VERSION ""

NS_ :

BS_:

BU_: ARS_FD WPC_FD WPC2_FD SCM_FD SHVU_FRNT_FD GW_SAU_DRV_FD GW_PSU_AST_FD GW_PSU_3RD_FD RCS_FD GW_PSU_RL_FD RCM_FD SHVU_3RD_FD SHVU_RR_FD PSB_FD ATS_FD GW_PSU_RR_FD SHVU_RL_FD RWPC_FD CGW_CCU OHCL_FD SHVU_REAR_FD BLTN_CAM_FD SGU_FD GW_PSU_DRV_FD FCS_FD

BO_ 3221225472 VECTOR__INDEPENDENT_SIG_MSG: 0 Vector__XXX
 SG_ dummy_GST_BLTN_CAM_Byte : 0|64@1+ (1,0) [0|0] "" Vector__XXX

BO_ 1 dummy_795_GST_BLTN_CAM: 8 Vector__XXX

BO_ 1941 dummy_GST_BLTN_CAM: 8 Vector__XXX
 SG_ dummy_GST_BLTN_CAM_Byte : 0|64@1+ (1,0) [0|0] ""  BLTN_CAM_FD

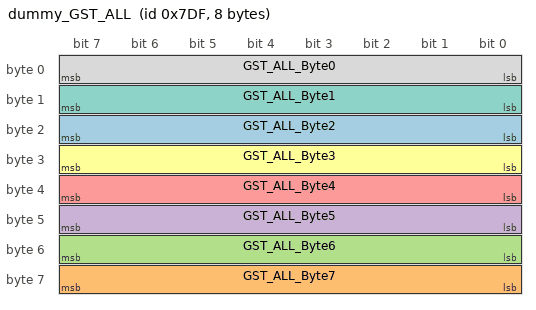
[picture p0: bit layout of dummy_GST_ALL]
BO_ 2015 dummy_GST_ALL: 8 CGW_CCU
 SG_ GST_ALL_Byte2 : 16|8@1+ (1,0) [0|0] "" Vector__XXX
 SG_ GST_ALL_Byte7 : 56|8@1+ (1,0) [0|0] "" Vector__XXX
 SG_ GST_ALL_Byte6 : 48|8@1+ (1,0) [0|0] ""  ARS_FD,ATS_FD,CGW_CCU,FCS_FD,GW_PSU_3RD_FD,GW_PSU_AST_FD,GW_PSU_DRV_FD,GW_PSU_RL_FD,GW_PSU_RR_FD,GW_SAU_DRV_FD,OHCL_FD,PSB_FD,RCM_FD,RCS_FD,RWPC_FD,SCM_FD,SGU_FD,SHVU_3RD_FD,SHVU_FRNT_FD,SHVU_REAR_FD,SHVU_RL_FD,SHVU_RR_FD,WPC2_FD,WPC_FD
 SG_ GST_ALL_Byte5 : 40|8@1+ (1,0) [0|0] ""  ARS_FD,ATS_FD,CGW_CCU,FCS_FD,GW_PSU_3RD_FD,GW_PSU_AST_FD,GW_PSU_DRV_FD,GW_PSU_RL_FD,GW_PSU_RR_FD,GW_SAU_DRV_FD,OHCL_FD,PSB_FD,RCM_FD,RCS_FD,RWPC_FD,SCM_FD,SGU_FD,SHVU_3RD_FD,SHVU_FRNT_FD,SHVU_REAR_FD,SHVU_RL_FD,SHVU_RR_FD,WPC2_FD,WPC_FD
 SG_ GST_ALL_Byte4 : 32|8@1+ (1,0) [0|0] ""  ARS_FD,ATS_FD,CGW_CCU,FCS_FD,GW_PSU_3RD_FD,GW_PSU_AST_FD,GW_PSU_DRV_FD,GW_PSU_RL_FD,GW_PSU_RR_FD,GW_SAU_DRV_FD,OHCL_FD,PSB_FD,RCM_FD,RCS_FD,RWPC_FD,SCM_FD,SGU_FD,SHVU_3RD_FD,SHVU_FRNT_FD,SHVU_REAR_FD,SHVU_RL_FD,SHVU_RR_FD,WPC2_FD,WPC_FD
 SG_ GST_ALL_Byte3 : 24|8@1+ (1,0) [0|0] ""  ARS_FD,ATS_FD,CGW_CCU,FCS_FD,GW_PSU_3RD_FD,GW_PSU_AST_FD,GW_PSU_DRV_FD,GW_PSU_RL_FD,GW_PSU_RR_FD,GW_SAU_DRV_FD,OHCL_FD,PSB_FD,RCM_FD,RCS_FD,RWPC_FD,SCM_FD,SGU_FD,SHVU_3RD_FD,SHVU_FRNT_FD,SHVU_REAR_FD,SHVU_RL_FD,SHVU_RR_FD,WPC2_FD,WPC_FD
 SG_ GST_ALL_Byte1 : 8|8@1+ (1,0) [0|0] ""  ARS_FD,ATS_FD,CGW_CCU,FCS_FD,GW_PSU_3RD_FD,GW_PSU_AST_FD,GW_PSU_DRV_FD,GW_PSU_RL_FD,GW_PSU_RR_FD,GW_SAU_DRV_FD,OHCL_FD,PSB_FD,RCM_FD,RCS_FD,RWPC_FD,SCM_FD,SGU_FD,SHVU_3RD_FD,SHVU_FRNT_FD,SHVU_REAR_FD,SHVU_RL_FD,SHVU_RR_FD,WPC2_FD,WPC_FD
 SG_ GST_ALL_Byte0 : 0|8@1+ (1,0) [0|0] ""  ARS_FD,ATS_FD,BLTN_CAM_FD,CGW_CCU,FCS_FD,GW_PSU_3RD_FD,GW_PSU_AST_FD,GW_PSU_DRV_FD,GW_PSU_RL_FD,GW_PSU_RR_FD,GW_SAU_DRV_FD,OHCL_FD,PSB_FD,RCM_FD,RCS_FD,RWPC_FD,SCM_FD,SGU_FD,SHVU_3RD_FD,SHVU_FRNT_FD,SHVU_REAR_FD,SHVU_RL_FD,SHVU_RR_FD,WPC2_FD,WPC_FD

BO_ 1949 dummy_BLTN_CAM_GST: 8 BLTN_CAM_FD
 SG_ dummy_BLTN_CAM_GST_Byte : 0|64@1- (1,0) [0|0] "" Vector__XXX

BO_ 956 BLTN_CAM_FD_02_200ms: 24 BLTN_CAM_FD
 SG_ BLTN_CAM_FD_Crc2Val : 0|16@1+ (1,0) [0|0] "" Vector__XXX
 SG_ BLTN_CAM_Set_EV_BfrTime : 102|5@1+ (1,0) [0|0] ""  CGW_CCU
 SG_ BLTN_CAM_Set_EV_AftTime : 107|5@1+ (1,0) [0|0] ""  CGW_CCU
 SG_ BLTN_CAM_Set_Drv_TML_Int : 112|4@1+ (1,0) [0|0] ""  CGW_CCU
 SG_ BLTN_CAM_SenSet_DEV : 116|4@1+ (1,0) [0|0] ""  CGW_CCU
 SG_ BLTN_CAM_SenSet_PEV : 120|4@1+ (1,0) [0|0] ""  CGW_CCU
 SG_ BLTN_CAM_Set_FR_Ver_Pos : 128|5@1+ (1,0) [0|0] ""  CGW_CCU
 SG_ BLTN_CAM_Set_RR_Ver_Pos : 133|5@1+ (1,0) [0|0] ""  CGW_CCU
 SG_ BLTN_CAM_Set_PEV_AppNoti : 138|2@1+ (1,0) [0|0] ""  CGW_CCU
 SG_ BLTN_CAM_Set_WiFi_AutoOn : 140|2@1+ (1,0) [0|0] ""  CGW_CCU
 SG_ BLTN_CAM_StrgPropSet : 142|4@1+ (1,0) [0|0] ""  CGW_CCU
 SG_ BLTN_CAM_File_DEL_CPY_Op_State : 146|4@1+ (1,0) [0|0] ""  CGW_CCU
 SG_ BLTN_CAM_File_DEL_CPY_NumTot : 150|16@1+ (1,0) [0|0] ""  CGW_CCU
 SG_ BLTN_CAM_FD_AlvCnt2Val : 16|8@1+ (1,0) [0|0] "" Vector__XXX
 SG_ BLTN_CAM_File_DEL_CPYed_Num : 166|16@1+ (1,0) [0|0] ""  CGW_CCU
 SG_ BLTN_CAM_Set_PMD : 24|2@1+ (1,0) [0|0] ""  CGW_CCU
 SG_ BLTN_CAM_Set_PMDEV : 26|2@1+ (1,0) [0|0] ""  CGW_CCU
 SG_ BLTN_CAM_RanSet_PMDR : 28|4@1+ (1,0) [0|0] ""  CGW_CCU
 SG_ BLTN_CAM_MaxRanSet_PMDR : 32|4@1+ (1,0) [0|0] ""  CGW_CCU
 SG_ BLTN_CAM_Set_PMDTime : 36|8@1+ (1,0) [0|0] ""  CGW_CCU
 SG_ BLTN_CAM_RecSet_OWD : 64|2@1+ (1,0) [0|0] ""  CGW_CCU
 SG_ BLTN_CAM_RecSet_DEV : 66|2@1+ (1,0) [0|0] ""  CGW_CCU
 SG_ BLTN_CAM_RecSet_OWP : 68|2@1+ (1,0) [0|0] ""  CGW_CCU
 SG_ BLTN_CAM_RecSet_PEV : 70|2@1+ (1,0) [0|0] ""  CGW_CCU
 SG_ BLTN_CAM_AudRec_Set : 72|2@1+ (1,0) [0|0] ""  CGW_CCU
 SG_ BLTN_CAM_Set_Tim_Stm : 74|2@1+ (1,0) [0|0] ""  CGW_CCU
 SG_ BLTN_CAM_Set_Spd_Stm : 76|2@1+ (1,0) [0|0] ""  CGW_CCU
 SG_ BLTN_CAM_Set_Locatn_Stm : 78|2@1+ (1,0) [0|0] ""  CGW_CCU
 SG_ BLTN_CAM_Set_TrnSig_Stm : 80|2@1+ (1,0) [0|0] ""  CGW_CCU
 SG_ BLTN_CAM_Set_AclBrk_Stm : 82|2@1+ (1,0) [0|0] ""  CGW_CCU
 SG_ BLTN_CAM_Set_GearPos_Stm : 84|2@1+ (1,0) [0|0] ""  CGW_CCU
 SG_ BLTN_CAM_Set_EVSen_Stm : 86|2@1+ (1,0) [0|0] ""  CGW_CCU
 SG_ BLTN_CAM_Set_StrAngl_Stm : 88|2@1+ (1,0) [0|0] ""  CGW_CCU
 SG_ BLTN_CAM_Set_EV_RecMaxTime : 90|2@1+ (1,0) [0|0] ""  CGW_CCU
 SG_ BLTN_CAM_Set_PrkTime : 94|8@1+ (1,0) [0|0] "Hour"  CGW_CCU

BO_ 274 HU_USM_02_00ms: 32 CGW_CCU
 SG_ HU_USM_Crc2Val : 0|16@1+ (1,0) [0|0] "" Vector__XXX
 SG_ CF_AVN_CluRheostatLvl : 113|5@1+ (1,0) [0|0] "" Vector__XXX
 SG_ CF_AVN_EVReset : 118|2@1+ (1,0) [0|0] "" Vector__XXX
 SG_ CF_AVN_UnitReset : 120|2@1+ (1,0) [0|0] "" Vector__XXX
 SG_ CF_AVN_IcyRoadWarn : 122|2@1+ (1,0) [0|0] "" Vector__XXX
 SG_ CF_AVN_CluServiceReminderReset : 124|2@1+ (1,0) [0|0] "" Vector__XXX
 SG_ CF_AVN_CluUSMReset : 126|2@1+ (1,0) [0|0] ""  ARS_FD,ATS_FD,BLTN_CAM_FD,GW_PSU_3RD_FD,GW_PSU_AST_FD,GW_PSU_DRV_FD,GW_PSU_RL_FD,GW_PSU_RR_FD,GW_SAU_DRV_FD,RCM_FD,RWPC_FD,SGU_FD,SHVU_FRNT_FD,SHVU_REAR_FD,SHVU_RL_FD,SHVU_RR_FD,WPC2_FD,WPC_FD
 SG_ C_HCIMSWeightNValueSet : 128|4@1+ (1,0) [0|0] "" Vector__XXX
 SG_ C_HCIMSHeightNvalueSet : 132|4@1+ (1,0) [0|0] "" Vector__XXX
 SG_ CF_AVN_HCIMSButtonCommand : 136|4@1+ (1,0) [0|0] "" Vector__XXX
 SG_ C_HCIMSSitHeightNValueSet : 140|4@1+ (1,0) [0|0] "" Vector__XXX
 SG_ CF_AVN_BodySpprtSet : 152|2@1+ (1,0) [0|0] ""  GW_PSU_DRV_FD,GW_SAU_DRV_FD
 SG_ HU_USM_AlvCnt2Val : 16|8@1+ (1,0) [0|0] "" Vector__XXX
 SG_ CF_AVN_AirSptTimeNValueSet : 161|3@1+ (1,0) [0|0] ""  GW_SAU_DRV_FD
 SG_ CF_AVN_AirSptStrNValue : 164|2@1+ (1,0) [0|0] ""  GW_SAU_DRV_FD
 SG_ CF_AVN_SeatDrvModNValueSet : 166|2@1+ (1,0) [0|0] ""  GW_PSU_DRV_FD,GW_SAU_DRV_FD
 SG_ C_SmrtSldngDrNValueSet : 176|3@1+ (1,0) [0|0] "" Vector__XXX
 SG_ CF_AVN_TurboPressureUnit : 179|3@1+ (1,0) [0|0] "" Vector__XXX
 SG_ CF_AVN_CluTorqueUnit : 182|2@1+ (1,0) [0|0] "" Vector__XXX
 SG_ CF_AVN_MoodLpRedNValueSet : 192|10@1+ (1,0) [0|0] "" Vector__XXX
 SG_ CF_AVN_MoodLpGreenNValueSet : 202|10@1+ (1,0) [0|0] "" Vector__XXX
 SG_ CF_AVN_MoodLpBlueNValueSet : 212|10@1+ (1,0) [0|0] "" Vector__XXX
 SG_ CF_AVN_MoodLpBrightNValueSet : 223|9@1+ (1,0) [0|0] "" Vector__XXX
 SG_ CF_AVN_HBANValueSet : 232|2@1+ (1,0) [0|0] "" Vector__XXX
 SG_ CF_AVN_IFSActVehSpd_Set : 234|4@1+ (1,0) [0|0] "" Vector__XXX
 SG_ C_MoodLpDrivingNValue : 238|2@1+ (1,0) [0|0] "" Vector__XXX
 SG_ HU_DrivingPostureAssistUSMSet : 24|4@1+ (1,0) [0|0] "" Vector__XXX
 SG_ C_MoodLPDrivemodeNValue : 240|2@1+ (1,0) [0|0] "" Vector__XXX
 SG_ CF_AVN_SVMAutoOnNvalueSet : 242|2@1+ (1,0) [0|0] "" Vector__XXX
 SG_ CF_AVN_DAW_LVDANValueSet : 244|2@1+ (1,0) [0|0] "" Vector__XXX
 SG_ CF_AVN_Clu3dDepthSet : 248|3@1+ (1,0) [0|0] "" Vector__XXX
 SG_ C_MoodLpFadeNValue : 251|2@1+ (1,0) [0|0] ""  ATS_FD
 SG_ HU_DrvCushAirSprtUSMSet : 28|3@1+ (1,0) [0|0] "" Vector__XXX
 SG_ HU_AstCushAirSprtUSMSet : 31|3@1+ (1,0) [0|0] "" Vector__XXX
 SG_ HU_DrvStrchMassageSwSet : 34|2@1+ (1,0) [0|0] "" Vector__XXX
 SG_ HU_DrvStrchMassageModeUSMSet : 36|3@1+ (1,0) [0|0] "" Vector__XXX
 SG_ HU_DrvStrchMassageStrengthUSMSet : 39|3@1+ (1,0) [0|0] "" Vector__XXX
 SG_ HU_DrvStrchMassageTimeUSMSet : 42|3@1+ (1,0) [0|0] "" Vector__XXX
 SG_ HU_AstStrchMassageSwSet : 45|2@1+ (1,0) [0|0] "" Vector__XXX
 SG_ HU_AstStrchMassageModeUSMSet : 47|3@1+ (1,0) [0|0] "" Vector__XXX
 SG_ HU_AstStrchMassageStrengthUSMSet : 50|3@1+ (1,0) [0|0] "" Vector__XXX
 SG_ HU_AstStrchMassageTimeUSMSet : 53|3@1+ (1,0) [0|0] "" Vector__XXX
 SG_ CF_AVN_CluWelcomeSnd : 64|2@1+ (1,0) [0|0] "" Vector__XXX
 SG_ CF_AVN_CluServiceReminderSet : 72|2@1+ (1,0) [0|0] "" Vector__XXX
 SG_ CF_AVN_CluTransmissionDisp : 74|2@1+ (1,0) [0|0] "" Vector__XXX
 SG_ CF_AVN_CluWiperLight : 76|2@1+ (1,0) [0|0] "" Vector__XXX
 SG_ CF_AVN_CluRoadInfoGuide : 78|2@1+ (1,0) [0|0] "" Vector__XXX
 SG_ CF_AVN_CluUserSettingPeriod : 81|7@1+ (1,0) [0|0] "" Vector__XXX
 SG_ CF_AVN_CluFuelEconUnit_mi : 91|2@1+ (1,0) [0|0] "" Vector__XXX
 SG_ CF_AVN_CluFuelEconUnit_km : 93|2@1+ (1,0) [0|0] "" Vector__XXX
 SG_ CF_AVN_CluUserSettingDistance : 95|17@1+ (1,0) [0|0] "" Vector__XXX

BO_ 686 HU_Car_01_200ms: 16 CGW_CCU
 SG_ HU_Car_Crc1Val : 0|16@1+ (1,0) [0|0] "" Vector__XXX
 SG_ HU_Car_AlvCnt1Val : 16|8@1+ (1,0) [0|0] "" Vector__XXX
 SG_ HU_MKBD_ModeSwitch : 66|2@1+ (1,0) [0|0] "" Vector__XXX
 SG_ HU_VehiclePwr : 68|4@1+ (1,0) [0|0] ""  BLTN_CAM_FD,SGU_FD
 SG_ HU_BtnShowReq : 72|3@1+ (1,0) [0|0] "" Vector__XXX
 SG_ HU_ADMSettingState : 75|3@1+ (1,0) [0|0] "" Vector__XXX
 SG_ HU_PwrState : 80|4@1+ (1,0) [0|0] ""  BLTN_CAM_FD
 SG_ HU_LCDState : 84|3@1+ (1,0) [0|0] "" Vector__XXX

BO_ 957 BLTN_CAM_FD_STAT_01_200ms: 24 BLTN_CAM_FD
 SG_ BLTN_CAM_FD_STAT_Crc1Val : 0|16@1+ (1,0) [0|0] "" Vector__XXX
 SG_ BLTN_CAM_Prk_Oprable_Time : 100|8@1+ (1,0) [0|0] "Hour"  CGW_CCU
 SG_ BLTN_CAM_Prk_Oprable_Time_Max : 108|8@1+ (1,0) [0|0] "Hour"  CGW_CCU
 SG_ BLTN_CAM_AuxBat_Conn_State : 116|2@1+ (1,0) [0|0] ""  CGW_CCU
 SG_ BLTN_CAM_AuxBat_CapPer : 118|7@1+ (1,0) [0|0] "%"  CGW_CCU
 SG_ BLTN_CAM_SWVerMajor : 128|7@1+ (1,0) [0|0] ""  CGW_CCU
 SG_ BLTN_CAM_SWVerMinor1 : 136|7@1+ (1,0) [0|0] ""  CGW_CCU
 SG_ BLTN_CAM_SWVerMinor2 : 144|7@1+ (1,0) [0|0] ""  CGW_CCU
 SG_ BLTN_CAM_SWVerMinor3 : 152|7@1+ (1,0) [0|0] ""  CGW_CCU
 SG_ BLTN_CAM_FD_STAT_AlvCnt1Val : 16|8@1+ (1,0) [0|0] "" Vector__XXX
 SG_ BLTN_CAM_SD_Card_Manufacturer : 160|3@1+ (1,0) [0|0] ""  CGW_CCU
 SG_ BLTN_CAM_SD_Card_Cap_Class : 163|3@1+ (1,1) [0|0] ""  CGW_CCU
 SG_ BLTN_CAM_PMD_Oprable_Time : 24|8@1+ (1,0) [0|0] ""  CGW_CCU
 SG_ BLTN_CAM_PMD_Oprable_Time_Max : 32|8@1+ (1,0) [0|0] ""  CGW_CCU
 SG_ BLTN_CAM_RecSta_PMD : 40|2@1+ (1,0) [0|0] ""  CGW_CCU
 SG_ BLTN_CAM_State : 64|4@1+ (1,0) [0|0] ""  CGW_CCU
 SG_ BLTN_CAM_SD_Card_State : 68|4@1+ (1,0) [0|0] ""  CGW_CCU
 SG_ BLTN_CAM_RecSta_OWD : 72|2@1+ (1,0) [0|0] ""  CGW_CCU
 SG_ BLTN_CAM_RecSta_DEV : 74|2@1+ (1,0) [0|0] ""  CGW_CCU
 SG_ BLTN_CAM_RecSta_MAR : 76|2@1+ (1,0) [0|0] ""  CGW_CCU
 SG_ BLTN_CAM_RecSta_TML : 78|2@1+ (1,0) [0|0] ""  CGW_CCU
 SG_ BLTN_CAM_RecSta_OWP : 80|2@1+ (1,0) [0|0] ""  CGW_CCU
 SG_ BLTN_CAM_RecSta_PEV : 82|2@1+ (1,0) [0|0] ""  CGW_CCU
 SG_ BLTN_CAM_Prk_EV_Cnt : 84|8@1+ (1,0) [0|0] ""  CGW_CCU
 SG_ BLTN_CAM_Prk_Oped_Time : 92|8@1+ (1,0) [0|0] "Hour"  CGW_CCU

BO_ 69 HTCU_04_10ms: 24 CGW_CCU
 SG_ HTCU_Crc4Val : 0|16@1+ (1,0) [0|0] "" Vector__XXX
 SG_ HTCU_CtrlablSta : 101|2@1+ (1,0) [0|0] "" Vector__XXX
 SG_ HTCU_PrgrmSta : 104|6@1+ (1,0) [0|0] "" Vector__XXX
 SG_ HTCU_FsCltchLmphmActvSta : 110|2@1+ (1,0) [0|0] "" Vector__XXX
 SG_ HTCU_FsIdleTrgtRpmVal : 112|8@1+ (10,0) [0|0] "rpm" Vector__XXX
 SG_ HTCU_FsAddtnlTqLssPcVal : 120|8@1+ (0.390625,0) [0|0] "%" Vector__XXX
 SG_ HTCU_FsEngTqRdctnPcVal : 128|8@1+ (0.390625,0) [0|0] "%" Vector__XXX
 SG_ HTCU_LnPrsBarVal : 136|8@1+ (0.1,0) [0|0] "Bar" Vector__XXX
 SG_ HTCU_RapidKDReq : 144|2@1+ (1,0) [0|0] "" Vector__XXX
 SG_ HTCU_CurrGearSta : 146|4@1+ (1,0) [0|0] "" Vector__XXX
 SG_ HTCU_GearShftUpDisGSI : 150|2@1+ (1,0) [0|0] "" Vector__XXX
 SG_ HTCU_GearShftDnDisGSI : 152|2@1+ (1,0) [0|0] "" Vector__XXX
 SG_ HTCU_TrgtGearStaGSI : 154|4@1+ (1,0) [0|0] "" Vector__XXX
 SG_ HTCU_SolBSta : 158|2@1+ (1,0) [0|0] "" Vector__XXX
 SG_ HTCU_AlvCnt4Val : 16|8@1+ (1,0) [0|0] "" Vector__XXX
 SG_ HTCU_TqRdctnNegativePcVal : 160|10@1- (0.390625,0) [0|0] "rpm" Vector__XXX
 SG_ HTCU_TrgtGearSta : 24|4@1+ (1,0) [0|0] "" Vector__XXX
 SG_ HTCU_RdySta : 28|2@1+ (1,0) [0|0] "" Vector__XXX
 SG_ HTCU_GearChgSta : 30|2@1+ (1,0) [0|0] "" Vector__XXX
 SG_ HTCU_TqRdctnPcVal : 32|9@1+ (0.390625,0) [0|0] "%" Vector__XXX
 SG_ HTCU_FltSta : 41|3@1+ (1,0) [0|0] "" Vector__XXX
 SG_ HTCU_GearSlctrDis : 44|4@1+ (1,0) [0|0] ""  BLTN_CAM_FD
 SG_ HTCU_SlwTqRdctnPcVal : 48|9@1+ (0.390625,0) [0|0] "%" Vector__XXX
 SG_ HTCU_PddlShftUpDn : 57|2@1+ (1,0) [0|0] "" Vector__XXX
 SG_ HTCU_FanCtrlReq : 62|2@1+ (1,0) [0|0] "" Vector__XXX
 SG_ HTCU_VehSpdKphVal : 64|8@1+ (1,0) [0|0] "kph" Vector__XXX
 SG_ HTCU_VehSpdDcmlKphVal : 72|8@1+ (0.0078125,0) [0|0] "kph" Vector__XXX
 SG_ HTCU_HvOpuSpdCmdRpmVal : 80|8@1+ (20,0) [0|0] "rpm" Vector__XXX
 SG_ HTCU_TrgtShftClsCCanSta : 96|5@1+ (1,0) [0|0] "" Vector__XXX

BO_ 685 HU_BLTN_CAM_02_200ms: 16 CGW_CCU
 SG_ HU_BLTN_CAM_Crc2Val : 0|16@1+ (1,0) [0|0] "" Vector__XXX
 SG_ HU_BLTN_CAM_AlvCnt2Val : 16|8@1+ (1,0) [0|0] "" Vector__XXX
 SG_ HU_BLTN_CAM_UI_Mode : 64|4@1+ (1,0) [0|0] ""  BLTN_CAM_FD
 SG_ HU_BLTN_CAM_Display : 68|3@1+ (1,0) [0|0] ""  BLTN_CAM_FD

BO_ 138 HU_GW_01_00ms: 32 CGW_CCU
 SG_ HU_GW_Crc1Val : 0|16@1+ (1,0) [0|0] "" Vector__XXX
 SG_ HU_TgSoc_QcChg_Set : 104|8@1+ (0.5,0) [0|100] "%" Vector__XXX
 SG_ HU_UserApproval : 120|4@1+ (1,0) [0|0] "" Vector__XXX
 SG_ HU_OtaInfomationReq : 124|4@1+ (1,0) [0|0] "" Vector__XXX
 SG_ HU_ICU_RearDefSet : 152|2@1+ (1,0) [0|0] "" Vector__XXX
 SG_ HU_CDMOpenCmd : 156|2@1+ (1,0) [0|0] "" Vector__XXX
 SG_ C_PreCrankReq : 158|2@1+ (1,0) [0|0] ""  BLTN_CAM_FD
 SG_ HU_GW_AlvCnt1Val : 16|8@1+ (1,0) [0|0] "" Vector__XXX
 SG_ C_TeleAstSeatOpCmdIBOX : 160|4@1+ (1,0) [0|0] ""  GW_PSU_AST_FD,SHVU_FRNT_FD
 SG_ C_TeleDrvSeatOpCmdIBOX : 164|4@1+ (1,0) [0|0] ""  GW_PSU_AST_FD,GW_PSU_DRV_FD,SHVU_FRNT_FD
 SG_ C_TeleRRSeatOpCmdIBOX : 168|4@1+ (1,0) [0|0] ""  ATS_FD,GW_PSU_RL_FD,GW_PSU_RR_FD,SHVU_FRNT_FD,SHVU_REAR_FD,SHVU_RR_FD
 SG_ C_TeleRLSeatOpCmdIBOX : 172|4@1+ (1,0) [0|0] ""  ATS_FD,GW_PSU_RL_FD,GW_PSU_RR_FD,SHVU_FRNT_FD,SHVU_REAR_FD,SHVU_RL_FD
 SG_ HU_StrgWhlHeatingSet_VR : 195|3@1+ (1,0) [0|0] "" Vector__XXX
 SG_ AVN_VGS_SET : 200|2@1+ (1,0) [0|0] "" Vector__XXX
 SG_ MODE_VCU_SET2 : 202|3@1+ (1,0) [0|0] "" Vector__XXX
 SG_ AVN_DriftMode_SET : 205|3@1+ (1,0) [0|0] "" Vector__XXX
 SG_ AVN_NduranceRace_SET : 208|3@1+ (1,0) [0|0] "" Vector__XXX
 SG_ AVN_MaxRange_SET : 211|3@1+ (1,0) [0|0] "" Vector__XXX
 SG_ HU_MKBD_TouchSensSet : 217|3@1+ (1,0) [0|0] "" Vector__XXX
 SG_ AVN_NTDBalance_SET : 220|4@1+ (1,0) [0|0] "" Vector__XXX
 SG_ LaunchControl_Activate_EV : 224|2@1+ (1,0) [0|0] "" Vector__XXX
 SG_ LaunchControl_GripLevel_Reset : 226|2@1+ (1,0) [0|0] "" Vector__XXX
 SG_ LaunchControl_GripLevel_Set : 228|3@1+ (1,0) [0|0] "" Vector__XXX
 SG_ MODE_Drift_TCS_SET : 232|4@1+ (1,0) [0|0] "" Vector__XXX
 SG_ MODE_Drift_VDC_SET : 236|3@1+ (1,0) [0|0] "" Vector__XXX
 SG_ HU_Popupdown_Req : 24|2@1+ (1,0) [0|0] "" Vector__XXX
 SG_ MODE_Drift_MDPS_SET : 240|2@1+ (1,0) [0|0] "" Vector__XXX
 SG_ MODE_Drift_ECS_SET : 242|2@1+ (1,0) [0|0] "" Vector__XXX
 SG_ MODE_Drift_ELSD_SET : 244|2@1+ (1,0) [0|0] "" Vector__XXX
 SG_ HU_NCond_DragSet : 246|2@1+ (1,0) [0|0] "" Vector__XXX
 SG_ HU_NCond_TrackSet : 248|2@1+ (1,0) [0|0] "" Vector__XXX
 SG_ AVN_Npedal_SET : 250|3@1+ (1,0) [0|0] "" Vector__XXX
 SG_ AVN_NTD_SET : 253|3@1+ (1,0) [0|0] "" Vector__XXX
 SG_ HU_PopupAgreement_Push : 26|2@1+ (1,0) [0|0] "" Vector__XXX
 SG_ SWRC_Sensitivity_SET : 66|2@1+ (1,0) [0|0] "" Vector__XXX
 SG_ HU_ChgInCurrModSet : 75|3@1+ (1,0) [0|0] "" Vector__XXX
 SG_ HU_EV_WinterMode : 86|2@1+ (1,0) [0|0] "" Vector__XXX
 SG_ HU_TgSoc_ScChg_Set : 96|8@1+ (0.5,0) [0|100] "%" Vector__XXX

BO_ 64 TCU_01_10ms: 32 CGW_CCU
 SG_ TCU_Crc1Val : 0|16@1+ (1,0) [0|0] "" Vector__XXX
 SG_ TCU_DcmlVehSpdKphVal : 104|8@1+ (0.0078125,0) [0|0] "km/h" Vector__XXX
 SG_ TCU_SprkRtrdReq : 112|8@1+ (0.375,-23.625) [0|0] "˚" Vector__XXX
 SG_ TCU_EngRpmDisSta : 120|2@1+ (1,0) [0|0] "" Vector__XXX
 SG_ TCU_GearLmpBlnkngReq : 122|2@1+ (1,0) [0|0] "" Vector__XXX
 SG_ TCU_FuelCutInhbtReq : 124|2@1+ (1,0) [0|0] "" Vector__XXX
 SG_ TCU_IdleUpReq : 126|2@1+ (1,0) [0|0] "" Vector__XXX
 SG_ TCU_EngRpmDis : 128|16@1+ (0.25,0) [0|0] "rpm" Vector__XXX
 SG_ TCU_SlpVal : 144|6@1+ (0.5,-16) [0|0] "%" Vector__XXX
 SG_ TCU_EngSpdIncReq : 150|2@1+ (1,0) [0|0] "" Vector__XXX
 SG_ TCU_ObdSta : 152|3@1+ (1,0) [0|0] "" Vector__XXX
 SG_ TCU_SprtyIndxSta : 155|5@1+ (1,0) [0|0] "" Vector__XXX
 SG_ TCU_AlvCnt1Val : 16|8@1+ (1,0) [0|0] "" Vector__XXX
 SG_ TCU_DrvngModDis : 160|3@1+ (1,0) [0|0] "" Vector__XXX
 SG_ TCU_DrvngModReq : 163|3@1+ (1,0) [0|0] "" Vector__XXX
 SG_ TCU_SmrtShftSta : 166|2@1+ (1,0) [0|0] "" Vector__XXX
 SG_ TCU_LupTrgtEngSpdVal : 168|8@1+ (10,500) [0|0] "rpm" Vector__XXX
 SG_ TCU_FrtStcShftSta : 176|2@1+ (1,0) [0|0] "" Vector__XXX
 SG_ TCU_IsgInhbtReq : 178|2@1+ (1,0) [0|0] "" Vector__XXX
 SG_ TCU_CdaInhbtReq : 180|2@1+ (1,0) [0|0] "" Vector__XXX
 SG_ TCU_BrkOnReq : 182|2@1+ (1,0) [0|0] "" Vector__XXX
 SG_ TCU_TqGrdntLimVal : 184|8@1+ (10,0) [0|0] "Nm/s" Vector__XXX
 SG_ TCU_NetrlCtrlSta : 192|2@1+ (1,0) [0|0] "" Vector__XXX
 SG_ TCU_ShftPtrnSta : 194|4@1+ (1,0) [0|0] "" Vector__XXX
 SG_ TCU_VgisInhbtReq : 198|2@1+ (1,0) [0|0] "" Vector__XXX
 SG_ TCU_EngTqIncReqVal : 200|12@1- (1,0) [0|0] "Nm" Vector__XXX
 SG_ TCU_EPBReq : 212|1@1+ (1,0) [0|0] "" Vector__XXX
 SG_ IMT_EOLstate : 213|1@1+ (1,0) [0|0] "" Vector__XXX
 SG_ IMT_DisCmd : 214|2@1+ (1,0) [0|0] "" Vector__XXX
 SG_ IMT_CltchPdlPos : 216|8@1+ (0.390625,0) [0|0] "%" Vector__XXX
 SG_ DCT_RegenInhbt : 224|2@1+ (1,0) [0|0] "" Vector__XXX
 SG_ DCT_EngIdleReq : 226|2@1+ (1,0) [0|0] "" Vector__XXX
 SG_ DCT_CltchState : 228|2@1+ (1,0) [0|0] "" Vector__XXX
 SG_ DCT_FuelCutReq : 230|2@1+ (1,0) [0|0] "" Vector__XXX
 SG_ DCT_TqIncReq : 232|2@1+ (1,0) [0|0] "" Vector__XXX
 SG_ DCT_CrpTqReq : 234|10@1+ (1,-512) [0|0] "Nm" Vector__XXX
 SG_ DCT_ShftTqReq : 244|12@1- (1,0) [0|0] "Nm" Vector__XXX
 SG_ TCU_GearSlctDis : 32|4@1+ (1,0) [0|0] ""  BLTN_CAM_FD,GW_PSU_3RD_FD,GW_PSU_AST_FD,GW_PSU_RL_FD,GW_PSU_RR_FD,SHVU_RL_FD,SHVU_RR_FD
 SG_ TCU_Typ : 36|4@1+ (1,0) [0|0] ""  GW_PSU_3RD_FD,GW_PSU_AST_FD
 SG_ TCU_TqRdctnVal : 40|12@1- (1,0) [0|0] "Nm" Vector__XXX
 SG_ TCU_GearStepTyp : 56|4@1+ (1,0) [0|0] "" Vector__XXX
 SG_ TCU_GearShftSta : 60|2@1+ (1,0) [0|0] "" Vector__XXX
 SG_ TCU_TqCnvrtrSta : 62|2@1+ (1,0) [0|0] "" Vector__XXX
 SG_ TCU_CurrGearSta : 64|4@1+ (1,0) [0|0] "" Vector__XXX
 SG_ TCU_TrgtGearSta : 68|4@1+ (1,0) [0|0] "" Vector__XXX
 SG_ TCU_CluTrgtGearSta : 72|4@1+ (1,0) [0|0] "" Vector__XXX
 SG_ TCH_EngTrgtGearSta : 76|4@1+ (1,0) [0|0] "" Vector__XXX
 SG_ TCU_EngTqLimVal : 80|12@1- (1,0) [0|0] "Nm" Vector__XXX
 SG_ TCU_CluTrgtGearConfg : 92|2@1+ (1,0) [0|0] "" Vector__XXX
 SG_ TCU_VehSpdKphVal : 96|8@1+ (1,0) [0|0] "km/h" Vector__XXX

CM_ BO_ 3221225472 "This is a message for not used signals, created by Vector CANdb++ DBC OLE DB Provider.";
CM_ BO_ 956 "[PE] Periodic and On Event";
CM_ SG_ 956 BLTN_CAM_FD_Crc2Val "BLTN_CAM_FD_CyclicRedundancyCheck2Value";
CM_ SG_ 956 BLTN_CAM_Set_EV_BfrTime "Driving Event Time Setting - Before, Resolution : sec";
CM_ SG_ 956 BLTN_CAM_Set_EV_AftTime "Driving Event Time Setting - After, Resolution : sec";
CM_ SG_ 956 BLTN_CAM_Set_Drv_TML_Int "Record Set of Time-lapse Interval, Resolution : sec";
CM_ SG_ 956 BLTN_CAM_SenSet_DEV "Set of Event  Detection Sensitivity of Driving Mode";
CM_ SG_ 956 BLTN_CAM_SenSet_PEV "Set of Event  Detection Sensitivity of Parking Mode";
CM_ SG_ 956 BLTN_CAM_Set_FR_Ver_Pos "Front Camera Vertical position setting value.";
CM_ SG_ 956 BLTN_CAM_Set_RR_Ver_Pos "Rear Camera Vertical position setting value.";
CM_ SG_ 956 BLTN_CAM_Set_PEV_AppNoti "Parked Event notification to Connectivity Phone App. On/Off";
CM_ SG_ 956 BLTN_CAM_Set_WiFi_AutoOn "Wifi On/Off User setting";
CM_ SG_ 956 BLTN_CAM_StrgPropSet "Propotion of built-in Cam SD card Propotion set of the Recording Categories";
CM_ SG_ 956 BLTN_CAM_File_DEL_CPY_Op_State "Bulil in Cam Fily copy and delete operating state.";
CM_ SG_ 956 BLTN_CAM_File_DEL_CPY_NumTot "Number of Copied or Deleted files.";
CM_ SG_ 956 BLTN_CAM_FD_AlvCnt2Val "BLTN_CAM_FD_AliveCounter2Value";
CM_ SG_ 956 BLTN_CAM_File_DEL_CPYed_Num "Total number of the copy or delete file.";
CM_ SG_ 956 BLTN_CAM_Set_PMD "Parked Motion Detection Record Mode On/Off Set";
CM_ SG_ 956 BLTN_CAM_Set_PMDEV "Parked Motion Detection Event Record On/Off Set";
CM_ SG_ 956 BLTN_CAM_RanSet_PMDR "Set of Range level of Parked Motion Detection Record Mode";
CM_ SG_ 956 BLTN_CAM_MaxRanSet_PMDR "Set Level Range of Parked Motion Detection Record Mode";
CM_ SG_ 956 BLTN_CAM_Set_PMDTime "Set the hours of Parked Motion Detection Mode";
CM_ SG_ 956 BLTN_CAM_RecSet_OWD "Record On/Off Set of On While Driving";
CM_ SG_ 956 BLTN_CAM_RecSet_DEV "Record On/Off Set of Driving Event";
CM_ SG_ 956 BLTN_CAM_RecSet_OWP "Record On/Off Set of On While Parked, 0x0(Default) : Parking recording function not supported";
CM_ SG_ 956 BLTN_CAM_RecSet_PEV "Record Set of Parked Event, 0x0(Default) : Parking recording function not supported";
CM_ SG_ 956 BLTN_CAM_AudRec_Set "Audio Record On/Off Set";
CM_ SG_ 956 BLTN_CAM_Set_Tim_Stm "Record Set of Date and Time Stamp";
CM_ SG_ 956 BLTN_CAM_Set_Spd_Stm "Record Set of Speed Stamp";
CM_ SG_ 956 BLTN_CAM_Set_Locatn_Stm "Record Set of Location Stamp";
CM_ SG_ 956 BLTN_CAM_Set_TrnSig_Stm "Record Set of Turn Signal Stamp";
CM_ SG_ 956 BLTN_CAM_Set_AclBrk_Stm "Record Set of Accelerator Brake Stamp";
CM_ SG_ 956 BLTN_CAM_Set_GearPos_Stm "Record Set of Gear Position Stamp";
CM_ SG_ 956 BLTN_CAM_Set_EVSen_Stm "Record Set of Event Sensitivity Stamp";
CM_ SG_ 956 BLTN_CAM_Set_StrAngl_Stm "Record Set of Steering Angle Stamp";
CM_ SG_ 956 BLTN_CAM_Set_EV_RecMaxTime "Record Set of  EV Parking Rec Max Time On/Off";
CM_ SG_ 956 BLTN_CAM_Set_PrkTime "Parking Operation Setting Time, Resolution : hr";
CM_ BO_ 274 "[EC] On Event and On Change";
CM_ SG_ 274 HU_USM_Crc2Val "HU_USM_CyclicRedundancyCheck2Value";
CM_ SG_ 274 CF_AVN_CluRheostatLvl "Request to set CLU rheostat level";
CM_ SG_ 274 CF_AVN_EVReset "Request to reset EV Service (0x1 : EV USM Reset)";
CM_ SG_ 274 CF_AVN_UnitReset "Request to reset Unit setting";
CM_ SG_ 274 CF_AVN_IcyRoadWarn "Request to set CLU icy road warning";
CM_ SG_ 274 CF_AVN_CluServiceReminderReset "Request to reset CLU service reminder";
CM_ SG_ 274 CF_AVN_CluUSMReset "Request to reset all USM service";
CM_ SG_ 274 C_HCIMSWeightNValueSet "This signal is used for Healthcare IMS to input user's weight";
CM_ SG_ 274 C_HCIMSHeightNvalueSet "This signal is used for Healthcare IMS to input user's height";
CM_ SG_ 274 CF_AVN_HCIMSButtonCommand "User's input value in healthcare IMS mode";
CM_ SG_ 274 C_HCIMSSitHeightNValueSet "This signal is used for Healthcare IMS to input user's sitting height";
CM_ SG_ 274 CF_AVN_BodySpprtSet "This signal is for the seat body support USM";
CM_ SG_ 274 HU_USM_AlvCnt2Val "HU_USM_AliveCounter2Value";
CM_ SG_ 274 CF_AVN_AirSptTimeNValueSet "This signal is for the seat massage function time setting";
CM_ SG_ 274 CF_AVN_AirSptStrNValue "This signal is for the seat massage intensity USM";
CM_ SG_ 274 CF_AVN_SeatDrvModNValueSet "This signal is for the auto seat-drivemode user setting menu";
CM_ SG_ 274 CF_AVN_MoodLpRedNValueSet "Request for mood lamp color(Red)";
CM_ SG_ 274 CF_AVN_MoodLpGreenNValueSet "Request for mood lamp color(Green)";
CM_ SG_ 274 CF_AVN_MoodLpBlueNValueSet "Request for mood lamp color(Blue)";
CM_ SG_ 274 CF_AVN_MoodLpBrightNValueSet "Request for mood lamp bright";
CM_ SG_ 274 CF_AVN_HBANValueSet "USM Request for High Beam Assist";
CM_ SG_ 274 CF_AVN_IFSActVehSpd_Set "USM Request for Intelligent Front Lighting System";
CM_ SG_ 274 C_MoodLpDrivingNValue "USM Request value for mood lamp drivng interlock";
CM_ SG_ 274 C_MoodLPDrivemodeNValue "USM request for Mood Lamp color with Drive Mode";
CM_ SG_ 274 CF_AVN_SVMAutoOnNvalueSet "Request for SVM Auto On";
CM_ SG_ 274 CF_AVN_DAW_LVDANValueSet "Request for Front Vehicle Departure Alert";
CM_ SG_ 274 CF_AVN_Clu3dDepthSet "This signal is used for request to set the depth of 3D";
CM_ SG_ 274 C_MoodLpFadeNValue "This signal indicates MLM Fade in/out control.";
CM_ SG_ 274 CF_AVN_CluWelcomeSnd "Request to set CLU welcome soun";
CM_ SG_ 274 CF_AVN_CluServiceReminderSet "Request to set CLU service notification";
CM_ SG_ 274 CF_AVN_CluTransmissionDisp "Request to set CLU transmission display";
CM_ SG_ 274 CF_AVN_CluWiperLight "Request to set CLU wiper & light mode";
CM_ SG_ 274 CF_AVN_CluRoadInfoGuide "Request to set CLU road info guidance";
CM_ SG_ 274 CF_AVN_CluUserSettingPeriod "Request to set CLU sservice period set by user";
CM_ SG_ 274 CF_AVN_CluFuelEconUnit_mi "Cluster setting status for cluster Fuel Economy Unit (mile)";
CM_ SG_ 274 CF_AVN_CluFuelEconUnit_km "Cluster setting status for cluster Fuel Economy unit (km)";
CM_ SG_ 274 CF_AVN_CluUserSettingDistance "Request to set CLU service distance set by user";
CM_ BO_ 686 "[PE] Periodic and On Event";
CM_ SG_ 686 HU_Car_Crc1Val "HU_Car_CyclicRedundancyCheck1Value";
CM_ SG_ 686 HU_Car_AlvCnt1Val "HU_Car_AliveCounter1Value";
CM_ SG_ 686 HU_MKBD_ModeSwitch "This signal is used for the 'AVNT/Climate Switching Keyboard' to switch the display of buttons.";
CM_ SG_ 686 HU_VehiclePwr "Information for the H/U power status for ADM(Accessary Delay Mode)";
CM_ SG_ 686 HU_ADMSettingState "Information for ADM(Accessry Delay Mode) Setting Vaule in HU / Made at 2021.1.25";
CM_ BO_ 957 "[PE] Periodic and On Event";
CM_ SG_ 957 BLTN_CAM_FD_STAT_Crc1Val "BLTN_CAM_FD_STAT_CyclicRedundancyCheck1Value";
CM_ SG_ 957 BLTN_CAM_Prk_Oprable_Time "The hours of Park Mode Operatable, the time is limited by user max oper. Set.";
CM_ SG_ 957 BLTN_CAM_Prk_Oprable_Time_Max "The hours of Park Mode Operatable, the time has no limit.";
CM_ SG_ 957 BLTN_CAM_AuxBat_Conn_State "0x0 : Default / 0x1 : Auxiliary Battery is connected.(P-LBM or B-LBM) / 0x2 : Auxiliary Battery Is not connected. - Auxiliary Battery applicable on this vehicle model / 0x3:  Auxiliary Battery is not connected. ? Auxiliary Battery not applicable on this vehicle model";
CM_ SG_ 957 BLTN_CAM_AuxBat_CapPer "The percentage of Aux. Bat.";
CM_ SG_ 957 BLTN_CAM_SWVerMajor "First Word(ASCII) in Built-in Cam S/W Ver";
CM_ SG_ 957 BLTN_CAM_SWVerMinor1 "Minor1 in Built-in Cam S/W Ver";
CM_ SG_ 957 BLTN_CAM_SWVerMinor2 "Minor2 in Built-in Cam S/W Ver";
CM_ SG_ 957 BLTN_CAM_SWVerMinor3 "Minor3 in Built-in Cam S/W Ver";
CM_ SG_ 957 BLTN_CAM_FD_STAT_AlvCnt1Val "BLTN_CAM_FD_STAT_AliveCounter1Value";
CM_ SG_ 957 BLTN_CAM_SD_Card_Manufacturer "0x0(SD Card not found), 0x1(Micron-Genuine part), 0x2~0x5(Reserved), 0x6(Unknown), 0x7(Invalid)";
CM_ SG_ 957 BLTN_CAM_SD_Card_Cap_Class "0x0(SD Card not found), 0x1(64Gbyte Class), 0x2(128Gbyte Class), 0x3(256Gbyte Class), 0x4(512Gbyte Class), 0x5(1Tbyte Class), 0x6(2Tbyte Class), 0x7(Invalid)";
CM_ SG_ 957 BLTN_CAM_PMD_Oprable_Time "the hours of Parked Motion Detection Mode Operatable";
CM_ SG_ 957 BLTN_CAM_PMD_Oprable_Time_Max "the hours of Parked Motion Detection Mode Operatable Max";
CM_ SG_ 957 BLTN_CAM_RecSta_PMD "This Signal inform recording status of Parked Motion Detection.";
CM_ SG_ 957 BLTN_CAM_State "This Signal is for cluster warning popup.";
CM_ SG_ 957 BLTN_CAM_SD_Card_State "This Signal is for SD card Status in Built-in App menu and CCS Phone App.";
CM_ SG_ 957 BLTN_CAM_RecSta_OWD "This Signal inform recording status of On While Driving.";
CM_ SG_ 957 BLTN_CAM_RecSta_DEV "This Signal inform recording status of Driving Event.";
CM_ SG_ 957 BLTN_CAM_RecSta_MAR "This Signal inform recording status of Manual Recording.";
CM_ SG_ 957 BLTN_CAM_RecSta_TML "This Signal inform recording status of Time-lapse.";
CM_ SG_ 957 BLTN_CAM_RecSta_OWP "This Signal inform recording status of On While Parked.";
CM_ SG_ 957 BLTN_CAM_RecSta_PEV "This Signal inform recording status of Parked Event.";
CM_ SG_ 957 BLTN_CAM_Prk_EV_Cnt "The count number of a parked Event.";
CM_ SG_ 957 BLTN_CAM_Prk_Oped_Time "The Parked Opreated time ingormation";
CM_ BO_ 69 "[P] Periodic";
CM_ SG_ 69 HTCU_Crc4Val "HTCU_CyclicRedundancyCheck4Value";
CM_ SG_ 69 HTCU_PrgrmSta "HTCU_ProgramStatus";
CM_ SG_ 69 HTCU_FsCltchLmphmActvSta "HTCU_FsClutchLimphomeActivationStatus";
CM_ SG_ 69 HTCU_FsIdleTrgtRpmVal "HTCU_FsIdleTargetRpmValue";
CM_ SG_ 69 HTCU_FsAddtnlTqLssPcVal "HTCU_FsAdditionalTorqueLossPcValue";
CM_ SG_ 69 HTCU_FsEngTqRdctnPcVal "HTCU_FsEngineTorqueReductionPcValue";
CM_ SG_ 69 HTCU_LnPrsBarVal "HTCU_LinePressureBarValue";
CM_ SG_ 69 HTCU_RapidKDReq "HTCU_RapidKDRequest";
CM_ SG_ 69 HTCU_CurrGearSta "HTCU_CurrentGearStatus";
CM_ SG_ 69 HTCU_GearShftUpDisGSI "HTCU_GearShiftUpDisplayGSI";
CM_ SG_ 69 HTCU_GearShftDnDisGSI "HTCU_GearShiftDownDisplayGSI";
CM_ SG_ 69 HTCU_TrgtGearStaGSI "HTCU_TargetGearStatusGSI";
CM_ SG_ 69 HTCU_SolBSta "HTCU_SolenoidBStatus";
CM_ SG_ 69 HTCU_AlvCnt4Val "HTCU_AliveCounter4Value";
CM_ SG_ 69 HTCU_TqRdctnNegativePcVal "HTCU_TorqueReductionNegativePcValue";
CM_ SG_ 69 HTCU_TrgtGearSta "HTCU_TargetGearStatus";
CM_ SG_ 69 HTCU_RdySta "HTCU_ReadyStatus";
CM_ SG_ 69 HTCU_GearChgSta "HTCU_GearChangeStatus";
CM_ SG_ 69 HTCU_TqRdctnPcVal "HTCU_TorqueReductionPcValue";
CM_ SG_ 69 HTCU_FltSta "HTCU_FaultStatus";
CM_ SG_ 69 HTCU_GearSlctrDis "HTCU_GearSelectDisplay";
CM_ SG_ 69 HTCU_SlwTqRdctnPcVal "HTCU_SlowTorqueReductionPcValue";
CM_ SG_ 69 HTCU_PddlShftUpDn "Paddle Shift Up(Plus)/Dn(Minus)";
CM_ SG_ 69 HTCU_FanCtrlReq "Fan control request by OPU";
CM_ SG_ 69 HTCU_VehSpdKphVal "HTCU_VehicleSpeedKphValue";
CM_ SG_ 69 HTCU_VehSpdDcmlKphVal "HTCU_VehicleSpeedDecimalKphValue";
CM_ SG_ 69 HTCU_HvOpuSpdCmdRpmVal "HTCU_HvOpuSpeedCommandRpmValue";
CM_ SG_ 69 HTCU_TrgtShftClsCCanSta "HTCU_TargetShiftClassCCanStatus";
CM_ BO_ 685 "[PE] Periodic and On Event";
CM_ SG_ 685 HU_BLTN_CAM_Crc2Val "HU_BLTN_CAM_CyclicRedundancyCheck2Value";
CM_ SG_ 685 HU_BLTN_CAM_AlvCnt2Val "HU_BLTN_CAM_AliveCounter2Value";
CM_ SG_ 685 HU_BLTN_CAM_UI_Mode "Display control of Built-in Cam UI mode. This Signal for Ethernet Type Built-in Cam.";
CM_ SG_ 685 HU_BLTN_CAM_Display "Display control of Built-in Cam UI mode. This Signal for CAN Type Built-in Cam.(with Standard 5th Wide AVNT)";
CM_ BO_ 138 "[EC] On Event and On Change";
CM_ SG_ 138 HU_GW_Crc1Val "HU_GW_CyclicRedundancyCheck1Value";
CM_ SG_ 138 HU_TgSoc_QcChg_Set "<For after OS/DE/SK3 EV>
Target SOC user setting value for fast charger(QC/DC).
- For EV only";
CM_ SG_ 138 HU_ICU_RearDefSet "Rear window defog control";
CM_ SG_ 138 HU_CDMOpenCmd "Command for CDM open/close";
CM_ SG_ 138 C_PreCrankReq "Command for B-CAN wake up signal
(Need to send this signal before other remote commands)";
CM_ SG_ 138 HU_GW_AlvCnt1Val "HU_GW_AliveCounter1Value";
CM_ SG_ 138 C_TeleAstSeatOpCmdIBOX "Command for Remote Seat Heat/Vent control (Passenger)";
CM_ SG_ 138 C_TeleDrvSeatOpCmdIBOX "Command for Remote Seat Heat/Vent control (Driver)";
CM_ SG_ 138 C_TeleRRSeatOpCmdIBOX "Command for Remote Seat Heat/Vent control (Rear Right)";
CM_ SG_ 138 C_TeleRLSeatOpCmdIBOX "Command for Remote Seat Heat/Vent control (Rear Left)";
CM_ SG_ 138 HU_StrgWhlHeatingSet_VR "Command for VR Heating Control (Steering Wheel 1/2step)";
CM_ SG_ 138 MODE_VCU_SET2 "Set the VCU setting in custom mode 2";
CM_ SG_ 138 SWRC_Sensitivity_SET "SWRC_OpticalSwtich_Sensitivity_Setting";
CM_ SG_ 138 HU_ChgInCurrModSet "Charge current set signal";
CM_ SG_ 138 HU_EV_WinterMode "<For after OS/DE/SK3 EV/AE PE EV>

EV Battery temp. up setting on/off 
- setting signal : CR_Bms_WinterMode";
CM_ SG_ 138 HU_TgSoc_ScChg_Set "<For after OS/DE/SK3 EV>
Target SOC user setting value for slow charger(SC/AC).
- For EV only";
CM_ BO_ 64 "[P] Periodic";
CM_ SG_ 64 TCU_Crc1Val "TCU_CyclicRedundancyCheck1Value";
CM_ SG_ 64 TCU_DcmlVehSpdKphVal "TCU_VehicleSpeedDecimalKphValue";
CM_ SG_ 64 TCU_SprkRtrdReq "TCU_SparkRetardAngleValue";
CM_ SG_ 64 TCU_EngRpmDisSta "TCU_EngineRpmDisplayStatus";
CM_ SG_ 64 TCU_GearLmpBlnkngReq "TCU_GearLampBlinkingRequest";
CM_ SG_ 64 TCU_FuelCutInhbtReq "TCU_FuelCutInhibitionRequest";
CM_ SG_ 64 TCU_IdleUpReq "TCU_IdleUpRequest";
CM_ SG_ 64 TCU_EngRpmDis "TCU_EngineRpmDisplay";
CM_ SG_ 64 TCU_SlpVal "TCU_SlopeValue";
CM_ SG_ 64 TCU_EngSpdIncReq "TCU_EngineSpeedIncreaseRequest";
CM_ SG_ 64 TCU_ObdSta "TCU_ObdStatus";
CM_ SG_ 64 TCU_SprtyIndxSta "TCU_SportyIndexStatus";
CM_ SG_ 64 TCU_AlvCnt1Val "TCU_AliveCounter1Value";
CM_ SG_ 64 TCU_DrvngModDis "TCU_DrivingModeDisplay";
CM_ SG_ 64 TCU_DrvngModReq "TCU_DrivingModeRequest";
CM_ SG_ 64 TCU_SmrtShftSta "TCU_SmartShiftStatus";
CM_ SG_ 64 TCU_LupTrgtEngSpdVal "TCU_LupTargetEngineSpeedValue";
CM_ SG_ 64 TCU_FrtStcShftSta "TCU_FirstStaticShiftStatus";
CM_ SG_ 64 TCU_IsgInhbtReq "TCU_IsgInhibitRequest";
CM_ SG_ 64 TCU_CdaInhbtReq "TCU_CdaInhibitRequest";
CM_ SG_ 64 TCU_BrkOnReq "TCU_BrakeOnRequest";
CM_ SG_ 64 TCU_TqGrdntLimVal "TCU_TorqueGradientLimitationValue";
CM_ SG_ 64 TCU_NetrlCtrlSta "TCU_NeutralControlStatus";
CM_ SG_ 64 TCU_ShftPtrnSta "TCU_ShiftPatternStatus";
CM_ SG_ 64 TCU_VgisInhbtReq "TCU_VgisInhibitionRequest";
CM_ SG_ 64 TCU_EngTqIncReqVal "TCU_EngineTorqueIncreaseReqValue";
CM_ SG_ 64 TCU_EPBReq "EPB Request signal for prevent P-D Shock on hill";
CM_ SG_ 64 IMT_EOLstate "Gear Display for EOL mode to cluster. This signal is for IMT system only.";
CM_ SG_ 64 IMT_DisCmd "Gear Display type command to cluster . this signal is for IMT system only.";
CM_ SG_ 64 IMT_CltchPdlPos "Clutch Pedal Position. This signal is for IMT system only.";
CM_ SG_ 64 DCT_RegenInhbt "The regen inhibit request from TCU";
CM_ SG_ 64 DCT_EngIdleReq "Engine Idle Request";
CM_ SG_ 64 DCT_CltchState "DCT clutch status";
CM_ SG_ 64 DCT_FuelCutReq "TCU require ECU to perform ‘Fuel Cut’";
CM_ SG_ 64 DCT_TqIncReq "Request for Torque Increase";
CM_ SG_ 64 DCT_CrpTqReq "Pre-control torque for creeping";
CM_ SG_ 64 DCT_ShftTqReq "Pre-control torque for shifting";
CM_ SG_ 64 TCU_GearSlctDis "TCU_GearSelectDisplay";
CM_ SG_ 64 TCU_Typ "TCU_Type";
CM_ SG_ 64 TCU_TqRdctnVal "TCU_TorqueReductionValue";
CM_ SG_ 64 TCU_GearStepTyp "TCU_GearStepType";
CM_ SG_ 64 TCU_GearShftSta "TCU_GearShiftStatus";
CM_ SG_ 64 TCU_TqCnvrtrSta "TCU_TorqueConverterStatus";
CM_ SG_ 64 TCU_CurrGearSta "TCU_CurrentGearStatus";
CM_ SG_ 64 TCU_TrgtGearSta "TCU_TargetGearStatus";
CM_ SG_ 64 TCU_CluTrgtGearSta "TCU_ClusterTargetGear";
CM_ SG_ 64 TCH_EngTrgtGearSta "TCU_EngineTargetGear";
CM_ SG_ 64 TCU_EngTqLimVal "TCU_EngineTorqueLimitValue";
CM_ SG_ 64 TCU_CluTrgtGearConfg "Signal source Configuration of  Target gear for CLU";
CM_ SG_ 64 TCU_VehSpdKphVal "TCU_VehicleSpeedKphValue";
BA_DEF_ BO_  "CANFD_BRS" ENUM  "0","1";
BA_DEF_ BO_  "GenMsgEVName" STRING ;
BA_DEF_ BU_  "NmAsrNodeIdentifier" HEX 0 255;
BA_DEF_ BU_  "NmAsrCanMsgReducedTime" INT 0 1000;
BA_DEF_  "NmAsrWaitBusSleepTime" INT 0 100000;
BA_DEF_  "NmAsrTimeoutTime" INT 0 100000;
BA_DEF_  "NmAsrRepeatMessageTime" INT 0 100000;
BA_DEF_  "NmAsrMessageCount" INT 0 255;
BA_DEF_  "NmAsrCanMsgCycleTime" INT 0 100;
BA_DEF_  "NmAsrBaseAddress" HEX 0 536870911;
BA_DEF_ BO_  "NmAsrMessage" ENUM  "No","Yes";
BA_DEF_ BO_  "DiagState" ENUM  "No","Yes";
BA_DEF_ BO_  "DiagResponse" ENUM  "No","Yes";
BA_DEF_ BO_  "DiagRequest" ENUM  "No","Yes";
BA_DEF_ BO_  "TpMessage" ENUM  "No","Yes";
BA_DEF_ BO_  "UsrMsgIDSforwardDeviation" INT 0 100;
BA_DEF_ BO_  "UsrMsgIDSbackwardDeviation" INT 50 1000;
BA_DEF_  "BusType" STRING ;
BA_DEF_  "DBName" STRING ;
BA_DEF_  "Baudrate" INT 50000 1000000;
BA_DEF_  "BRS" INT 0 1;
BA_DEF_  "GenEnvVarEndingDsp" STRING ;
BA_DEF_  "GenEnvVarEndingSnd" STRING ;
BA_DEF_  "GenEnvVarPrefix" STRING ;
BA_DEF_  "GenNWMApBusSleep" STRING ;
BA_DEF_  "GenNWMApCanNormal" STRING ;
BA_DEF_  "GenNWMApCanOff" STRING ;
BA_DEF_  "GenNWMApCanOn" STRING ;
BA_DEF_  "GenNWMApCanSleep" STRING ;
BA_DEF_  "GenNWMApCanWakeUp" STRING ;
BA_DEF_  "GenNWMGotoMode_Awake" STRING ;
BA_DEF_  "GenNWMGotoMode_BusSleep" STRING ;
BA_DEF_  "GenNWMSleepTime" INT 1375 1650;
BA_DEF_  "GenNWMTalkNM" STRING ;
BA_DEF_  "Manufacturer" STRING ;
BA_DEF_  "NmBaseAddress" HEX 0 2047;
BA_DEF_  "NmMessageCount" INT 0 128;
BA_DEF_  "NmType" STRING ;
BA_DEF_  "SamplePointMax" INT 50 85;
BA_DEF_  "SamplePointMin" INT 55 85;
BA_DEF_  "SyncJumpWidthMax" INT 1 8;
BA_DEF_  "SyncJumpWidthMin" INT 1 4;
BA_DEF_  "VersionDay" INT 1 31;
BA_DEF_  "VersionMonth" INT 1 12;
BA_DEF_  "VersionNumber" INT 0 999999;
BA_DEF_  "VersionNumberInternal" INT 0 9999;
BA_DEF_  "VersionWeek" INT 1 53;
BA_DEF_  "VersionYear" INT 0 9999;
BA_DEF_ BU_  "NmStationAddress" HEX 0 127;
BA_DEF_ BU_  "NmNode" ENUM  "No","Yes";
BA_DEF_ BU_  "GenNodSleepTime" INT 1375 1650;
BA_DEF_ BU_  "ILUsed" ENUM  "No","Yes";
BA_DEF_ BU_  "NmCAN" INT 1 2;
BA_DEF_ BU_  "NodeLayerModules" STRING ;
BA_DEF_ BU_  "NWM_Knoten" ENUM  "No","Yes";
BA_DEF_ BO_  "GenMsgCycleTime" INT 0 2000;
BA_DEF_ BO_  "GenMsgStartDelayTime" INT 0 2000;
BA_DEF_ BO_  "GenMsgSendType" ENUM  "Cyclic","NoMsgSendType";
BA_DEF_ BO_  "GenMsgCycleTimeFast" INT 0 500;
BA_DEF_ BO_  "GenMsgDelayTime" INT 0 20;
BA_DEF_ BO_  "GenMsgILSupport" ENUM  "No","Yes";
BA_DEF_ BO_  "GenMsgNrOfRepetition" INT 0 3;
BA_DEF_ BO_  "VFrameFormat" ENUM  "StandardCAN","ExtendedCAN","reserved","reserved","reserved","reserved","reserved","reserved","reserved","reserved","reserved","reserved","reserved","reserved","StandardCAN_FD","ExtendedCAN_FD";
BA_DEF_ SG_  "UserSigValidity" ENUM  "B+","ACC","IG","IG1","IG2","IG3","IG1 or IG2","IG1 or IG3","Undef";
BA_DEF_ SG_  "TimeoutValue" STRING ;
BA_DEF_ SG_  "UsrSigPurpose" ENUM  "Undef","FN","DIAG","DIAG(Req)","DIAG(Res)","DIAG(Func)","DEV","CCP","NM","TP";
BA_DEF_ SG_  "GenSigStartValue" INT 0 1215752192;
BA_DEF_ SG_  "NetworkRequest" ENUM  "Yes","No";
BA_DEF_ SG_  "NetworkRequestHoldingTime" INT 0 65535;
BA_DEF_ SG_  "Description" STRING ;
BA_DEF_ SG_  "Version" STRING ;
BA_DEF_ SG_  "GenSigEnvVarType" ENUM  "Int","Float","Undef";
BA_DEF_ SG_  "GenSigSendType" ENUM  "Cyclic","OnWrite","OnWriteWithRepetition","OnChange","OnChangeWithRepetition","IfActive","IfActiveWithRepetition","NoSigSendType","OnChangeAndIfActive","OnChangeAndIfActiveWithRepetition";
BA_DEF_ SG_  "GwSigLatencyTime" INT 0 65536;
BA_DEF_ SG_  "GwSigMissingSourceType" ENUM  "Undef","OldValue","DefaultValue","InitialValue";
BA_DEF_ SG_  "NWM-WakeupAllowed" ENUM  "<n.a.>";
BA_DEF_ SG_  "RoutingFactor" INT 1 1215752192;
BA_DEF_  "Datarate" INT 1000000 8000000;
BA_DEF_ SG_  "SystemSignalLongSymbol" STRING ;
BA_DEF_REL_ BU_SG_REL_  "GenSigTimeoutTime" INT 0 7000;
BA_DEF_DEF_  "CANFD_BRS" "1";
BA_DEF_DEF_  "GenMsgEVName" "@Signame";
BA_DEF_DEF_  "NmAsrNodeIdentifier" 0;
BA_DEF_DEF_  "NmAsrCanMsgReducedTime" 1000;
BA_DEF_DEF_  "NmAsrWaitBusSleepTime" 1500;
BA_DEF_DEF_  "NmAsrTimeoutTime" 1000;
BA_DEF_DEF_  "NmAsrRepeatMessageTime" 1200;
BA_DEF_DEF_  "NmAsrMessageCount" 255;
BA_DEF_DEF_  "NmAsrCanMsgCycleTime" 100;
BA_DEF_DEF_  "NmAsrBaseAddress" 402391040;
BA_DEF_DEF_  "NmAsrMessage" "No";
BA_DEF_DEF_  "DiagState" "No";
BA_DEF_DEF_  "DiagResponse" "No";
BA_DEF_DEF_  "DiagRequest" "No";
BA_DEF_DEF_  "TpMessage" "No";
BA_DEF_DEF_  "UsrMsgIDSforwardDeviation" 10;
BA_DEF_DEF_  "UsrMsgIDSbackwardDeviation" 100;
BA_DEF_DEF_  "BusType" "CAN FD";
BA_DEF_DEF_  "DBName" "";
BA_DEF_DEF_  "Baudrate" 500000;
BA_DEF_DEF_  "BRS" 1;
BA_DEF_DEF_  "GenEnvVarEndingDsp" "Dsp_";
BA_DEF_DEF_  "GenEnvVarEndingSnd" "_";
BA_DEF_DEF_  "GenEnvVarPrefix" "Env";
BA_DEF_DEF_  "GenNWMApBusSleep" "AppNmCanBusSleep()";
BA_DEF_DEF_  "GenNWMApCanNormal" "AppNmCanNormal()";
BA_DEF_DEF_  "GenNWMApCanOff" "ApplCanOffline()";
BA_DEF_DEF_  "GenNWMApCanOn" "ApplCanOnline()";
BA_DEF_DEF_  "GenNWMApCanSleep" "ApplNmCanSleep()";
BA_DEF_DEF_  "GenNWMApCanWakeUp" "ApplCanWakeUp()";
BA_DEF_DEF_  "GenNWMGotoMode_Awake" "GotoMode_Awake()";
BA_DEF_DEF_  "GenNWMGotoMode_BusSleep" "GotoMode_BusSleep()";
BA_DEF_DEF_  "GenNWMSleepTime" 1500;
BA_DEF_DEF_  "GenNWMTalkNM" "TalkNM()";
BA_DEF_DEF_  "Manufacturer" "HMC";
BA_DEF_DEF_  "NmBaseAddress" 1280;
BA_DEF_DEF_  "NmMessageCount" 128;
BA_DEF_DEF_  "NmType" "AsrNm";
BA_DEF_DEF_  "SamplePointMax" 80;
BA_DEF_DEF_  "SamplePointMin" 80;
BA_DEF_DEF_  "SyncJumpWidthMax" 3;
BA_DEF_DEF_  "SyncJumpWidthMin" 2;
BA_DEF_DEF_  "VersionDay" 1;
BA_DEF_DEF_  "VersionMonth" 1;
BA_DEF_DEF_  "VersionNumber" 0;
BA_DEF_DEF_  "VersionNumberInternal" 0;
BA_DEF_DEF_  "VersionWeek" 1;
BA_DEF_DEF_  "VersionYear" 0;
BA_DEF_DEF_  "NmStationAddress" 0;
BA_DEF_DEF_  "NmNode" "No";
BA_DEF_DEF_  "GenNodSleepTime" 1500;
BA_DEF_DEF_  "ILUsed" "Yes";
BA_DEF_DEF_  "NmCAN" 1;
BA_DEF_DEF_  "NodeLayerModules" "AsrNM33.DLL,CANoeILNLVector.DLL";
BA_DEF_DEF_  "NWM_Knoten" "Yes";
BA_DEF_DEF_  "GenMsgCycleTime" 200;
BA_DEF_DEF_  "GenMsgStartDelayTime" 0;
BA_DEF_DEF_  "GenMsgSendType" "NoMsgSendType";
BA_DEF_DEF_  "GenMsgCycleTimeFast" 40;
BA_DEF_DEF_  "GenMsgDelayTime" 20;
BA_DEF_DEF_  "GenMsgILSupport" "Yes";
BA_DEF_DEF_  "GenMsgNrOfRepetition" 3;
BA_DEF_DEF_  "VFrameFormat" "StandardCAN";
BA_DEF_DEF_  "UserSigValidity" "IG";
BA_DEF_DEF_  "TimeoutValue" "";
BA_DEF_DEF_  "UsrSigPurpose" "FN";
BA_DEF_DEF_  "GenSigStartValue" 0;
BA_DEF_DEF_  "NetworkRequest" "No";
BA_DEF_DEF_  "NetworkRequestHoldingTime" 0;
BA_DEF_DEF_  "Description" "";
BA_DEF_DEF_  "Version" "";
BA_DEF_DEF_  "GenSigEnvVarType" "Undef";
BA_DEF_DEF_  "GenSigSendType" "NoSigSendType";
BA_DEF_DEF_  "GwSigLatencyTime" 40;
BA_DEF_DEF_  "GwSigMissingSourceType" "Undef";
BA_DEF_DEF_  "NWM-WakeupAllowed" "<n.a.>";
BA_DEF_DEF_  "RoutingFactor" 1;
BA_DEF_DEF_  "Datarate" 1000000;
BA_DEF_DEF_REL_ "GenSigTimeoutTime" 500;
BA_DEF_DEF_  "SystemSignalLongSymbol" "";
BA_ "VersionYear" 1;
BA_ "VersionNumber" 240201;
BA_ "DBName" "FD_B2";
BA_ "NmStationAddress" BU_ ARS_FD 138;
BA_ "NmNode" BU_ ARS_FD 1;
BA_ "NmAsrNodeIdentifier" BU_ ARS_FD 138;
BA_ "NmStationAddress" BU_ WPC_FD 158;
BA_ "NmNode" BU_ WPC_FD 1;
BA_ "NmAsrNodeIdentifier" BU_ WPC_FD 158;
BA_ "NmStationAddress" BU_ WPC2_FD 149;
BA_ "NmNode" BU_ WPC2_FD 1;
BA_ "NmAsrNodeIdentifier" BU_ WPC2_FD 149;
BA_ "NmStationAddress" BU_ SCM_FD 135;
BA_ "NmNode" BU_ SCM_FD 1;
BA_ "NmAsrNodeIdentifier" BU_ SCM_FD 135;
BA_ "NmStationAddress" BU_ SHVU_FRNT_FD 170;
BA_ "NmNode" BU_ SHVU_FRNT_FD 1;
BA_ "NmAsrNodeIdentifier" BU_ SHVU_FRNT_FD 170;
BA_ "NmStationAddress" BU_ GW_SAU_DRV_FD 217;
BA_ "NmNode" BU_ GW_SAU_DRV_FD 1;
BA_ "NmAsrNodeIdentifier" BU_ GW_SAU_DRV_FD 217;
BA_ "NmStationAddress" BU_ GW_PSU_AST_FD 177;
BA_ "NmNode" BU_ GW_PSU_AST_FD 1;
BA_ "NmAsrNodeIdentifier" BU_ GW_PSU_AST_FD 177;
BA_ "NmStationAddress" BU_ GW_PSU_3RD_FD 173;
BA_ "NmNode" BU_ GW_PSU_3RD_FD 1;
BA_ "NmAsrNodeIdentifier" BU_ GW_PSU_3RD_FD 173;
BA_ "NmStationAddress" BU_ RCS_FD 198;
BA_ "NmNode" BU_ RCS_FD 1;
BA_ "NmAsrNodeIdentifier" BU_ RCS_FD 198;
BA_ "NmStationAddress" BU_ GW_PSU_RL_FD 156;
BA_ "NmNode" BU_ GW_PSU_RL_FD 1;
BA_ "NmAsrNodeIdentifier" BU_ GW_PSU_RL_FD 156;
BA_ "NmStationAddress" BU_ RCM_FD 189;
BA_ "NmNode" BU_ RCM_FD 1;
BA_ "NmAsrNodeIdentifier" BU_ RCM_FD 189;
BA_ "NmStationAddress" BU_ SHVU_3RD_FD 82;
BA_ "NmNode" BU_ SHVU_3RD_FD 1;
BA_ "NmAsrNodeIdentifier" BU_ SHVU_3RD_FD 82;
BA_ "NmStationAddress" BU_ SHVU_RR_FD 181;
BA_ "NmNode" BU_ SHVU_RR_FD 1;
BA_ "NmAsrNodeIdentifier" BU_ SHVU_RR_FD 181;
BA_ "NmStationAddress" BU_ PSB_FD 193;
BA_ "NmNode" BU_ PSB_FD 1;
BA_ "NmAsrNodeIdentifier" BU_ PSB_FD 193;
BA_ "NmStationAddress" BU_ ATS_FD 208;
BA_ "NmNode" BU_ ATS_FD 1;
BA_ "NmAsrNodeIdentifier" BU_ ATS_FD 208;
BA_ "NmStationAddress" BU_ GW_PSU_RR_FD 157;
BA_ "NmNode" BU_ GW_PSU_RR_FD 1;
BA_ "NmAsrNodeIdentifier" BU_ GW_PSU_RR_FD 157;
BA_ "NmStationAddress" BU_ SHVU_RL_FD 180;
BA_ "NmNode" BU_ SHVU_RL_FD 1;
BA_ "NmAsrNodeIdentifier" BU_ SHVU_RL_FD 180;
BA_ "NmStationAddress" BU_ RWPC_FD 159;
BA_ "NmNode" BU_ RWPC_FD 1;
BA_ "NmAsrNodeIdentifier" BU_ RWPC_FD 159;
BA_ "NmStationAddress" BU_ CGW_CCU 112;
BA_ "NmNode" BU_ CGW_CCU 1;
BA_ "NmAsrNodeIdentifier" BU_ CGW_CCU 112;
BA_ "NmStationAddress" BU_ OHCL_FD 212;
BA_ "NmNode" BU_ OHCL_FD 1;
BA_ "NmAsrNodeIdentifier" BU_ OHCL_FD 212;
BA_ "NmStationAddress" BU_ SHVU_REAR_FD 171;
BA_ "NmNode" BU_ SHVU_REAR_FD 1;
BA_ "NmAsrNodeIdentifier" BU_ SHVU_REAR_FD 171;
BA_ "NmStationAddress" BU_ BLTN_CAM_FD 200;
BA_ "NmNode" BU_ BLTN_CAM_FD 1;
BA_ "NmAsrNodeIdentifier" BU_ BLTN_CAM_FD 200;
BA_ "NmStationAddress" BU_ SGU_FD 190;
BA_ "NmNode" BU_ SGU_FD 1;
BA_ "NmAsrNodeIdentifier" BU_ SGU_FD 190;
BA_ "NmStationAddress" BU_ GW_PSU_DRV_FD 184;
BA_ "NmNode" BU_ GW_PSU_DRV_FD 1;
BA_ "NmAsrNodeIdentifier" BU_ GW_PSU_DRV_FD 184;
BA_ "NmStationAddress" BU_ FCS_FD 161;
BA_ "NmNode" BU_ FCS_FD 1;
BA_ "NmAsrNodeIdentifier" BU_ FCS_FD 161;
BA_ "DiagRequest" BO_ 1 1;
BA_ "TpMessage" BO_ 1 1;
BA_ "GenMsgCycleTime" BO_ 1 0;
BA_ "GenMsgCycleTimeFast" BO_ 1 0;
BA_ "GenMsgILSupport" BO_ 1 0;
BA_ "VFrameFormat" BO_ 1 14;
BA_ "DiagRequest" BO_ 1941 1;
BA_ "TpMessage" BO_ 1941 1;
BA_ "GenMsgCycleTime" BO_ 1941 0;
BA_ "GenMsgCycleTimeFast" BO_ 1941 0;
BA_ "GenMsgILSupport" BO_ 1941 0;
BA_ "GenMsgNrOfRepetition" BO_ 1941 0;
BA_ "VFrameFormat" BO_ 1941 14;
BA_ "DiagState" BO_ 2015 1;
BA_ "TpMessage" BO_ 2015 1;
BA_ "GenMsgCycleTime" BO_ 2015 0;
BA_ "GenMsgCycleTimeFast" BO_ 2015 0;
BA_ "GenMsgILSupport" BO_ 2015 0;
BA_ "GenMsgNrOfRepetition" BO_ 2015 0;
BA_ "VFrameFormat" BO_ 2015 14;
BA_ "DiagResponse" BO_ 1949 1;
BA_ "TpMessage" BO_ 1949 1;
BA_ "GenMsgCycleTime" BO_ 1949 0;
BA_ "GenMsgCycleTimeFast" BO_ 1949 0;
BA_ "GenMsgILSupport" BO_ 1949 0;
BA_ "GenMsgNrOfRepetition" BO_ 1949 0;
BA_ "VFrameFormat" BO_ 1949 14;
BA_ "GenMsgSendType" BO_ 956 0;
BA_ "VFrameFormat" BO_ 956 14;
BA_ "GenMsgCycleTime" BO_ 274 0;
BA_ "VFrameFormat" BO_ 274 14;
BA_ "GenMsgSendType" BO_ 686 0;
BA_ "GenMsgStartDelayTime" BO_ 686 30;
BA_ "VFrameFormat" BO_ 686 14;
BA_ "GenMsgSendType" BO_ 957 0;
BA_ "GenMsgStartDelayTime" BO_ 957 10;
BA_ "VFrameFormat" BO_ 957 14;
BA_ "GenMsgSendType" BO_ 69 0;
BA_ "GenMsgCycleTime" BO_ 69 50;
BA_ "GenMsgCycleTimeFast" BO_ 69 0;
BA_ "GenMsgNrOfRepetition" BO_ 69 0;
BA_ "VFrameFormat" BO_ 69 14;
BA_ "GenMsgSendType" BO_ 685 0;
BA_ "GenMsgStartDelayTime" BO_ 685 30;
BA_ "VFrameFormat" BO_ 685 14;
BA_ "GenMsgCycleTime" BO_ 138 0;
BA_ "VFrameFormat" BO_ 138 14;
BA_ "GenMsgSendType" BO_ 64 0;
BA_ "GenMsgCycleTime" BO_ 64 50;
BA_ "GenMsgCycleTimeFast" BO_ 64 0;
BA_ "GenMsgNrOfRepetition" BO_ 64 0;
BA_ "VFrameFormat" BO_ 64 14;
BA_ "UserSigValidity" SG_ 3221225472 dummy_GST_BLTN_CAM_Byte 0;
BA_ "UsrSigPurpose" SG_ 3221225472 dummy_GST_BLTN_CAM_Byte 3;
BA_ "UserSigValidity" SG_ 2015 GST_ALL_Byte2 0;
BA_ "UsrSigPurpose" SG_ 2015 GST_ALL_Byte2 5;
BA_ "NetworkRequest" SG_ 2015 GST_ALL_Byte2 0;
BA_ "NetworkRequestHoldingTime" SG_ 2015 GST_ALL_Byte2 5000;
BA_ "Description" SG_ 2015 GST_ALL_Byte2 "TP Index : 0";
BA_ "Version" SG_ 2015 GST_ALL_Byte2 "22.06.01";
BA_ "UserSigValidity" SG_ 2015 GST_ALL_Byte7 0;
BA_ "UsrSigPurpose" SG_ 2015 GST_ALL_Byte7 5;
BA_ "NetworkRequest" SG_ 2015 GST_ALL_Byte7 0;
BA_ "NetworkRequestHoldingTime" SG_ 2015 GST_ALL_Byte7 5000;
BA_ "Description" SG_ 2015 GST_ALL_Byte7 "TP Index : 0";
BA_ "Version" SG_ 2015 GST_ALL_Byte7 "22.06.01";
BA_ "UserSigValidity" SG_ 2015 GST_ALL_Byte6 0;
BA_ "UsrSigPurpose" SG_ 2015 GST_ALL_Byte6 5;
BA_ "NetworkRequest" SG_ 2015 GST_ALL_Byte6 0;
BA_ "NetworkRequestHoldingTime" SG_ 2015 GST_ALL_Byte6 5000;
BA_ "Description" SG_ 2015 GST_ALL_Byte6 "TP Index : 0";
BA_ "Version" SG_ 2015 GST_ALL_Byte6 "22.06.01";
BA_ "UserSigValidity" SG_ 2015 GST_ALL_Byte5 0;
BA_ "UsrSigPurpose" SG_ 2015 GST_ALL_Byte5 5;
BA_ "NetworkRequest" SG_ 2015 GST_ALL_Byte5 0;
BA_ "NetworkRequestHoldingTime" SG_ 2015 GST_ALL_Byte5 5000;
BA_ "Description" SG_ 2015 GST_ALL_Byte5 "TP Index : 0";
BA_ "Version" SG_ 2015 GST_ALL_Byte5 "22.06.01";
BA_ "UserSigValidity" SG_ 2015 GST_ALL_Byte4 0;
BA_ "UsrSigPurpose" SG_ 2015 GST_ALL_Byte4 5;
BA_ "NetworkRequest" SG_ 2015 GST_ALL_Byte4 0;
BA_ "NetworkRequestHoldingTime" SG_ 2015 GST_ALL_Byte4 5000;
BA_ "Description" SG_ 2015 GST_ALL_Byte4 "TP Index : 0";
BA_ "Version" SG_ 2015 GST_ALL_Byte4 "22.06.01";
BA_ "UserSigValidity" SG_ 2015 GST_ALL_Byte3 0;
BA_ "UsrSigPurpose" SG_ 2015 GST_ALL_Byte3 5;
BA_ "NetworkRequest" SG_ 2015 GST_ALL_Byte3 0;
BA_ "NetworkRequestHoldingTime" SG_ 2015 GST_ALL_Byte3 5000;
BA_ "Description" SG_ 2015 GST_ALL_Byte3 "TP Index : 0";
BA_ "Version" SG_ 2015 GST_ALL_Byte3 "22.06.01";
BA_ "UserSigValidity" SG_ 2015 GST_ALL_Byte1 0;
BA_ "UsrSigPurpose" SG_ 2015 GST_ALL_Byte1 5;
BA_ "NetworkRequest" SG_ 2015 GST_ALL_Byte1 0;
BA_ "NetworkRequestHoldingTime" SG_ 2015 GST_ALL_Byte1 5000;
BA_ "Description" SG_ 2015 GST_ALL_Byte1 "TP Index : 0";
BA_ "Version" SG_ 2015 GST_ALL_Byte1 "22.06.01";
BA_ "UserSigValidity" SG_ 2015 GST_ALL_Byte0 0;
BA_ "UsrSigPurpose" SG_ 2015 GST_ALL_Byte0 5;
BA_ "NetworkRequest" SG_ 2015 GST_ALL_Byte0 0;
BA_ "NetworkRequestHoldingTime" SG_ 2015 GST_ALL_Byte0 5000;
BA_ "Description" SG_ 2015 GST_ALL_Byte0 "TP Index : 0";
BA_ "Version" SG_ 2015 GST_ALL_Byte0 "22.06.01";
BA_ "UserSigValidity" SG_ 1949 dummy_BLTN_CAM_GST_Byte 0;
BA_ "UsrSigPurpose" SG_ 1949 dummy_BLTN_CAM_GST_Byte 4;
BA_ "Description" SG_ 956 BLTN_CAM_FD_Crc2Val "The data area for CRC calculation is based on the data length (DLC) of the message DB.

The CRC shall be calculated over the entire data block (excluding the CRC bytes) including the user data, alive counter and Data ID



- CRC Polynomial (0x1021) , Ini";
BA_ "GenSigSendType" SG_ 956 BLTN_CAM_FD_Crc2Val 4;
BA_ "GenSigStartValue" SG_ 956 BLTN_CAM_FD_Crc2Val 65535;
BA_ "UserSigValidity" SG_ 956 BLTN_CAM_FD_Crc2Val 3;
BA_ "Version" SG_ 956 BLTN_CAM_FD_Crc2Val "22.11.04";
BA_ "Description" SG_ 956 BLTN_CAM_Set_EV_BfrTime "Driving Event Time Setting - Before, Resolution : sec";
BA_ "GenSigSendType" SG_ 956 BLTN_CAM_Set_EV_BfrTime 4;
BA_ "UserSigValidity" SG_ 956 BLTN_CAM_Set_EV_BfrTime 0;
BA_ "Version" SG_ 956 BLTN_CAM_Set_EV_BfrTime "21.05.02";
BA_ "Description" SG_ 956 BLTN_CAM_Set_EV_AftTime "Driving Event Time Setting - After, Resolution : sec";
BA_ "GenSigSendType" SG_ 956 BLTN_CAM_Set_EV_AftTime 4;
BA_ "UserSigValidity" SG_ 956 BLTN_CAM_Set_EV_AftTime 0;
BA_ "Version" SG_ 956 BLTN_CAM_Set_EV_AftTime "21.05.02";
BA_ "Description" SG_ 956 BLTN_CAM_Set_Drv_TML_Int "Record Set of Time-lapse Interval, Resolution : sec";
BA_ "GenSigSendType" SG_ 956 BLTN_CAM_Set_Drv_TML_Int 4;
BA_ "UserSigValidity" SG_ 956 BLTN_CAM_Set_Drv_TML_Int 0;
BA_ "Version" SG_ 956 BLTN_CAM_Set_Drv_TML_Int "21.05.02";
BA_ "Description" SG_ 956 BLTN_CAM_SenSet_DEV "Set of Event  Detection Sensitivity of Driving Mode";
BA_ "GenSigSendType" SG_ 956 BLTN_CAM_SenSet_DEV 4;
BA_ "UserSigValidity" SG_ 956 BLTN_CAM_SenSet_DEV 0;
BA_ "Version" SG_ 956 BLTN_CAM_SenSet_DEV "21.05.02";
BA_ "Description" SG_ 956 BLTN_CAM_SenSet_PEV "Set of Event  Detection Sensitivity of Parking Mode";
BA_ "GenSigSendType" SG_ 956 BLTN_CAM_SenSet_PEV 4;
BA_ "UserSigValidity" SG_ 956 BLTN_CAM_SenSet_PEV 0;
BA_ "Version" SG_ 956 BLTN_CAM_SenSet_PEV "21.05.02";
BA_ "Description" SG_ 956 BLTN_CAM_Set_FR_Ver_Pos "Front Camera Vertical position setting value.";
BA_ "GenSigSendType" SG_ 956 BLTN_CAM_Set_FR_Ver_Pos 4;
BA_ "UserSigValidity" SG_ 956 BLTN_CAM_Set_FR_Ver_Pos 0;
BA_ "Version" SG_ 956 BLTN_CAM_Set_FR_Ver_Pos "22.07.06";
BA_ "Description" SG_ 956 BLTN_CAM_Set_RR_Ver_Pos "Rear Camera Vertical position setting value.";
BA_ "GenSigSendType" SG_ 956 BLTN_CAM_Set_RR_Ver_Pos 4;
BA_ "UserSigValidity" SG_ 956 BLTN_CAM_Set_RR_Ver_Pos 0;
BA_ "Version" SG_ 956 BLTN_CAM_Set_RR_Ver_Pos "22.07.06";
BA_ "Description" SG_ 956 BLTN_CAM_Set_PEV_AppNoti "Parked Event notification to Connectivity Phone App. On/Off";
BA_ "GenSigSendType" SG_ 956 BLTN_CAM_Set_PEV_AppNoti 4;
BA_ "UserSigValidity" SG_ 956 BLTN_CAM_Set_PEV_AppNoti 0;
BA_ "Version" SG_ 956 BLTN_CAM_Set_PEV_AppNoti "21.05.02";
BA_ "Description" SG_ 956 BLTN_CAM_Set_WiFi_AutoOn "Wifi On/Off User setting";
BA_ "GenSigSendType" SG_ 956 BLTN_CAM_Set_WiFi_AutoOn 4;
BA_ "UserSigValidity" SG_ 956 BLTN_CAM_Set_WiFi_AutoOn 0;
BA_ "Version" SG_ 956 BLTN_CAM_Set_WiFi_AutoOn "21.05.02";
BA_ "Description" SG_ 956 BLTN_CAM_StrgPropSet "Propotion of built-in Cam SD card Propotion set of the Recording Categories";
BA_ "GenSigSendType" SG_ 956 BLTN_CAM_StrgPropSet 4;
BA_ "UserSigValidity" SG_ 956 BLTN_CAM_StrgPropSet 0;
BA_ "Version" SG_ 956 BLTN_CAM_StrgPropSet "21.05.02";
BA_ "Description" SG_ 956 BLTN_CAM_File_DEL_CPY_Op_State "Bulil in Cam Fily copy and delete operating state.";
BA_ "GenSigSendType" SG_ 956 BLTN_CAM_File_DEL_CPY_Op_State 4;
BA_ "UserSigValidity" SG_ 956 BLTN_CAM_File_DEL_CPY_Op_State 0;
BA_ "Version" SG_ 956 BLTN_CAM_File_DEL_CPY_Op_State "21.05.02";
BA_ "Description" SG_ 956 BLTN_CAM_File_DEL_CPY_NumTot "Number of Copied or Deleted files.";
BA_ "GenSigSendType" SG_ 956 BLTN_CAM_File_DEL_CPY_NumTot 4;
BA_ "UserSigValidity" SG_ 956 BLTN_CAM_File_DEL_CPY_NumTot 0;
BA_ "Version" SG_ 956 BLTN_CAM_File_DEL_CPY_NumTot "21.05.02";
BA_ "Description" SG_ 956 BLTN_CAM_FD_AlvCnt2Val "For the first transmission request for a data element the counter shall be initialized with 0 and shall be incremented by 1 for every subsequent send request. 

When the counter reaches the maximum value(0xFF), then it shall restart with 0 for the next s";
BA_ "GenSigSendType" SG_ 956 BLTN_CAM_FD_AlvCnt2Val 4;
BA_ "UserSigValidity" SG_ 956 BLTN_CAM_FD_AlvCnt2Val 3;
BA_ "Version" SG_ 956 BLTN_CAM_FD_AlvCnt2Val "22.11.04";
BA_ "Description" SG_ 956 BLTN_CAM_File_DEL_CPYed_Num "Total number of the copy or delete file.";
BA_ "GenSigSendType" SG_ 956 BLTN_CAM_File_DEL_CPYed_Num 4;
BA_ "UserSigValidity" SG_ 956 BLTN_CAM_File_DEL_CPYed_Num 0;
BA_ "Version" SG_ 956 BLTN_CAM_File_DEL_CPYed_Num "21.05.02";
BA_ "Description" SG_ 956 BLTN_CAM_Set_PMD "Parked Motion Detection Record Mode On/Off Set";
BA_ "GenSigSendType" SG_ 956 BLTN_CAM_Set_PMD 4;
BA_ "UserSigValidity" SG_ 956 BLTN_CAM_Set_PMD 0;
BA_ "Version" SG_ 956 BLTN_CAM_Set_PMD "24.01.05";
BA_ "Description" SG_ 956 BLTN_CAM_Set_PMDEV "Parked Motion Detection Event Record On/Off Set";
BA_ "GenSigSendType" SG_ 956 BLTN_CAM_Set_PMDEV 4;
BA_ "UserSigValidity" SG_ 956 BLTN_CAM_Set_PMDEV 0;
BA_ "Version" SG_ 956 BLTN_CAM_Set_PMDEV "24.01.05";
BA_ "Description" SG_ 956 BLTN_CAM_RanSet_PMDR "Set of Range level of Parked Motion Detection Record Mode";
BA_ "GenSigSendType" SG_ 956 BLTN_CAM_RanSet_PMDR 4;
BA_ "UserSigValidity" SG_ 956 BLTN_CAM_RanSet_PMDR 0;
BA_ "Version" SG_ 956 BLTN_CAM_RanSet_PMDR "24.01.05";
BA_ "Description" SG_ 956 BLTN_CAM_MaxRanSet_PMDR "Set Level Range of Parked Motion Detection Record Mode";
BA_ "GenSigSendType" SG_ 956 BLTN_CAM_MaxRanSet_PMDR 4;
BA_ "UserSigValidity" SG_ 956 BLTN_CAM_MaxRanSet_PMDR 0;
BA_ "Version" SG_ 956 BLTN_CAM_MaxRanSet_PMDR "24.01.05";
BA_ "Description" SG_ 956 BLTN_CAM_Set_PMDTime "Set the hours of Parked Motion Detection Mode";
BA_ "GenSigSendType" SG_ 956 BLTN_CAM_Set_PMDTime 4;
BA_ "GenSigStartValue" SG_ 956 BLTN_CAM_Set_PMDTime 1;
BA_ "UserSigValidity" SG_ 956 BLTN_CAM_Set_PMDTime 0;
BA_ "Version" SG_ 956 BLTN_CAM_Set_PMDTime "24.01.05";
BA_ "Description" SG_ 956 BLTN_CAM_RecSet_OWD "Record On/Off Set of On While Driving";
BA_ "GenSigSendType" SG_ 956 BLTN_CAM_RecSet_OWD 4;
BA_ "UserSigValidity" SG_ 956 BLTN_CAM_RecSet_OWD 0;
BA_ "Version" SG_ 956 BLTN_CAM_RecSet_OWD "21.05.02";
BA_ "Description" SG_ 956 BLTN_CAM_RecSet_DEV "Record On/Off Set of Driving Event";
BA_ "GenSigSendType" SG_ 956 BLTN_CAM_RecSet_DEV 4;
BA_ "UserSigValidity" SG_ 956 BLTN_CAM_RecSet_DEV 0;
BA_ "Version" SG_ 956 BLTN_CAM_RecSet_DEV "21.05.02";
BA_ "Description" SG_ 956 BLTN_CAM_RecSet_OWP "Record On/Off Set of On While Parked, 0x0(Default) : Parking recording function not supported";
BA_ "GenSigSendType" SG_ 956 BLTN_CAM_RecSet_OWP 4;
BA_ "UserSigValidity" SG_ 956 BLTN_CAM_RecSet_OWP 0;
BA_ "Version" SG_ 956 BLTN_CAM_RecSet_OWP "21.05.02";
BA_ "Description" SG_ 956 BLTN_CAM_RecSet_PEV "Record Set of Parked Event, 0x0(Default) : Parking recording function not supported";
BA_ "GenSigSendType" SG_ 956 BLTN_CAM_RecSet_PEV 4;
BA_ "UserSigValidity" SG_ 956 BLTN_CAM_RecSet_PEV 0;
BA_ "Version" SG_ 956 BLTN_CAM_RecSet_PEV "21.05.02";
BA_ "Description" SG_ 956 BLTN_CAM_AudRec_Set "Audio Record On/Off Set";
BA_ "GenSigSendType" SG_ 956 BLTN_CAM_AudRec_Set 4;
BA_ "UserSigValidity" SG_ 956 BLTN_CAM_AudRec_Set 0;
BA_ "Version" SG_ 956 BLTN_CAM_AudRec_Set "21.05.02";
BA_ "Description" SG_ 956 BLTN_CAM_Set_Tim_Stm "Record Set of Date and Time Stamp";
BA_ "GenSigSendType" SG_ 956 BLTN_CAM_Set_Tim_Stm 4;
BA_ "UserSigValidity" SG_ 956 BLTN_CAM_Set_Tim_Stm 0;
BA_ "Version" SG_ 956 BLTN_CAM_Set_Tim_Stm "21.05.02";
BA_ "Description" SG_ 956 BLTN_CAM_Set_Spd_Stm "Record Set of Speed Stamp";
BA_ "GenSigSendType" SG_ 956 BLTN_CAM_Set_Spd_Stm 4;
BA_ "UserSigValidity" SG_ 956 BLTN_CAM_Set_Spd_Stm 0;
BA_ "Version" SG_ 956 BLTN_CAM_Set_Spd_Stm "21.11.07";
BA_ "Description" SG_ 956 BLTN_CAM_Set_Locatn_Stm "Record Set of Location Stamp";
BA_ "GenSigSendType" SG_ 956 BLTN_CAM_Set_Locatn_Stm 4;
BA_ "UserSigValidity" SG_ 956 BLTN_CAM_Set_Locatn_Stm 0;
BA_ "Version" SG_ 956 BLTN_CAM_Set_Locatn_Stm "21.05.02";
BA_ "Description" SG_ 956 BLTN_CAM_Set_TrnSig_Stm "Record Set of Turn Signal Stamp";
BA_ "GenSigSendType" SG_ 956 BLTN_CAM_Set_TrnSig_Stm 4;
BA_ "UserSigValidity" SG_ 956 BLTN_CAM_Set_TrnSig_Stm 0;
BA_ "Version" SG_ 956 BLTN_CAM_Set_TrnSig_Stm "21.05.02";
BA_ "Description" SG_ 956 BLTN_CAM_Set_AclBrk_Stm "Record Set of Accelerator Brake Stamp";
BA_ "GenSigSendType" SG_ 956 BLTN_CAM_Set_AclBrk_Stm 4;
BA_ "UserSigValidity" SG_ 956 BLTN_CAM_Set_AclBrk_Stm 0;
BA_ "Version" SG_ 956 BLTN_CAM_Set_AclBrk_Stm "21.11.07";
BA_ "Description" SG_ 956 BLTN_CAM_Set_GearPos_Stm "Record Set of Gear Position Stamp";
BA_ "GenSigSendType" SG_ 956 BLTN_CAM_Set_GearPos_Stm 4;
BA_ "UserSigValidity" SG_ 956 BLTN_CAM_Set_GearPos_Stm 0;
BA_ "Version" SG_ 956 BLTN_CAM_Set_GearPos_Stm "21.05.02";
BA_ "Description" SG_ 956 BLTN_CAM_Set_EVSen_Stm "Record Set of Event Sensitivity Stamp";
BA_ "GenSigSendType" SG_ 956 BLTN_CAM_Set_EVSen_Stm 4;
BA_ "UserSigValidity" SG_ 956 BLTN_CAM_Set_EVSen_Stm 0;
BA_ "Version" SG_ 956 BLTN_CAM_Set_EVSen_Stm "21.05.02";
BA_ "Description" SG_ 956 BLTN_CAM_Set_StrAngl_Stm "Record Set of Steering Angle Stamp";
BA_ "GenSigSendType" SG_ 956 BLTN_CAM_Set_StrAngl_Stm 4;
BA_ "UserSigValidity" SG_ 956 BLTN_CAM_Set_StrAngl_Stm 0;
BA_ "Version" SG_ 956 BLTN_CAM_Set_StrAngl_Stm "21.07.05";
BA_ "Description" SG_ 956 BLTN_CAM_Set_EV_RecMaxTime "BLTN_CAM Set EV Parking Rec Max Time";
BA_ "GenSigSendType" SG_ 956 BLTN_CAM_Set_EV_RecMaxTime 4;
BA_ "UserSigValidity" SG_ 956 BLTN_CAM_Set_EV_RecMaxTime 0;
BA_ "Version" SG_ 956 BLTN_CAM_Set_EV_RecMaxTime "23.02.02";
BA_ "Description" SG_ 956 BLTN_CAM_Set_PrkTime "Parking Operation Setting Time, Resolution : hr";
BA_ "GenSigSendType" SG_ 956 BLTN_CAM_Set_PrkTime 4;
BA_ "UserSigValidity" SG_ 956 BLTN_CAM_Set_PrkTime 0;
BA_ "Version" SG_ 956 BLTN_CAM_Set_PrkTime "21.11.07";
BA_ "Description" SG_ 274 HU_USM_Crc2Val "The data area for CRC calculation is based on the data length (DLC) of the message DB.

The CRC shall be calculated over the entire data block (excluding the CRC bytes) including the user data, alive counter and Data ID



- CRC Polynomial (0x1021) , Ini";
BA_ "GenSigSendType" SG_ 274 HU_USM_Crc2Val 4;
BA_ "GenSigStartValue" SG_ 274 HU_USM_Crc2Val 65535;
BA_ "UserSigValidity" SG_ 274 HU_USM_Crc2Val 3;
BA_ "Version" SG_ 274 HU_USM_Crc2Val "22.10.20";
BA_ "GenSigSendType" SG_ 274 CF_AVN_CluRheostatLvl 4;
BA_ "GenSigStartValue" SG_ 274 CF_AVN_CluRheostatLvl 31;
BA_ "UserSigValidity" SG_ 274 CF_AVN_CluRheostatLvl 3;
BA_ "Version" SG_ 274 CF_AVN_CluRheostatLvl "18.06.04";
BA_ "GenSigSendType" SG_ 274 CF_AVN_EVReset 4;
BA_ "UserSigValidity" SG_ 274 CF_AVN_EVReset 7;
BA_ "Version" SG_ 274 CF_AVN_EVReset "18.09.04";
BA_ "GenSigSendType" SG_ 274 CF_AVN_UnitReset 4;
BA_ "UserSigValidity" SG_ 274 CF_AVN_UnitReset 3;
BA_ "Version" SG_ 274 CF_AVN_UnitReset "18.09.04";
BA_ "GenSigSendType" SG_ 274 CF_AVN_IcyRoadWarn 4;
BA_ "UserSigValidity" SG_ 274 CF_AVN_IcyRoadWarn 3;
BA_ "Version" SG_ 274 CF_AVN_IcyRoadWarn "18.04.02";
BA_ "GenSigSendType" SG_ 274 CF_AVN_CluServiceReminderReset 4;
BA_ "UserSigValidity" SG_ 274 CF_AVN_CluServiceReminderReset 3;
BA_ "Version" SG_ 274 CF_AVN_CluServiceReminderReset "18.04.02";
BA_ "GenSigSendType" SG_ 274 CF_AVN_CluUSMReset 4;
BA_ "UserSigValidity" SG_ 274 CF_AVN_CluUSMReset 3;
BA_ "Version" SG_ 274 CF_AVN_CluUSMReset "21.01.08";
BA_ "GenSigSendType" SG_ 274 C_HCIMSWeightNValueSet 4;
BA_ "UserSigValidity" SG_ 274 C_HCIMSWeightNValueSet 3;
BA_ "Version" SG_ 274 C_HCIMSWeightNValueSet "18.09.04";
BA_ "GenSigSendType" SG_ 274 C_HCIMSHeightNvalueSet 4;
BA_ "UserSigValidity" SG_ 274 C_HCIMSHeightNvalueSet 3;
BA_ "Version" SG_ 274 C_HCIMSHeightNvalueSet "18.09.04";
BA_ "GenSigSendType" SG_ 274 CF_AVN_HCIMSButtonCommand 4;
BA_ "UserSigValidity" SG_ 274 CF_AVN_HCIMSButtonCommand 3;
BA_ "Version" SG_ 274 CF_AVN_HCIMSButtonCommand "18.09.04";
BA_ "GenSigSendType" SG_ 274 C_HCIMSSitHeightNValueSet 4;
BA_ "UserSigValidity" SG_ 274 C_HCIMSSitHeightNValueSet 3;
BA_ "Version" SG_ 274 C_HCIMSSitHeightNValueSet "18.09.04";
BA_ "GenSigSendType" SG_ 274 CF_AVN_BodySpprtSet 4;
BA_ "GenSigStartValue" SG_ 274 CF_AVN_BodySpprtSet 3;
BA_ "UserSigValidity" SG_ 274 CF_AVN_BodySpprtSet 3;
BA_ "Version" SG_ 274 CF_AVN_BodySpprtSet "18.11.01";
BA_ "Description" SG_ 274 HU_USM_AlvCnt2Val "For the first transmission request for a data element the counter shall be initialized with 0 and shall be incremented by 1 for every subsequent send request. 

When the counter reaches the maximum value(0xFF), then it shall restart with 0 for the next s";
BA_ "GenSigSendType" SG_ 274 HU_USM_AlvCnt2Val 4;
BA_ "UserSigValidity" SG_ 274 HU_USM_AlvCnt2Val 3;
BA_ "Version" SG_ 274 HU_USM_AlvCnt2Val "22.10.20";
BA_ "GenSigSendType" SG_ 274 CF_AVN_AirSptTimeNValueSet 4;
BA_ "GenSigStartValue" SG_ 274 CF_AVN_AirSptTimeNValueSet 7;
BA_ "UserSigValidity" SG_ 274 CF_AVN_AirSptTimeNValueSet 3;
BA_ "Version" SG_ 274 CF_AVN_AirSptTimeNValueSet "18.09.04";
BA_ "GenSigSendType" SG_ 274 CF_AVN_AirSptStrNValue 4;
BA_ "GenSigStartValue" SG_ 274 CF_AVN_AirSptStrNValue 3;
BA_ "UserSigValidity" SG_ 274 CF_AVN_AirSptStrNValue 3;
BA_ "Version" SG_ 274 CF_AVN_AirSptStrNValue "18.09.04";
BA_ "GenSigSendType" SG_ 274 CF_AVN_SeatDrvModNValueSet 4;
BA_ "GenSigStartValue" SG_ 274 CF_AVN_SeatDrvModNValueSet 3;
BA_ "UserSigValidity" SG_ 274 CF_AVN_SeatDrvModNValueSet 3;
BA_ "Version" SG_ 274 CF_AVN_SeatDrvModNValueSet "18.09.04";
BA_ "Description" SG_ 274 C_SmrtSldngDrNValueSet "USM request for Smart Sliding Door";
BA_ "GenSigSendType" SG_ 274 C_SmrtSldngDrNValueSet 4;
BA_ "UserSigValidity" SG_ 274 C_SmrtSldngDrNValueSet 3;
BA_ "Version" SG_ 274 C_SmrtSldngDrNValueSet "19.01.10";
BA_ "Description" SG_ 274 CF_AVN_TurboPressureUnit "USM Request for Turbo Boost Pressure Unit";
BA_ "GenSigSendType" SG_ 274 CF_AVN_TurboPressureUnit 4;
BA_ "UserSigValidity" SG_ 274 CF_AVN_TurboPressureUnit 3;
BA_ "Version" SG_ 274 CF_AVN_TurboPressureUnit "19.06.02";
BA_ "Description" SG_ 274 CF_AVN_CluTorqueUnit "USM Request for Torque Unit Setting";
BA_ "GenSigSendType" SG_ 274 CF_AVN_CluTorqueUnit 4;
BA_ "UserSigValidity" SG_ 274 CF_AVN_CluTorqueUnit 3;
BA_ "Version" SG_ 274 CF_AVN_CluTorqueUnit "19.06.02";
BA_ "GenSigSendType" SG_ 274 CF_AVN_MoodLpRedNValueSet 4;
BA_ "GenSigStartValue" SG_ 274 CF_AVN_MoodLpRedNValueSet 512;
BA_ "UserSigValidity" SG_ 274 CF_AVN_MoodLpRedNValueSet 3;
BA_ "NetworkRequest" SG_ 274 CF_AVN_MoodLpRedNValueSet 0;
BA_ "NetworkRequestHoldingTime" SG_ 274 CF_AVN_MoodLpRedNValueSet 200;
BA_ "Version" SG_ 274 CF_AVN_MoodLpRedNValueSet "20.08.06";
BA_ "GenSigSendType" SG_ 274 CF_AVN_MoodLpGreenNValueSet 4;
BA_ "GenSigStartValue" SG_ 274 CF_AVN_MoodLpGreenNValueSet 512;
BA_ "UserSigValidity" SG_ 274 CF_AVN_MoodLpGreenNValueSet 3;
BA_ "NetworkRequest" SG_ 274 CF_AVN_MoodLpGreenNValueSet 0;
BA_ "NetworkRequestHoldingTime" SG_ 274 CF_AVN_MoodLpGreenNValueSet 200;
BA_ "Version" SG_ 274 CF_AVN_MoodLpGreenNValueSet "20.08.06";
BA_ "GenSigSendType" SG_ 274 CF_AVN_MoodLpBlueNValueSet 4;
BA_ "GenSigStartValue" SG_ 274 CF_AVN_MoodLpBlueNValueSet 512;
BA_ "UserSigValidity" SG_ 274 CF_AVN_MoodLpBlueNValueSet 3;
BA_ "NetworkRequest" SG_ 274 CF_AVN_MoodLpBlueNValueSet 0;
BA_ "NetworkRequestHoldingTime" SG_ 274 CF_AVN_MoodLpBlueNValueSet 200;
BA_ "Version" SG_ 274 CF_AVN_MoodLpBlueNValueSet "20.08.06";
BA_ "GenSigSendType" SG_ 274 CF_AVN_MoodLpBrightNValueSet 4;
BA_ "UserSigValidity" SG_ 274 CF_AVN_MoodLpBrightNValueSet 3;
BA_ "NetworkRequest" SG_ 274 CF_AVN_MoodLpBrightNValueSet 0;
BA_ "NetworkRequestHoldingTime" SG_ 274 CF_AVN_MoodLpBrightNValueSet 200;
BA_ "Version" SG_ 274 CF_AVN_MoodLpBrightNValueSet "20.08.06";
BA_ "GenSigSendType" SG_ 274 CF_AVN_HBANValueSet 4;
BA_ "UserSigValidity" SG_ 274 CF_AVN_HBANValueSet 3;
BA_ "Version" SG_ 274 CF_AVN_HBANValueSet "18.09.04";
BA_ "GenSigSendType" SG_ 274 CF_AVN_IFSActVehSpd_Set 4;
BA_ "UserSigValidity" SG_ 274 CF_AVN_IFSActVehSpd_Set 3;
BA_ "Version" SG_ 274 CF_AVN_IFSActVehSpd_Set "18.09.04";
BA_ "GenSigSendType" SG_ 274 C_MoodLpDrivingNValue 4;
BA_ "UserSigValidity" SG_ 274 C_MoodLpDrivingNValue 3;
BA_ "Version" SG_ 274 C_MoodLpDrivingNValue "18.09.04";
BA_ "Description" SG_ 274 HU_DrivingPostureAssistUSMSet "Driving Posture Assist - USM set on/off Request (R2.0)";
BA_ "GenSigSendType" SG_ 274 HU_DrivingPostureAssistUSMSet 4;
BA_ "GenSigStartValue" SG_ 274 HU_DrivingPostureAssistUSMSet 15;
BA_ "UserSigValidity" SG_ 274 HU_DrivingPostureAssistUSMSet 1;
BA_ "Version" SG_ 274 HU_DrivingPostureAssistUSMSet "23.07.03";
BA_ "GenSigSendType" SG_ 274 C_MoodLPDrivemodeNValue 4;
BA_ "UserSigValidity" SG_ 274 C_MoodLPDrivemodeNValue 3;
BA_ "Version" SG_ 274 C_MoodLPDrivemodeNValue "18.12.03";
BA_ "GenSigSendType" SG_ 274 CF_AVN_SVMAutoOnNvalueSet 4;
BA_ "UserSigValidity" SG_ 274 CF_AVN_SVMAutoOnNvalueSet 3;
BA_ "Version" SG_ 274 CF_AVN_SVMAutoOnNvalueSet "18.09.04";
BA_ "GenSigSendType" SG_ 274 CF_AVN_DAW_LVDANValueSet 4;
BA_ "UserSigValidity" SG_ 274 CF_AVN_DAW_LVDANValueSet 3;
BA_ "Version" SG_ 274 CF_AVN_DAW_LVDANValueSet "18.09.04";
BA_ "Description" SG_ 274 CF_AVN_Clu3dDepthSet "This signal is used for request to set the depth of 3D";
BA_ "GenSigSendType" SG_ 274 CF_AVN_Clu3dDepthSet 4;
BA_ "UserSigValidity" SG_ 274 CF_AVN_Clu3dDepthSet 3;
BA_ "Version" SG_ 274 CF_AVN_Clu3dDepthSet "19.03.08";
BA_ "Description" SG_ 274 C_MoodLpFadeNValue "This signal is for Navigation speed warning related ambient light(MLM) control fucntion.

This signal indicates MLM Fade in/out control.";
BA_ "GenSigSendType" SG_ 274 C_MoodLpFadeNValue 4;
BA_ "UserSigValidity" SG_ 274 C_MoodLpFadeNValue 3;
BA_ "Version" SG_ 274 C_MoodLpFadeNValue "20.01.01";
BA_ "Description" SG_ 274 HU_DrvCushAirSprtUSMSet "Driver seat Cushion air support set On/Off request (R2.0)";
BA_ "GenSigSendType" SG_ 274 HU_DrvCushAirSprtUSMSet 4;
BA_ "GenSigStartValue" SG_ 274 HU_DrvCushAirSprtUSMSet 7;
BA_ "UserSigValidity" SG_ 274 HU_DrvCushAirSprtUSMSet 1;
BA_ "Version" SG_ 274 HU_DrvCushAirSprtUSMSet "23.07.03";
BA_ "Description" SG_ 274 HU_AstCushAirSprtUSMSet "Assist seat Cushion air support set On/Off request (R2.0)";
BA_ "GenSigSendType" SG_ 274 HU_AstCushAirSprtUSMSet 4;
BA_ "GenSigStartValue" SG_ 274 HU_AstCushAirSprtUSMSet 7;
BA_ "UserSigValidity" SG_ 274 HU_AstCushAirSprtUSMSet 1;
BA_ "Version" SG_ 274 HU_AstCushAirSprtUSMSet "23.07.03";
BA_ "Description" SG_ 274 HU_DrvStrchMassageSwSet "Driver Seat massage operation set on/off request (R2.0)";
BA_ "GenSigSendType" SG_ 274 HU_DrvStrchMassageSwSet 4;
BA_ "GenSigStartValue" SG_ 274 HU_DrvStrchMassageSwSet 3;
BA_ "UserSigValidity" SG_ 274 HU_DrvStrchMassageSwSet 1;
BA_ "Version" SG_ 274 HU_DrvStrchMassageSwSet "23.07.03";
BA_ "Description" SG_ 274 HU_DrvStrchMassageModeUSMSet "Driver Seat massage Mode set request (R2.0)";
BA_ "GenSigSendType" SG_ 274 HU_DrvStrchMassageModeUSMSet 4;
BA_ "GenSigStartValue" SG_ 274 HU_DrvStrchMassageModeUSMSet 7;
BA_ "UserSigValidity" SG_ 274 HU_DrvStrchMassageModeUSMSet 1;
BA_ "Version" SG_ 274 HU_DrvStrchMassageModeUSMSet "23.07.03";
BA_ "Description" SG_ 274 HU_DrvStrchMassageStrengthUSMSet "Driver Seat massage Strength set request (R2.0)";
BA_ "GenSigSendType" SG_ 274 HU_DrvStrchMassageStrengthUSMSet 4;
BA_ "GenSigStartValue" SG_ 274 HU_DrvStrchMassageStrengthUSMSet 7;
BA_ "UserSigValidity" SG_ 274 HU_DrvStrchMassageStrengthUSMSet 1;
BA_ "Version" SG_ 274 HU_DrvStrchMassageStrengthUSMSet "23.07.03";
BA_ "Description" SG_ 274 HU_DrvStrchMassageTimeUSMSet "Driver Seat massage Time set request (R2.0)";
BA_ "GenSigSendType" SG_ 274 HU_DrvStrchMassageTimeUSMSet 4;
BA_ "GenSigStartValue" SG_ 274 HU_DrvStrchMassageTimeUSMSet 7;
BA_ "UserSigValidity" SG_ 274 HU_DrvStrchMassageTimeUSMSet 1;
BA_ "Version" SG_ 274 HU_DrvStrchMassageTimeUSMSet "23.07.03";
BA_ "Description" SG_ 274 HU_AstStrchMassageSwSet "Assist Seat massage operation set on/off request (R2.0)";
BA_ "GenSigSendType" SG_ 274 HU_AstStrchMassageSwSet 4;
BA_ "GenSigStartValue" SG_ 274 HU_AstStrchMassageSwSet 3;
BA_ "UserSigValidity" SG_ 274 HU_AstStrchMassageSwSet 1;
BA_ "Version" SG_ 274 HU_AstStrchMassageSwSet "23.07.03";
BA_ "Description" SG_ 274 HU_AstStrchMassageModeUSMSet "Assit Seat massage Mode set request (R2.0)";
BA_ "GenSigSendType" SG_ 274 HU_AstStrchMassageModeUSMSet 4;
BA_ "GenSigStartValue" SG_ 274 HU_AstStrchMassageModeUSMSet 7;
BA_ "UserSigValidity" SG_ 274 HU_AstStrchMassageModeUSMSet 1;
BA_ "Version" SG_ 274 HU_AstStrchMassageModeUSMSet "23.07.03";
BA_ "Description" SG_ 274 HU_AstStrchMassageStrengthUSMSet "Assist Seat massage Strength set request (R2.0)";
BA_ "GenSigSendType" SG_ 274 HU_AstStrchMassageStrengthUSMSet 4;
BA_ "GenSigStartValue" SG_ 274 HU_AstStrchMassageStrengthUSMSet 7;
BA_ "UserSigValidity" SG_ 274 HU_AstStrchMassageStrengthUSMSet 1;
BA_ "Version" SG_ 274 HU_AstStrchMassageStrengthUSMSet "23.07.03";
BA_ "Description" SG_ 274 HU_AstStrchMassageTimeUSMSet "Assist Seat massage Time set request (R2.0)";
BA_ "GenSigSendType" SG_ 274 HU_AstStrchMassageTimeUSMSet 4;
BA_ "GenSigStartValue" SG_ 274 HU_AstStrchMassageTimeUSMSet 7;
BA_ "UserSigValidity" SG_ 274 HU_AstStrchMassageTimeUSMSet 1;
BA_ "Version" SG_ 274 HU_AstStrchMassageTimeUSMSet "23.07.03";
BA_ "GenSigSendType" SG_ 274 CF_AVN_CluWelcomeSnd 4;
BA_ "UserSigValidity" SG_ 274 CF_AVN_CluWelcomeSnd 3;
BA_ "Version" SG_ 274 CF_AVN_CluWelcomeSnd "18.04.02";
BA_ "GenSigSendType" SG_ 274 CF_AVN_CluServiceReminderSet 4;
BA_ "UserSigValidity" SG_ 274 CF_AVN_CluServiceReminderSet 3;
BA_ "Version" SG_ 274 CF_AVN_CluServiceReminderSet "18.04.02";
BA_ "GenSigSendType" SG_ 274 CF_AVN_CluTransmissionDisp 4;
BA_ "UserSigValidity" SG_ 274 CF_AVN_CluTransmissionDisp 3;
BA_ "Version" SG_ 274 CF_AVN_CluTransmissionDisp "18.04.02";
BA_ "GenSigSendType" SG_ 274 CF_AVN_CluWiperLight 4;
BA_ "UserSigValidity" SG_ 274 CF_AVN_CluWiperLight 3;
BA_ "Version" SG_ 274 CF_AVN_CluWiperLight "18.04.02";
BA_ "GenSigSendType" SG_ 274 CF_AVN_CluRoadInfoGuide 4;
BA_ "UserSigValidity" SG_ 274 CF_AVN_CluRoadInfoGuide 3;
BA_ "Version" SG_ 274 CF_AVN_CluRoadInfoGuide "18.04.02";
BA_ "GenSigSendType" SG_ 274 CF_AVN_CluUserSettingPeriod 4;
BA_ "GenSigStartValue" SG_ 274 CF_AVN_CluUserSettingPeriod 127;
BA_ "UserSigValidity" SG_ 274 CF_AVN_CluUserSettingPeriod 3;
BA_ "Version" SG_ 274 CF_AVN_CluUserSettingPeriod "19.01.10";
BA_ "GenSigSendType" SG_ 274 CF_AVN_CluFuelEconUnit_mi 4;
BA_ "UserSigValidity" SG_ 274 CF_AVN_CluFuelEconUnit_mi 3;
BA_ "Version" SG_ 274 CF_AVN_CluFuelEconUnit_mi "18.09.04";
BA_ "GenSigSendType" SG_ 274 CF_AVN_CluFuelEconUnit_km 4;
BA_ "UserSigValidity" SG_ 274 CF_AVN_CluFuelEconUnit_km 3;
BA_ "Version" SG_ 274 CF_AVN_CluFuelEconUnit_km "20.08.02";
BA_ "GenSigSendType" SG_ 274 CF_AVN_CluUserSettingDistance 4;
BA_ "GenSigStartValue" SG_ 274 CF_AVN_CluUserSettingDistance 131071;
BA_ "UserSigValidity" SG_ 274 CF_AVN_CluUserSettingDistance 3;
BA_ "Version" SG_ 274 CF_AVN_CluUserSettingDistance "19.01.10";
BA_ "Description" SG_ 686 HU_Car_Crc1Val "The data area for CRC calculation is based on the data length (DLC) of the message DB.

The CRC shall be calculated over the entire data block (excluding the CRC bytes) including the user data, alive counter and Data ID



- CRC Polynomial (0x1021) , Ini";
BA_ "GenSigSendType" SG_ 686 HU_Car_Crc1Val 4;
BA_ "GenSigStartValue" SG_ 686 HU_Car_Crc1Val 65535;
BA_ "UserSigValidity" SG_ 686 HU_Car_Crc1Val 3;
BA_ "Version" SG_ 686 HU_Car_Crc1Val "22.10.20";
BA_ "Description" SG_ 686 HU_Car_AlvCnt1Val "For the first transmission request for a data element the counter shall be initialized with 0 and shall be incremented by 1 for every subsequent send request. 

When the counter reaches the maximum value(0xFF), then it shall restart with 0 for the next s";
BA_ "GenSigSendType" SG_ 686 HU_Car_AlvCnt1Val 4;
BA_ "UserSigValidity" SG_ 686 HU_Car_AlvCnt1Val 3;
BA_ "Version" SG_ 686 HU_Car_AlvCnt1Val "22.10.20";
BA_ "Description" SG_ 686 HU_MKBD_ModeSwitch "This signal is used for the 'AVNT/Climate Switching Keyboard' to switch the display of buttons.";
BA_ "GenSigSendType" SG_ 686 HU_MKBD_ModeSwitch 4;
BA_ "GenSigStartValue" SG_ 686 HU_MKBD_ModeSwitch 3;
BA_ "UserSigValidity" SG_ 686 HU_MKBD_ModeSwitch 1;
BA_ "Version" SG_ 686 HU_MKBD_ModeSwitch "20.12.04";
BA_ "Description" SG_ 686 HU_VehiclePwr "* Use HU_PwrState (@HU_Car_PE_01) in new ECU or Logic related with HU power state";
BA_ "GenSigSendType" SG_ 686 HU_VehiclePwr 4;
BA_ "UserSigValidity" SG_ 686 HU_VehiclePwr 0;
BA_ "NetworkRequest" SG_ 686 HU_VehiclePwr 0;
BA_ "NetworkRequestHoldingTime" SG_ 686 HU_VehiclePwr 5000;
BA_ "Version" SG_ 686 HU_VehiclePwr "22.05.02";
BA_ "Description" SG_ 686 HU_BtnShowReq "This signal indicates requesting turn on/off button light for H/Unit related buttons.";
BA_ "GenSigSendType" SG_ 686 HU_BtnShowReq 4;
BA_ "GenSigStartValue" SG_ 686 HU_BtnShowReq 7;
BA_ "UserSigValidity" SG_ 686 HU_BtnShowReq 0;
BA_ "NetworkRequest" SG_ 686 HU_BtnShowReq 0;
BA_ "NetworkRequestHoldingTime" SG_ 686 HU_BtnShowReq 5000;
BA_ "Version" SG_ 686 HU_BtnShowReq "19.11.01";
BA_ "Description" SG_ 686 HU_ADMSettingState "The signal transfers ADM Setting Value(On/Off) from HU to other module.";
BA_ "GenSigSendType" SG_ 686 HU_ADMSettingState 4;
BA_ "UserSigValidity" SG_ 686 HU_ADMSettingState 0;
BA_ "NetworkRequest" SG_ 686 HU_ADMSettingState 0;
BA_ "NetworkRequestHoldingTime" SG_ 686 HU_ADMSettingState 5000;
BA_ "Version" SG_ 686 HU_ADMSettingState "21.01.07";
BA_ "Description" SG_ 686 HU_PwrState "Information for the H/U power status



* Do not use HU_VehiclePwr (@HU_Car_PE_01) in new ECU or Logic related with HU power state";
BA_ "GenSigSendType" SG_ 686 HU_PwrState 4;
BA_ "UserSigValidity" SG_ 686 HU_PwrState 0;
BA_ "Version" SG_ 686 HU_PwrState "22.05.02";
BA_ "Description" SG_ 686 HU_LCDState "Information for H/U LCD (Monitor) On/Off Status";
BA_ "GenSigSendType" SG_ 686 HU_LCDState 4;
BA_ "UserSigValidity" SG_ 686 HU_LCDState 0;
BA_ "Version" SG_ 686 HU_LCDState "22.05.02";
BA_ "Description" SG_ 957 BLTN_CAM_FD_STAT_Crc1Val "The data area for CRC calculation is based on the data length (DLC) of the message DB.

The CRC shall be calculated over the entire data block (excluding the CRC bytes) including the user data, alive counter and Data ID



- CRC Polynomial (0x1021) , Ini";
BA_ "GenSigSendType" SG_ 957 BLTN_CAM_FD_STAT_Crc1Val 4;
BA_ "GenSigStartValue" SG_ 957 BLTN_CAM_FD_STAT_Crc1Val 65535;
BA_ "UserSigValidity" SG_ 957 BLTN_CAM_FD_STAT_Crc1Val 3;
BA_ "Version" SG_ 957 BLTN_CAM_FD_STAT_Crc1Val "22.11.04";
BA_ "Description" SG_ 957 BLTN_CAM_Prk_Oprable_Time "The hours of Park Mode Operatable, the time is limited by user max oper. Set.";
BA_ "GenSigSendType" SG_ 957 BLTN_CAM_Prk_Oprable_Time 4;
BA_ "UserSigValidity" SG_ 957 BLTN_CAM_Prk_Oprable_Time 1;
BA_ "Version" SG_ 957 BLTN_CAM_Prk_Oprable_Time "22.07.05";
BA_ "Description" SG_ 957 BLTN_CAM_Prk_Oprable_Time_Max "The hours of Park Mode Operatable, the time has no limit.";
BA_ "GenSigSendType" SG_ 957 BLTN_CAM_Prk_Oprable_Time_Max 4;
BA_ "UserSigValidity" SG_ 957 BLTN_CAM_Prk_Oprable_Time_Max 1;
BA_ "Version" SG_ 957 BLTN_CAM_Prk_Oprable_Time_Max "22.07.05";
BA_ "Description" SG_ 957 BLTN_CAM_AuxBat_Conn_State "The auxiliary Battery conntction information.";
BA_ "GenSigSendType" SG_ 957 BLTN_CAM_AuxBat_Conn_State 4;
BA_ "UserSigValidity" SG_ 957 BLTN_CAM_AuxBat_Conn_State 0;
BA_ "Version" SG_ 957 BLTN_CAM_AuxBat_Conn_State "23.07.05";
BA_ "Description" SG_ 957 BLTN_CAM_AuxBat_CapPer "The percentage of Aux. Bat.";
BA_ "GenSigSendType" SG_ 957 BLTN_CAM_AuxBat_CapPer 4;
BA_ "UserSigValidity" SG_ 957 BLTN_CAM_AuxBat_CapPer 1;
BA_ "Version" SG_ 957 BLTN_CAM_AuxBat_CapPer "21.05.02";
BA_ "Description" SG_ 957 BLTN_CAM_SWVerMajor "Indicate the Built-in Cam software version as follows:

- The software version is displayed in seven digits.

- The Major, Minor1, Minor2, Minor3 digits are separated by '.'

- Major Signal value is transmitted to ASCII codes.

- Minor1/Minor2/Minor2 Sig";
BA_ "GenSigSendType" SG_ 957 BLTN_CAM_SWVerMajor 4;
BA_ "UserSigValidity" SG_ 957 BLTN_CAM_SWVerMajor 0;
BA_ "Version" SG_ 957 BLTN_CAM_SWVerMajor "21.07.05";
BA_ "Description" SG_ 957 BLTN_CAM_SWVerMinor1 "Indicate the Built-in Cam software version as follows:

- The software version is displayed in seven digits.

- The Major, Minor1, Minor2, Minor3 digits are separated by '.'

- Major Signal value is transmitted to ASCII codes.

- Minor1/Minor2/Minor2 Sig";
BA_ "GenSigSendType" SG_ 957 BLTN_CAM_SWVerMinor1 4;
BA_ "UserSigValidity" SG_ 957 BLTN_CAM_SWVerMinor1 0;
BA_ "Version" SG_ 957 BLTN_CAM_SWVerMinor1 "21.07.05";
BA_ "Description" SG_ 957 BLTN_CAM_SWVerMinor2 "Indicate the Built-in Cam software version as follows:

- The software version is displayed in seven digits.

- The Major, Minor1, Minor2, Minor3 digits are separated by '.'

- Major Signal value is transmitted to ASCII codes.

- Minor1/Minor2/Minor2 Sig";
BA_ "GenSigSendType" SG_ 957 BLTN_CAM_SWVerMinor2 4;
BA_ "UserSigValidity" SG_ 957 BLTN_CAM_SWVerMinor2 0;
BA_ "Version" SG_ 957 BLTN_CAM_SWVerMinor2 "21.07.05";
BA_ "Description" SG_ 957 BLTN_CAM_SWVerMinor3 "Indicate the Built-in Cam software version as follows:

- The software version is displayed in seven digits.

- The Major, Minor1, Minor2, Minor3 digits are separated by '.'

- Major Signal value is transmitted to ASCII codes.

- Minor1/Minor2/Minor2 Sig";
BA_ "GenSigSendType" SG_ 957 BLTN_CAM_SWVerMinor3 4;
BA_ "UserSigValidity" SG_ 957 BLTN_CAM_SWVerMinor3 0;
BA_ "Version" SG_ 957 BLTN_CAM_SWVerMinor3 "21.07.05";
BA_ "Description" SG_ 957 BLTN_CAM_FD_STAT_AlvCnt1Val "For the first transmission request for a data element the counter shall be initialized with 0 and shall be incremented by 1 for every subsequent send request. 

When the counter reaches the maximum value(0xFF), then it shall restart with 0 for the next s";
BA_ "GenSigSendType" SG_ 957 BLTN_CAM_FD_STAT_AlvCnt1Val 4;
BA_ "UserSigValidity" SG_ 957 BLTN_CAM_FD_STAT_AlvCnt1Val 3;
BA_ "Version" SG_ 957 BLTN_CAM_FD_STAT_AlvCnt1Val "22.11.04";
BA_ "Description" SG_ 957 BLTN_CAM_SD_Card_Manufacturer "Built-in Cam SD Card Manufacturer Information";
BA_ "GenSigSendType" SG_ 957 BLTN_CAM_SD_Card_Manufacturer 4;
BA_ "UserSigValidity" SG_ 957 BLTN_CAM_SD_Card_Manufacturer 0;
BA_ "Version" SG_ 957 BLTN_CAM_SD_Card_Manufacturer "22.07.05";
BA_ "Description" SG_ 957 BLTN_CAM_SD_Card_Cap_Class "SD Card Storage Capacity Class";
BA_ "GenSigSendType" SG_ 957 BLTN_CAM_SD_Card_Cap_Class 4;
BA_ "UserSigValidity" SG_ 957 BLTN_CAM_SD_Card_Cap_Class 0;
BA_ "Version" SG_ 957 BLTN_CAM_SD_Card_Cap_Class "22.07.05";
BA_ "Description" SG_ 957 BLTN_CAM_PMD_Oprable_Time "the hours of Parked Motion Detection Mode Operatable";
BA_ "GenSigSendType" SG_ 957 BLTN_CAM_PMD_Oprable_Time 4;
BA_ "UserSigValidity" SG_ 957 BLTN_CAM_PMD_Oprable_Time 0;
BA_ "Version" SG_ 957 BLTN_CAM_PMD_Oprable_Time "24.01.05";
BA_ "Description" SG_ 957 BLTN_CAM_PMD_Oprable_Time_Max "the hours of Parked Motion Detection Mode Operatable Max";
BA_ "GenSigSendType" SG_ 957 BLTN_CAM_PMD_Oprable_Time_Max 4;
BA_ "UserSigValidity" SG_ 957 BLTN_CAM_PMD_Oprable_Time_Max 0;
BA_ "Version" SG_ 957 BLTN_CAM_PMD_Oprable_Time_Max "24.01.05";
BA_ "Description" SG_ 957 BLTN_CAM_RecSta_PMD "This Signal inform recording status of Parked Motion Detection.";
BA_ "GenSigSendType" SG_ 957 BLTN_CAM_RecSta_PMD 4;
BA_ "UserSigValidity" SG_ 957 BLTN_CAM_RecSta_PMD 0;
BA_ "Version" SG_ 957 BLTN_CAM_RecSta_PMD "24.01.09";
BA_ "Description" SG_ 957 BLTN_CAM_State "This Signal is for cluster warning popup.";
BA_ "GenSigSendType" SG_ 957 BLTN_CAM_State 4;
BA_ "UserSigValidity" SG_ 957 BLTN_CAM_State 1;
BA_ "Version" SG_ 957 BLTN_CAM_State "21.05.02";
BA_ "Description" SG_ 957 BLTN_CAM_SD_Card_State "This Signal is for SD card Status in Built-in App menu and CCS Phone App.";
BA_ "GenSigSendType" SG_ 957 BLTN_CAM_SD_Card_State 4;
BA_ "UserSigValidity" SG_ 957 BLTN_CAM_SD_Card_State 0;
BA_ "NetworkRequest" SG_ 957 BLTN_CAM_SD_Card_State 0;
BA_ "NetworkRequestHoldingTime" SG_ 957 BLTN_CAM_SD_Card_State 1000;
BA_ "Version" SG_ 957 BLTN_CAM_SD_Card_State "22.05.02";
BA_ "Description" SG_ 957 BLTN_CAM_RecSta_OWD "This Signal inform recording status of On While Driving.";
BA_ "GenSigSendType" SG_ 957 BLTN_CAM_RecSta_OWD 4;
BA_ "UserSigValidity" SG_ 957 BLTN_CAM_RecSta_OWD 1;
BA_ "Version" SG_ 957 BLTN_CAM_RecSta_OWD "21.05.02";
BA_ "Description" SG_ 957 BLTN_CAM_RecSta_DEV "This Signal inform recording status of Driving Event.";
BA_ "GenSigSendType" SG_ 957 BLTN_CAM_RecSta_DEV 4;
BA_ "UserSigValidity" SG_ 957 BLTN_CAM_RecSta_DEV 1;
BA_ "Version" SG_ 957 BLTN_CAM_RecSta_DEV "21.05.02";
BA_ "Description" SG_ 957 BLTN_CAM_RecSta_MAR "This Signal inform recording status of Manual Recording.";
BA_ "GenSigSendType" SG_ 957 BLTN_CAM_RecSta_MAR 4;
BA_ "UserSigValidity" SG_ 957 BLTN_CAM_RecSta_MAR 1;
BA_ "Version" SG_ 957 BLTN_CAM_RecSta_MAR "21.05.02";
BA_ "Description" SG_ 957 BLTN_CAM_RecSta_TML "This Signal inform recording status of Time-lapse.";
BA_ "GenSigSendType" SG_ 957 BLTN_CAM_RecSta_TML 4;
BA_ "UserSigValidity" SG_ 957 BLTN_CAM_RecSta_TML 1;
BA_ "Version" SG_ 957 BLTN_CAM_RecSta_TML "21.05.02";
BA_ "Description" SG_ 957 BLTN_CAM_RecSta_OWP "This Signal inform recording status of On While Parked.";
BA_ "GenSigSendType" SG_ 957 BLTN_CAM_RecSta_OWP 4;
BA_ "UserSigValidity" SG_ 957 BLTN_CAM_RecSta_OWP 1;
BA_ "Version" SG_ 957 BLTN_CAM_RecSta_OWP "21.05.02";
BA_ "Description" SG_ 957 BLTN_CAM_RecSta_PEV "This Signal inform recording status of Parked Event.";
BA_ "GenSigSendType" SG_ 957 BLTN_CAM_RecSta_PEV 4;
BA_ "UserSigValidity" SG_ 957 BLTN_CAM_RecSta_PEV 1;
BA_ "Version" SG_ 957 BLTN_CAM_RecSta_PEV "21.05.02";
BA_ "Description" SG_ 957 BLTN_CAM_Prk_EV_Cnt "The count number of a parked Event.";
BA_ "GenSigSendType" SG_ 957 BLTN_CAM_Prk_EV_Cnt 4;
BA_ "UserSigValidity" SG_ 957 BLTN_CAM_Prk_EV_Cnt 1;
BA_ "Version" SG_ 957 BLTN_CAM_Prk_EV_Cnt "21.05.02";
BA_ "Description" SG_ 957 BLTN_CAM_Prk_Oped_Time "The Parked Opreated time ingormation";
BA_ "GenSigSendType" SG_ 957 BLTN_CAM_Prk_Oped_Time 4;
BA_ "UserSigValidity" SG_ 957 BLTN_CAM_Prk_Oped_Time 1;
BA_ "Version" SG_ 957 BLTN_CAM_Prk_Oped_Time "22.07.05";
BA_ "Description" SG_ 69 HTCU_Crc4Val "The data area for CRC calculation is based on the data length (DLC) of the message DB.

The CRC shall be calculated over the entire data block (excluding the CRC bytes) including the user data, alive counter and Data ID

 

- CRC Polynomial (0x1021) , In";
BA_ "GenSigStartValue" SG_ 69 HTCU_Crc4Val 65535;
BA_ "UserSigValidity" SG_ 69 HTCU_Crc4Val 3;
BA_ "RoutingFactor" SG_ 69 HTCU_Crc4Val 5;
BA_ "Version" SG_ 69 HTCU_Crc4Val "18.11.08";
BA_ "Description" SG_ 69 HTCU_CtrlablSta "This signal indicates the status of the TCU control which normally works by hydraulic pressure in the T/M";
BA_ "UserSigValidity" SG_ 69 HTCU_CtrlablSta 3;
BA_ "RoutingFactor" SG_ 69 HTCU_CtrlablSta 5;
BA_ "Version" SG_ 69 HTCU_CtrlablSta "20.10.02";
BA_ "Description" SG_ 69 HTCU_PrgrmSta "This signal informs about current program status in HTCU";
BA_ "UserSigValidity" SG_ 69 HTCU_PrgrmSta 3;
BA_ "RoutingFactor" SG_ 69 HTCU_PrgrmSta 5;
BA_ "Version" SG_ 69 HTCU_PrgrmSta "17.11.00";
BA_ "Description" SG_ 69 HTCU_FsCltchLmphmActvSta "This signal informs about engine clutch limp-home control activation";
BA_ "UserSigValidity" SG_ 69 HTCU_FsCltchLmphmActvSta 3;
BA_ "RoutingFactor" SG_ 69 HTCU_FsCltchLmphmActvSta 5;
BA_ "Version" SG_ 69 HTCU_FsCltchLmphmActvSta "17.11.00";
BA_ "Description" SG_ 69 HTCU_FsIdleTrgtRpmVal "Request idle target rpm for engine clutch limp-home control";
BA_ "UserSigValidity" SG_ 69 HTCU_FsIdleTrgtRpmVal 3;
BA_ "RoutingFactor" SG_ 69 HTCU_FsIdleTrgtRpmVal 5;
BA_ "Version" SG_ 69 HTCU_FsIdleTrgtRpmVal "17.11.00";
BA_ "Description" SG_ 69 HTCU_FsAddtnlTqLssPcVal "Additional torque loss for engine clutch limp-home control";
BA_ "UserSigValidity" SG_ 69 HTCU_FsAddtnlTqLssPcVal 3;
BA_ "RoutingFactor" SG_ 69 HTCU_FsAddtnlTqLssPcVal 5;
BA_ "Version" SG_ 69 HTCU_FsAddtnlTqLssPcVal "17.11.00";
BA_ "Description" SG_ 69 HTCU_FsEngTqRdctnPcVal "This signal informs about engine torque reduction request for engine clutch limp-home control";
BA_ "GenSigStartValue" SG_ 69 HTCU_FsEngTqRdctnPcVal 255;
BA_ "UserSigValidity" SG_ 69 HTCU_FsEngTqRdctnPcVal 3;
BA_ "RoutingFactor" SG_ 69 HTCU_FsEngTqRdctnPcVal 5;
BA_ "Version" SG_ 69 HTCU_FsEngTqRdctnPcVal "19.02.06";
BA_ "Description" SG_ 69 HTCU_LnPrsBarVal "This signal informs about the Transmission valve body line pressure command from HTCU";
BA_ "UserSigValidity" SG_ 69 HTCU_LnPrsBarVal 3;
BA_ "RoutingFactor" SG_ 69 HTCU_LnPrsBarVal 5;
BA_ "Version" SG_ 69 HTCU_LnPrsBarVal "17.11.00";
BA_ "Description" SG_ 69 HTCU_RapidKDReq "Rapid K/D Shift Request";
BA_ "UserSigValidity" SG_ 69 HTCU_RapidKDReq 3;
BA_ "RoutingFactor" SG_ 69 HTCU_RapidKDReq 5;
BA_ "Version" SG_ 69 HTCU_RapidKDReq "17.11.00";
BA_ "UserSigValidity" SG_ 69 HTCU_CurrGearSta 3;
BA_ "RoutingFactor" SG_ 69 HTCU_CurrGearSta 5;
BA_ "Version" SG_ 69 HTCU_CurrGearSta "18.12.07";
BA_ "Description" SG_ 69 HTCU_GearShftUpDisGSI "Gear Shift-up display status for Gear shift indicator (EU Regulations)";
BA_ "UserSigValidity" SG_ 69 HTCU_GearShftUpDisGSI 3;
BA_ "RoutingFactor" SG_ 69 HTCU_GearShftUpDisGSI 5;
BA_ "Version" SG_ 69 HTCU_GearShftUpDisGSI "18.08.01";
BA_ "Description" SG_ 69 HTCU_GearShftDnDisGSI "Gear Shift-down display status for Gear shift indicator (EU Regulations)";
BA_ "UserSigValidity" SG_ 69 HTCU_GearShftDnDisGSI 3;
BA_ "RoutingFactor" SG_ 69 HTCU_GearShftDnDisGSI 5;
BA_ "Version" SG_ 69 HTCU_GearShftDnDisGSI "18.08.01";
BA_ "Description" SG_ 69 HTCU_TrgtGearStaGSI "Target Gear for Gear shift indicator (EU Regulations)";
BA_ "UserSigValidity" SG_ 69 HTCU_TrgtGearStaGSI 3;
BA_ "RoutingFactor" SG_ 69 HTCU_TrgtGearStaGSI 5;
BA_ "Version" SG_ 69 HTCU_TrgtGearStaGSI "19.02.06";
BA_ "Description" SG_ 69 HTCU_SolBSta "Status of On/Off Solenoid B";
BA_ "UserSigValidity" SG_ 69 HTCU_SolBSta 3;
BA_ "RoutingFactor" SG_ 69 HTCU_SolBSta 5;
BA_ "Version" SG_ 69 HTCU_SolBSta "18.08.01";
BA_ "Description" SG_ 69 HTCU_AlvCnt4Val "For the first transmission request for a data element the counter shall be initialized with 0 and shall be incremented by 1 for every subsequent send request. 

When the counter reaches the maximum value(0xFF), then it shall restart with 0 for the next s";
BA_ "UserSigValidity" SG_ 69 HTCU_AlvCnt4Val 3;
BA_ "RoutingFactor" SG_ 69 HTCU_AlvCnt4Val 5;
BA_ "Version" SG_ 69 HTCU_AlvCnt4Val "18.11.08";
BA_ "Description" SG_ 69 HTCU_TqRdctnNegativePcVal "Torque intervention for negative reduction,referred to the indicated torque.





<Range>

-200 ~ 199.61% = 0x200 ~ 0x1FF



<Conversion>

If MSB of high byte is 1,(PH) = 0.390625 x (HEX) - 400[%],

Else,(PH) = 0.390625 x (HEX) [%]";
BA_ "GenSigStartValue" SG_ 69 HTCU_TqRdctnNegativePcVal 8191;
BA_ "UserSigValidity" SG_ 69 HTCU_TqRdctnNegativePcVal 3;
BA_ "RoutingFactor" SG_ 69 HTCU_TqRdctnNegativePcVal 5;
BA_ "Version" SG_ 69 HTCU_TqRdctnNegativePcVal "23.03.00";
BA_ "Description" SG_ 69 HTCU_TrgtGearSta "HTCU_TrgtGearSta informs about the speed, which is currently engaged in the gearbox, or, in case of a gear change (HTCU_GearChgSta), which speed is reached.

Note: Gear changes covering more than one speed are also possible.

In the P and N positions, th";
BA_ "UserSigValidity" SG_ 69 HTCU_TrgtGearSta 3;
BA_ "RoutingFactor" SG_ 69 HTCU_TrgtGearSta 5;
BA_ "Version" SG_ 69 HTCU_TrgtGearSta "18.12.07";
BA_ "Description" SG_ 69 HTCU_RdySta "Flag that the HTCU is ready to work. (In fact, this flag is true from the moment that CAN is working. So, normally no “false” will be sent on CAN.) This flag does not show that everything is alright in the HTCU. This information is given in the warning";
BA_ "UserSigValidity" SG_ 69 HTCU_RdySta 3;
BA_ "RoutingFactor" SG_ 69 HTCU_RdySta 5;
BA_ "Version" SG_ 69 HTCU_RdySta "18.08.02";
BA_ "Description" SG_ 69 HTCU_GearChgSta "HTCU_GearChgSta indicates whether a gear change is being executed in the gearbox.

Note : Gear change means a gear shift at D-range and Garage shift(PRND).";
BA_ "UserSigValidity" SG_ 69 HTCU_GearChgSta 3;
BA_ "RoutingFactor" SG_ 69 HTCU_GearChgSta 5;
BA_ "Version" SG_ 69 HTCU_GearChgSta "18.08.02";
BA_ "Description" SG_ 69 HTCU_TqRdctnPcVal "The HTCU requests a torque reduction via the signal CR_Tcu_TqInt_Pc to the ECU and MCU.

The requested torque HTCU_TqRdctnPcVal refers to a maximum torque CR_Ems_TqStd_Nm. This conversion into a physical quantity provides a range of CR_Ems_TqStd_Nm of 0 ";
BA_ "GenSigStartValue" SG_ 69 HTCU_TqRdctnPcVal 511;
BA_ "UserSigValidity" SG_ 69 HTCU_TqRdctnPcVal 3;
BA_ "RoutingFactor" SG_ 69 HTCU_TqRdctnPcVal 5;
BA_ "Version" SG_ 69 HTCU_TqRdctnPcVal "18.08.02";
BA_ "Description" SG_ 69 HTCU_FltSta "HTCU_FltSta informs about status of transmission control.



<Value Description>

Bit 0: HTCU Diagnostic failure

Bit 1: HTCU Diagnostic failure ? Limphome activated

Bit 2: OPU/EOP Diagnostic failure";
BA_ "UserSigValidity" SG_ 69 HTCU_FltSta 3;
BA_ "RoutingFactor" SG_ 69 HTCU_FltSta 5;
BA_ "Version" SG_ 69 HTCU_FltSta "18.08.02";
BA_ "Description" SG_ 69 HTCU_GearSlctrDis "Position (P, R, N..), which was identified by the gear selector.

In case the gear selector is in a intermediate position, the last clear recognized position is used.

There is no specific phase relationship between the output and any other signal.";
BA_ "GenSigStartValue" SG_ 69 HTCU_GearSlctrDis 9;
BA_ "UserSigValidity" SG_ 69 HTCU_GearSlctrDis 3;
BA_ "RoutingFactor" SG_ 69 HTCU_GearSlctrDis 5;
BA_ "Version" SG_ 69 HTCU_GearSlctrDis "18.08.02";
BA_ "Description" SG_ 69 HTCU_SlwTqRdctnPcVal "The HTCU requests a slow torque reduction via the signal HTCU_TqRdctnPcVal to the ECU and MCU.";
BA_ "GenSigStartValue" SG_ 69 HTCU_SlwTqRdctnPcVal 511;
BA_ "UserSigValidity" SG_ 69 HTCU_SlwTqRdctnPcVal 3;
BA_ "RoutingFactor" SG_ 69 HTCU_SlwTqRdctnPcVal 5;
BA_ "Version" SG_ 69 HTCU_SlwTqRdctnPcVal "18.08.02";
BA_ "UserSigValidity" SG_ 69 HTCU_PddlShftUpDn 3;
BA_ "RoutingFactor" SG_ 69 HTCU_PddlShftUpDn 5;
BA_ "Version" SG_ 69 HTCU_PddlShftUpDn "22.10.20";
BA_ "Description" SG_ 69 HTCU_FanCtrlReq "Fan control request by OPU";
BA_ "TimeoutValue" SG_ 69 HTCU_FanCtrlReq "0x0";
BA_ "UserSigValidity" SG_ 69 HTCU_FanCtrlReq 3;
BA_ "RoutingFactor" SG_ 69 HTCU_FanCtrlReq 5;
BA_ "Version" SG_ 69 HTCU_FanCtrlReq "21.07.00";
BA_ "Description" SG_ 69 HTCU_VehSpdKphVal "The vehicle speed calculated by HTCU is transferred.

If a vehicle has no vehicle speed sensor, no wheel speed sensor and no ABS(ESC) then it is impossible for an EMS to calculate veficle speed. In this case a HTCU should calculate vehicle speed and send";
BA_ "UserSigValidity" SG_ 69 HTCU_VehSpdKphVal 3;
BA_ "RoutingFactor" SG_ 69 HTCU_VehSpdKphVal 5;
BA_ "Version" SG_ 69 HTCU_VehSpdKphVal "18.08.02";
BA_ "Description" SG_ 69 HTCU_VehSpdDcmlKphVal "The signal HTCU_VehSpdDcmlKphVal means the value which is below decimal point of the vehicle speed.

For instance, if a vehicle speed is 13.75Km/h, HTCU_VehSpdKphVal means 13Km/h and HTCU_VehSpdDcmlKphVal means 0.75Km/h.

(Min ~ Max: 0.00 ~ 0.99)";
BA_ "UserSigValidity" SG_ 69 HTCU_VehSpdDcmlKphVal 3;
BA_ "RoutingFactor" SG_ 69 HTCU_VehSpdDcmlKphVal 5;
BA_ "Version" SG_ 69 HTCU_VehSpdDcmlKphVal "18.12.07";
BA_ "Description" SG_ 69 HTCU_HvOpuSpdCmdRpmVal "CR_Tcu_OpuSpdCmd_Rpm informs about the external oil pump speed.";
BA_ "UserSigValidity" SG_ 69 HTCU_HvOpuSpdCmdRpmVal 3;
BA_ "RoutingFactor" SG_ 69 HTCU_HvOpuSpdCmdRpmVal 5;
BA_ "Version" SG_ 69 HTCU_HvOpuSpdCmdRpmVal "17.11.00";
BA_ "UserSigValidity" SG_ 69 HTCU_TrgtShftClsCCanSta 3;
BA_ "RoutingFactor" SG_ 69 HTCU_TrgtShftClsCCanSta 5;
BA_ "Version" SG_ 69 HTCU_TrgtShftClsCCanSta "17.11.00";
BA_ "Description" SG_ 685 HU_BLTN_CAM_Crc2Val "The data area for CRC calculation is based on the data length (DLC) of the message DB.

The CRC shall be calculated over the entire data block (excluding the CRC bytes) including the user data, alive counter and Data ID



- CRC Polynomial (0x1021) , Ini";
BA_ "GenSigSendType" SG_ 685 HU_BLTN_CAM_Crc2Val 4;
BA_ "GenSigStartValue" SG_ 685 HU_BLTN_CAM_Crc2Val 65535;
BA_ "UserSigValidity" SG_ 685 HU_BLTN_CAM_Crc2Val 3;
BA_ "Version" SG_ 685 HU_BLTN_CAM_Crc2Val "22.10.20";
BA_ "Description" SG_ 685 HU_BLTN_CAM_AlvCnt2Val "For the first transmission request for a data element the counter shall be initialized with 0 and shall be incremented by 1 for every subsequent send request. 

When the counter reaches the maximum value(0xFF), then it shall restart with 0 for the next s";
BA_ "GenSigSendType" SG_ 685 HU_BLTN_CAM_AlvCnt2Val 4;
BA_ "UserSigValidity" SG_ 685 HU_BLTN_CAM_AlvCnt2Val 3;
BA_ "Version" SG_ 685 HU_BLTN_CAM_AlvCnt2Val "22.10.20";
BA_ "Description" SG_ 685 HU_BLTN_CAM_UI_Mode "Display control of Built-in Cam UI mode. This Signal for Ethernet Type Built-in Cam.";
BA_ "GenSigSendType" SG_ 685 HU_BLTN_CAM_UI_Mode 4;
BA_ "UserSigValidity" SG_ 685 HU_BLTN_CAM_UI_Mode 0;
BA_ "Version" SG_ 685 HU_BLTN_CAM_UI_Mode "22.07.05";
BA_ "Description" SG_ 685 HU_BLTN_CAM_Display "Display control of Built-in Cam UI mode. This Signal for CAN Type Built-in Cam.(with Standard 5th Wide AVNT)";
BA_ "GenSigSendType" SG_ 685 HU_BLTN_CAM_Display 4;
BA_ "UserSigValidity" SG_ 685 HU_BLTN_CAM_Display 1;
BA_ "Version" SG_ 685 HU_BLTN_CAM_Display "22.07.05";
BA_ "Description" SG_ 138 HU_GW_Crc1Val "The data area for CRC calculation is based on the data length (DLC) of the message DB.

The CRC shall be calculated over the entire data block (excluding the CRC bytes) including the user data, alive counter and Data ID



- CRC Polynomial (0x1021) , Ini";
BA_ "GenSigSendType" SG_ 138 HU_GW_Crc1Val 4;
BA_ "GenSigStartValue" SG_ 138 HU_GW_Crc1Val 65535;
BA_ "UserSigValidity" SG_ 138 HU_GW_Crc1Val 3;
BA_ "Version" SG_ 138 HU_GW_Crc1Val "22.10.20";
BA_ "GenSigSendType" SG_ 138 HU_TgSoc_QcChg_Set 4;
BA_ "GenSigStartValue" SG_ 138 HU_TgSoc_QcChg_Set 255;
BA_ "UserSigValidity" SG_ 138 HU_TgSoc_QcChg_Set 7;
BA_ "Version" SG_ 138 HU_TgSoc_QcChg_Set "18.09.04";
BA_ "Description" SG_ 138 HU_UserApproval "Signal to send user decision on OTA approval.";
BA_ "GenSigSendType" SG_ 138 HU_UserApproval 4;
BA_ "UserSigValidity" SG_ 138 HU_UserApproval 0;
BA_ "Version" SG_ 138 HU_UserApproval "23.02.02";
BA_ "Description" SG_ 138 HU_OtaInfomationReq "제어기 OTA 관련 필요 정보를 요청하는 신호 (SW 버전, What's New, Download 진행율, Update 진행율)";
BA_ "GenSigSendType" SG_ 138 HU_OtaInfomationReq 4;
BA_ "UserSigValidity" SG_ 138 HU_OtaInfomationReq 0;
BA_ "Version" SG_ 138 HU_OtaInfomationReq "19.12.01";
BA_ "Description" SG_ 138 HU_ICU_RearDefSet "Rear window defog control";
BA_ "GenSigSendType" SG_ 138 HU_ICU_RearDefSet 4;
BA_ "GenSigStartValue" SG_ 138 HU_ICU_RearDefSet 3;
BA_ "UserSigValidity" SG_ 138 HU_ICU_RearDefSet 3;
BA_ "Version" SG_ 138 HU_ICU_RearDefSet "20.01.02";
BA_ "Description" SG_ 138 HU_CDMOpenCmd "Command for CDM open/close";
BA_ "GenSigSendType" SG_ 138 HU_CDMOpenCmd 4;
BA_ "UserSigValidity" SG_ 138 HU_CDMOpenCmd 7;
BA_ "Version" SG_ 138 HU_CDMOpenCmd "20.01.02";
BA_ "GenSigSendType" SG_ 138 C_PreCrankReq 4;
BA_ "UserSigValidity" SG_ 138 C_PreCrankReq 0;
BA_ "NetworkRequest" SG_ 138 C_PreCrankReq 0;
BA_ "Version" SG_ 138 C_PreCrankReq "18.09.04";
BA_ "Description" SG_ 138 HU_GW_AlvCnt1Val "For the first transmission request for a data element the counter shall be initialized with 0 and shall be incremented by 1 for every subsequent send request. 

When the counter reaches the maximum value(0xFF), then it shall restart with 0 for the next s";
BA_ "GenSigSendType" SG_ 138 HU_GW_AlvCnt1Val 4;
BA_ "UserSigValidity" SG_ 138 HU_GW_AlvCnt1Val 3;
BA_ "Version" SG_ 138 HU_GW_AlvCnt1Val "22.10.20";
BA_ "GenSigSendType" SG_ 138 C_TeleAstSeatOpCmdIBOX 4;
BA_ "UserSigValidity" SG_ 138 C_TeleAstSeatOpCmdIBOX 3;
BA_ "Version" SG_ 138 C_TeleAstSeatOpCmdIBOX "18.09.04";
BA_ "GenSigSendType" SG_ 138 C_TeleDrvSeatOpCmdIBOX 4;
BA_ "UserSigValidity" SG_ 138 C_TeleDrvSeatOpCmdIBOX 3;
BA_ "Version" SG_ 138 C_TeleDrvSeatOpCmdIBOX "18.09.04";
BA_ "GenSigSendType" SG_ 138 C_TeleRRSeatOpCmdIBOX 4;
BA_ "UserSigValidity" SG_ 138 C_TeleRRSeatOpCmdIBOX 3;
BA_ "Version" SG_ 138 C_TeleRRSeatOpCmdIBOX "18.09.04";
BA_ "GenSigSendType" SG_ 138 C_TeleRLSeatOpCmdIBOX 4;
BA_ "UserSigValidity" SG_ 138 C_TeleRLSeatOpCmdIBOX 3;
BA_ "Version" SG_ 138 C_TeleRLSeatOpCmdIBOX "18.09.04";
BA_ "Description" SG_ 138 HU_StrgWhlHeatingSet_VR "Command for VR Heating Control (Steering Wheel 1/2step)";
BA_ "GenSigSendType" SG_ 138 HU_StrgWhlHeatingSet_VR 4;
BA_ "GenSigStartValue" SG_ 138 HU_StrgWhlHeatingSet_VR 7;
BA_ "UserSigValidity" SG_ 138 HU_StrgWhlHeatingSet_VR 7;
BA_ "NetworkRequest" SG_ 138 HU_StrgWhlHeatingSet_VR 0;
BA_ "NetworkRequestHoldingTime" SG_ 138 HU_StrgWhlHeatingSet_VR 2000;
BA_ "Version" SG_ 138 HU_StrgWhlHeatingSet_VR "21.12.00";
BA_ "Description" SG_ 138 AVN_VGS_SET "on/off setting of VGS";
BA_ "GenSigSendType" SG_ 138 AVN_VGS_SET 4;
BA_ "UserSigValidity" SG_ 138 AVN_VGS_SET 3;
BA_ "Version" SG_ 138 AVN_VGS_SET "21.11.07";
BA_ "Description" SG_ 138 MODE_VCU_SET2 "Set the VCU setting in custom mode 2";
BA_ "GenSigSendType" SG_ 138 MODE_VCU_SET2 4;
BA_ "UserSigValidity" SG_ 138 MODE_VCU_SET2 3;
BA_ "Version" SG_ 138 MODE_VCU_SET2 "21.11.07";
BA_ "Description" SG_ 138 AVN_DriftMode_SET "on/off setting of Drift Mode";
BA_ "GenSigSendType" SG_ 138 AVN_DriftMode_SET 4;
BA_ "UserSigValidity" SG_ 138 AVN_DriftMode_SET 3;
BA_ "Version" SG_ 138 AVN_DriftMode_SET "21.12.00";
BA_ "Description" SG_ 138 AVN_NduranceRace_SET "Track Optimizer on/off setting";
BA_ "GenSigSendType" SG_ 138 AVN_NduranceRace_SET 4;
BA_ "UserSigValidity" SG_ 138 AVN_NduranceRace_SET 3;
BA_ "Version" SG_ 138 AVN_NduranceRace_SET "23.02.02";
BA_ "Description" SG_ 138 AVN_MaxRange_SET "AVNT Performance Limit Extender on/off setting";
BA_ "GenSigSendType" SG_ 138 AVN_MaxRange_SET 4;
BA_ "UserSigValidity" SG_ 138 AVN_MaxRange_SET 3;
BA_ "Version" SG_ 138 AVN_MaxRange_SET "23.02.02";
BA_ "Description" SG_ 138 HU_MKBD_TouchSensSet "MKBD touch sensitivity set signal";
BA_ "GenSigSendType" SG_ 138 HU_MKBD_TouchSensSet 4;
BA_ "UserSigValidity" SG_ 138 HU_MKBD_TouchSensSet 1;
BA_ "Version" SG_ 138 HU_MKBD_TouchSensSet "23.02.10";
BA_ "Description" SG_ 138 AVN_NTDBalance_SET "Power balance setting. This value means front wheel power.";
BA_ "GenSigSendType" SG_ 138 AVN_NTDBalance_SET 4;
BA_ "UserSigValidity" SG_ 138 AVN_NTDBalance_SET 3;
BA_ "Version" SG_ 138 AVN_NTDBalance_SET "23.02.02";
BA_ "Description" SG_ 138 LaunchControl_Activate_EV "Launch control on/off setting for EV N vehicles";
BA_ "GenSigSendType" SG_ 138 LaunchControl_Activate_EV 4;
BA_ "UserSigValidity" SG_ 138 LaunchControl_Activate_EV 3;
BA_ "Version" SG_ 138 LaunchControl_Activate_EV "22.01.06";
BA_ "Description" SG_ 138 LaunchControl_GripLevel_Reset "Initialize grip level reset. When 0x2 value is transmitted from HU, VCU changes grip level setting to default value.";
BA_ "GenSigSendType" SG_ 138 LaunchControl_GripLevel_Reset 4;
BA_ "UserSigValidity" SG_ 138 LaunchControl_GripLevel_Reset 3;
BA_ "Version" SG_ 138 LaunchControl_GripLevel_Reset "22.01.06";
BA_ "Description" SG_ 138 LaunchControl_GripLevel_Set "Launch control grip level setting";
BA_ "GenSigSendType" SG_ 138 LaunchControl_GripLevel_Set 4;
BA_ "UserSigValidity" SG_ 138 LaunchControl_GripLevel_Set 3;
BA_ "Version" SG_ 138 LaunchControl_GripLevel_Set "22.01.06";
BA_ "Description" SG_ 138 MODE_Drift_TCS_SET "setting value for TCS of drift optimizer";
BA_ "GenSigSendType" SG_ 138 MODE_Drift_TCS_SET 4;
BA_ "UserSigValidity" SG_ 138 MODE_Drift_TCS_SET 3;
BA_ "Version" SG_ 138 MODE_Drift_TCS_SET "22.06.04";
BA_ "Description" SG_ 138 MODE_Drift_VDC_SET "setting value for VDC of drift optimizer";
BA_ "GenSigSendType" SG_ 138 MODE_Drift_VDC_SET 4;
BA_ "UserSigValidity" SG_ 138 MODE_Drift_VDC_SET 3;
BA_ "Version" SG_ 138 MODE_Drift_VDC_SET "22.06.04";
BA_ "Description" SG_ 138 HU_Popupdown_Req "Request for Monitor Pop-up/down control";
BA_ "GenSigSendType" SG_ 138 HU_Popupdown_Req 4;
BA_ "UserSigValidity" SG_ 138 HU_Popupdown_Req 1;
BA_ "Version" SG_ 138 HU_Popupdown_Req "23.07.02";
BA_ "Description" SG_ 138 MODE_Drift_MDPS_SET "setting value for MDPS of drift optimizer";
BA_ "GenSigSendType" SG_ 138 MODE_Drift_MDPS_SET 4;
BA_ "UserSigValidity" SG_ 138 MODE_Drift_MDPS_SET 3;
BA_ "Version" SG_ 138 MODE_Drift_MDPS_SET "22.06.04";
BA_ "Description" SG_ 138 MODE_Drift_ECS_SET "setting value for ECS of drift optimizer";
BA_ "GenSigSendType" SG_ 138 MODE_Drift_ECS_SET 4;
BA_ "UserSigValidity" SG_ 138 MODE_Drift_ECS_SET 3;
BA_ "Version" SG_ 138 MODE_Drift_ECS_SET "22.06.04";
BA_ "Description" SG_ 138 MODE_Drift_ELSD_SET "setting value for ELSD of drift optimizer";
BA_ "GenSigSendType" SG_ 138 MODE_Drift_ELSD_SET 4;
BA_ "UserSigValidity" SG_ 138 MODE_Drift_ELSD_SET 3;
BA_ "Version" SG_ 138 MODE_Drift_ELSD_SET "22.06.04";
BA_ "Description" SG_ 138 HU_NCond_DragSet "N conditioning drag on/off setting value";
BA_ "GenSigSendType" SG_ 138 HU_NCond_DragSet 4;
BA_ "UserSigValidity" SG_ 138 HU_NCond_DragSet 3;
BA_ "Version" SG_ 138 HU_NCond_DragSet "22.07.05";
BA_ "Description" SG_ 138 HU_NCond_TrackSet "N conditioning track on/off setting value";
BA_ "GenSigSendType" SG_ 138 HU_NCond_TrackSet 4;
BA_ "UserSigValidity" SG_ 138 HU_NCond_TrackSet 3;
BA_ "Version" SG_ 138 HU_NCond_TrackSet "22.07.05";
BA_ "Description" SG_ 138 AVN_Npedal_SET "N pedal on/off setting";
BA_ "GenSigSendType" SG_ 138 AVN_Npedal_SET 4;
BA_ "UserSigValidity" SG_ 138 AVN_Npedal_SET 3;
BA_ "Version" SG_ 138 AVN_Npedal_SET "22.10.20";
BA_ "Description" SG_ 138 AVN_NTD_SET "on/off setting of NTC";
BA_ "GenSigSendType" SG_ 138 AVN_NTD_SET 4;
BA_ "UserSigValidity" SG_ 138 AVN_NTD_SET 3;
BA_ "Version" SG_ 138 AVN_NTD_SET "23.02.02";
BA_ "Description" SG_ 138 HU_PopupAgreement_Push "Information for user agreement of monitor popup";
BA_ "GenSigSendType" SG_ 138 HU_PopupAgreement_Push 4;
BA_ "UserSigValidity" SG_ 138 HU_PopupAgreement_Push 1;
BA_ "Version" SG_ 138 HU_PopupAgreement_Push "23.07.02";
BA_ "Description" SG_ 138 SWRC_Sensitivity_SET "This signal is for the SWRC Optical Switch Sensitivity Setting";
BA_ "GenSigSendType" SG_ 138 SWRC_Sensitivity_SET 4;
BA_ "GenSigStartValue" SG_ 138 SWRC_Sensitivity_SET 3;
BA_ "UserSigValidity" SG_ 138 SWRC_Sensitivity_SET 3;
BA_ "Version" SG_ 138 SWRC_Sensitivity_SET "19.12.00";
BA_ "Description" SG_ 138 HU_ChgInCurrModSet "Charge current set signal";
BA_ "GenSigSendType" SG_ 138 HU_ChgInCurrModSet 4;
BA_ "UserSigValidity" SG_ 138 HU_ChgInCurrModSet 7;
BA_ "Version" SG_ 138 HU_ChgInCurrModSet "19.08.06";
BA_ "GenSigSendType" SG_ 138 HU_EV_WinterMode 4;
BA_ "GenSigStartValue" SG_ 138 HU_EV_WinterMode 3;
BA_ "UserSigValidity" SG_ 138 HU_EV_WinterMode 7;
BA_ "Version" SG_ 138 HU_EV_WinterMode "18.09.04";
BA_ "GenSigSendType" SG_ 138 HU_TgSoc_ScChg_Set 4;
BA_ "GenSigStartValue" SG_ 138 HU_TgSoc_ScChg_Set 255;
BA_ "UserSigValidity" SG_ 138 HU_TgSoc_ScChg_Set 7;
BA_ "Version" SG_ 138 HU_TgSoc_ScChg_Set "18.09.04";
BA_ "Description" SG_ 64 TCU_Crc1Val "The data area for CRC calculation is based on the data length (DLC) of the message DB.

The CRC shall be calculated over the entire data block (excluding the CRC bytes) including the user data, alive counter and Data ID

 

- CRC Polynomial (0x1021) , In";
BA_ "GenSigStartValue" SG_ 64 TCU_Crc1Val 65535;
BA_ "UserSigValidity" SG_ 64 TCU_Crc1Val 3;
BA_ "RoutingFactor" SG_ 64 TCU_Crc1Val 5;
BA_ "Version" SG_ 64 TCU_Crc1Val "18.11.08";
BA_ "Description" SG_ 64 TCU_DcmlVehSpdKphVal "The signal VS_TCU_DECIAMAL means the value which is below decimal point of the vehicle speed.

For instance, if a vehicle speed is 13.75Km/h, VS_TCU means 13Km/h and VS_TCU_DECIMAL means 0.75Km/h.



Example)   VS_TCU = 13,  VS_TCU_DECIAMAL  = 96

Vehicl";
BA_ "UserSigValidity" SG_ 64 TCU_DcmlVehSpdKphVal 3;
BA_ "RoutingFactor" SG_ 64 TCU_DcmlVehSpdKphVal 5;
BA_ "Version" SG_ 64 TCU_DcmlVehSpdKphVal "17.11.00";
BA_ "Description" SG_ 64 TCU_SprkRtrdReq "The TCU requests a spark angle retard via the signal SPK_RTD_TCU to the EMS for torque reduction during the gear engage condition.



(PH) = ((HEX) - 3FH) * 0.375 (Advance) (PH) = (3FH - (HEX)) * (-0.375) (Retard)

-15˚  ... 0˚= 17H .. 3FH (Retard)

0.";
BA_ "GenSigStartValue" SG_ 64 TCU_SprkRtrdReq 255;
BA_ "UserSigValidity" SG_ 64 TCU_SprkRtrdReq 3;
BA_ "RoutingFactor" SG_ 64 TCU_SprkRtrdReq 5;
BA_ "Version" SG_ 64 TCU_SprkRtrdReq "17.11.00";
BA_ "Description" SG_ 64 TCU_EngRpmDisSta "Flag for Engine RPM(from TCU) Display on Cluster, Only when this flag is set to 1, Cluster shall display the Engine RPM from TCU";
BA_ "UserSigValidity" SG_ 64 TCU_EngRpmDisSta 3;
BA_ "RoutingFactor" SG_ 64 TCU_EngRpmDisSta 5;
BA_ "Version" SG_ 64 TCU_EngRpmDisSta "17.11.00";
BA_ "Description" SG_ 64 TCU_GearLmpBlnkngReq "Cluster controls blinking of Gear lamp receiving the request signal from TCU.";
BA_ "UserSigValidity" SG_ 64 TCU_GearLmpBlnkngReq 3;
BA_ "RoutingFactor" SG_ 64 TCU_GearLmpBlnkngReq 5;
BA_ "Version" SG_ 64 TCU_GearLmpBlnkngReq "17.11.00";
BA_ "Description" SG_ 64 TCU_FuelCutInhbtReq "During coast down shifting, EMS may cut off fuel injection and as a result, a driver can feel bad shift feeling. In this case, to enhance shift quality, TCU needs inhibition of fuel cut off control.

This signal indicates inhibition of engine fuel cut of";
BA_ "UserSigValidity" SG_ 64 TCU_FuelCutInhbtReq 3;
BA_ "RoutingFactor" SG_ 64 TCU_FuelCutInhbtReq 5;
BA_ "Version" SG_ 64 TCU_FuelCutInhbtReq "17.11.00";
BA_ "Description" SG_ 64 TCU_IdleUpReq "When ATF(Automatic Transmission Fluid) rises in high temperauture, the TCU requests engine idle RPM up via the signal IDLE_UP_TCU to the EMS for reduction of gearshift time form Neutral to Reverse.



THIS SIGNAL IS FOR “LAMBDA ENGINE” SYSTEM ONLY.";
BA_ "UserSigValidity" SG_ 64 TCU_IdleUpReq 3;
BA_ "RoutingFactor" SG_ 64 TCU_IdleUpReq 5;
BA_ "Version" SG_ 64 TCU_IdleUpReq "17.11.00";
BA_ "Description" SG_ 64 TCU_EngRpmDis "Engine RPM from TCU (Only for the display on Cluster)";
BA_ "UserSigValidity" SG_ 64 TCU_EngRpmDis 3;
BA_ "RoutingFactor" SG_ 64 TCU_EngRpmDis 5;
BA_ "Version" SG_ 64 TCU_EngRpmDis "17.11.00";
BA_ "Description" SG_ 64 TCU_SlpVal "This signal is used to avoid busy shifting during uphill driving.

It is calculated using engine torque, turbine torque and gearbox torque so on.

It has some restrictions like the following sentences

- No slope calculation during shifting, braking, 1st";
BA_ "GenSigStartValue" SG_ 64 TCU_SlpVal 32;
BA_ "UserSigValidity" SG_ 64 TCU_SlpVal 3;
BA_ "RoutingFactor" SG_ 64 TCU_SlpVal 5;
BA_ "Version" SG_ 64 TCU_SlpVal "17.11.00";
BA_ "Description" SG_ 64 TCU_EngSpdIncReq "This signal is a target engine speed requirement start flag signal by TCU, 

which is sent to ECU. It is synchronized to the signal engine speed increasing target speed value.";
BA_ "UserSigValidity" SG_ 64 TCU_EngSpdIncReq 3;
BA_ "RoutingFactor" SG_ 64 TCU_EngSpdIncReq 5;
BA_ "Version" SG_ 64 TCU_EngSpdIncReq "17.11.00";
BA_ "Description" SG_ 64 TCU_ObdSta "The signal TCU_OBD is used to inform the OBD master (EMS-ECU) in case a OBD relevant fault is detected. According to the OBD regulations the TCU could request MIL on. If a freeze frame request by the TCU has not been acknowledged (OBD_FRF_ACK) within 2 s";
BA_ "UserSigValidity" SG_ 64 TCU_ObdSta 3;
BA_ "RoutingFactor" SG_ 64 TCU_ObdSta 5;
BA_ "Version" SG_ 64 TCU_ObdSta "19.02.07";
BA_ "Description" SG_ 64 TCU_SprtyIndxSta "Sporty index based on the driver's driving behaviour";
BA_ "UserSigValidity" SG_ 64 TCU_SprtyIndxSta 3;
BA_ "RoutingFactor" SG_ 64 TCU_SprtyIndxSta 5;
BA_ "Version" SG_ 64 TCU_SprtyIndxSta "17.11.00";
BA_ "Description" SG_ 64 TCU_AlvCnt1Val "For the first transmission request for a data element the counter shall be initialized with 0 and shall be incremented by 1 for every subsequent send request. 

When the counter reaches the maximum value(0xFF), then it shall restart with 0 for the next s";
BA_ "UserSigValidity" SG_ 64 TCU_AlvCnt1Val 3;
BA_ "RoutingFactor" SG_ 64 TCU_AlvCnt1Val 5;
BA_ "Version" SG_ 64 TCU_AlvCnt1Val "18.11.08";
BA_ "Description" SG_ 64 TCU_DrvngModDis "Driving mode display by TCU";
BA_ "UserSigValidity" SG_ 64 TCU_DrvngModDis 3;
BA_ "RoutingFactor" SG_ 64 TCU_DrvngModDis 5;
BA_ "Version" SG_ 64 TCU_DrvngModDis "17.11.00";
BA_ "Description" SG_ 64 TCU_DrvngModReq "Driving mode request with Normal, Eco, Eco+, Sport, Sport+

and Snow only TCU automode is on, otherwise, inactive";
BA_ "UserSigValidity" SG_ 64 TCU_DrvngModReq 3;
BA_ "RoutingFactor" SG_ 64 TCU_DrvngModReq 5;
BA_ "Version" SG_ 64 TCU_DrvngModReq "17.11.00";
BA_ "Description" SG_ 64 TCU_SmrtShftSta "Information of SmartShift";
BA_ "UserSigValidity" SG_ 64 TCU_SmrtShftSta 3;
BA_ "RoutingFactor" SG_ 64 TCU_SmrtShftSta 5;
BA_ "Version" SG_ 64 TCU_SmrtShftSta "17.11.00";
BA_ "Description" SG_ 64 TCU_LupTrgtEngSpdVal "This signal is a target engine speed requested by TCU, which is sent to ECU. 

It is intended for OFF-SLIP to be more successful in triggering fuel cut-off under more various driving conditions.";
BA_ "GenSigStartValue" SG_ 64 TCU_LupTrgtEngSpdVal 255;
BA_ "UserSigValidity" SG_ 64 TCU_LupTrgtEngSpdVal 3;
BA_ "RoutingFactor" SG_ 64 TCU_LupTrgtEngSpdVal 5;
BA_ "Version" SG_ 64 TCU_LupTrgtEngSpdVal "17.11.00";
BA_ "Description" SG_ 64 TCU_FrtStcShftSta "Status of fisrt static shift";
BA_ "UserSigValidity" SG_ 64 TCU_FrtStcShftSta 3;
BA_ "RoutingFactor" SG_ 64 TCU_FrtStcShftSta 5;
BA_ "Version" SG_ 64 TCU_FrtStcShftSta "17.11.00";
BA_ "Description" SG_ 64 TCU_IsgInhbtReq "TCU requests ECU to inhibit the ISG function when ISG start condition of AT is not met (oil temp is too low , AT ISG system malfunction, etc … )";
BA_ "UserSigValidity" SG_ 64 TCU_IsgInhbtReq 3;
BA_ "RoutingFactor" SG_ 64 TCU_IsgInhbtReq 5;
BA_ "Version" SG_ 64 TCU_IsgInhbtReq "17.11.00";
BA_ "Description" SG_ 64 TCU_CdaInhbtReq "TCU requests ECU to prohibit the CDA transition during gear shifting or lock-up clutch operation in the automatic transmission in order to prevent a shock on the vehicle. Without gear shifting and lock-up clutch operation, CDA transition can be performed";
BA_ "UserSigValidity" SG_ 64 TCU_CdaInhbtReq 3;
BA_ "RoutingFactor" SG_ 64 TCU_CdaInhbtReq 5;
BA_ "Version" SG_ 64 TCU_CdaInhbtReq "17.11.00";
BA_ "Description" SG_ 64 TCU_BrkOnReq "The TCU request the ESC to activate the Brake.

The ESC holds the Brake ON during the TCU’s Brake ON Request.";
BA_ "UserSigValidity" SG_ 64 TCU_BrkOnReq 3;
BA_ "RoutingFactor" SG_ 64 TCU_BrkOnReq 5;
BA_ "Version" SG_ 64 TCU_BrkOnReq "17.11.00";
BA_ "Description" SG_ 64 TCU_TqGrdntLimVal "TCU requests EMS to perform the engine torque gradient limitation control with a rate of Nm per second(Nm/sec).



Downshift : The engine torque gradient limitation for downshift will be a function of pedal and shift-time. 

Upshift : The engine torque g";
BA_ "UserSigValidity" SG_ 64 TCU_TqGrdntLimVal 3;
BA_ "RoutingFactor" SG_ 64 TCU_TqGrdntLimVal 5;
BA_ "Version" SG_ 64 TCU_TqGrdntLimVal "17.11.00";
BA_ "Description" SG_ 64 TCU_NetrlCtrlSta "This signal indicates the status of Neutral Control.";
BA_ "UserSigValidity" SG_ 64 TCU_NetrlCtrlSta 3;
BA_ "RoutingFactor" SG_ 64 TCU_NetrlCtrlSta 5;
BA_ "Version" SG_ 64 TCU_NetrlCtrlSta "17.11.00";
BA_ "Description" SG_ 64 TCU_ShftPtrnSta "It is an ID of current shift pattern which is being used by TCU.

The ID is assigned for each TCU.";
BA_ "UserSigValidity" SG_ 64 TCU_ShftPtrnSta 3;
BA_ "RoutingFactor" SG_ 64 TCU_ShftPtrnSta 5;
BA_ "Version" SG_ 64 TCU_ShftPtrnSta "17.11.00";
BA_ "Description" SG_ 64 TCU_VgisInhbtReq "TCU requests ECU to inhibit the VGIS fuction from changing its status.";
BA_ "UserSigValidity" SG_ 64 TCU_VgisInhbtReq 3;
BA_ "RoutingFactor" SG_ 64 TCU_VgisInhbtReq 5;
BA_ "Version" SG_ 64 TCU_VgisInhbtReq "17.11.00";
BA_ "Description" SG_ 64 TCU_EngTqIncReqVal "The TCU requests the engine torque increase via this signal to the EMS.



If MSB is 1, this signal is - value.

else, this signal is +value.

0~10bit is used for absolute value.";
BA_ "UserSigValidity" SG_ 64 TCU_EngTqIncReqVal 3;
BA_ "RoutingFactor" SG_ 64 TCU_EngTqIncReqVal 5;
BA_ "Version" SG_ 64 TCU_EngTqIncReqVal "20.03.05";
BA_ "Description" SG_ 64 TCU_EPBReq "This is EPB Request signal for prevent P-D Shift shock on the hill";
BA_ "UserSigValidity" SG_ 64 TCU_EPBReq 3;
BA_ "RoutingFactor" SG_ 64 TCU_EPBReq 5;
BA_ "Version" SG_ 64 TCU_EPBReq "19.03.09";
BA_ "Description" SG_ 64 IMT_EOLstate "If this signal is set, Cluster should display gear info using alphabet 'E' regardless the signal 'TCU_GearSlctDis'";
BA_ "UserSigValidity" SG_ 64 IMT_EOLstate 3;
BA_ "RoutingFactor" SG_ 64 IMT_EOLstate 5;
BA_ "Version" SG_ 64 IMT_EOLstate "19.02.06";
BA_ "Description" SG_ 64 IMT_DisCmd "This signal is used for cluster to change gear display type. 

Always Display / Not Display / Blinking";
BA_ "UserSigValidity" SG_ 64 IMT_DisCmd 3;
BA_ "RoutingFactor" SG_ 64 IMT_DisCmd 5;
BA_ "Version" SG_ 64 IMT_DisCmd "19.02.06";
BA_ "Description" SG_ 64 IMT_CltchPdlPos "Clutch Position Sensor value for 3 pedal IMT system.

This value is not supported by 2 pedal IMT system.



0% means pedal off 

99.21875% (0xFE) means pedal fully pressed

99.609375 (0xFF) means  error";
BA_ "UserSigValidity" SG_ 64 IMT_CltchPdlPos 3;
BA_ "RoutingFactor" SG_ 64 IMT_CltchPdlPos 5;
BA_ "Version" SG_ 64 IMT_CltchPdlPos "19.02.06";
BA_ "Description" SG_ 64 DCT_RegenInhbt "The regen inhibit request from TCU.

ECU is received regen inhibit flag from TCU, then ECU is limited the regen state.";
BA_ "UserSigValidity" SG_ 64 DCT_RegenInhbt 3;
BA_ "RoutingFactor" SG_ 64 DCT_RegenInhbt 5;
BA_ "Version" SG_ 64 DCT_RegenInhbt "18.08.02";
BA_ "Description" SG_ 64 DCT_EngIdleReq "Engine Idle Request from TCU";
BA_ "UserSigValidity" SG_ 64 DCT_EngIdleReq 3;
BA_ "RoutingFactor" SG_ 64 DCT_EngIdleReq 5;
BA_ "Version" SG_ 64 DCT_EngIdleReq "18.08.02";
BA_ "Description" SG_ 64 DCT_CltchState "Status of DCT clutches. This signal gives information about the frictional connection between the engine and the drive train.";
BA_ "UserSigValidity" SG_ 64 DCT_CltchState 3;
BA_ "RoutingFactor" SG_ 64 DCT_CltchState 5;
BA_ "Version" SG_ 64 DCT_CltchState "18.08.02";
BA_ "Description" SG_ 64 DCT_FuelCutReq "Fuel Cut request bit signal to let EMS perform ‘Fuel Cut torque intervention’ during shift";
BA_ "UserSigValidity" SG_ 64 DCT_FuelCutReq 3;
BA_ "RoutingFactor" SG_ 64 DCT_FuelCutReq 5;
BA_ "Version" SG_ 64 DCT_FuelCutReq "18.08.02";
BA_ "Description" SG_ 64 DCT_TqIncReq "An Identifier of a DCT TCU controller for increasing torque intervention. 

This bit is to prevent the triggering of unintended DCT TCU interventions.



In the case of a torque increase, following conditions must be fulfilled.

DCT_TqIncReq = 1 and TCU_";
BA_ "UserSigValidity" SG_ 64 DCT_TqIncReq 3;
BA_ "RoutingFactor" SG_ 64 DCT_TqIncReq 5;
BA_ "Version" SG_ 64 DCT_TqIncReq "18.08.02";
BA_ "Description" SG_ 64 DCT_CrpTqReq "During creep mode (engine in idle, brake pedal not pressed, gear engaged) clutch torque will be applied. In order to support the engine’s idle controller DCT_CrpTqReq gives the information how much clutch torque will be applied within the next 50 ms.";
BA_ "GenSigStartValue" SG_ 64 DCT_CrpTqReq 512;
BA_ "UserSigValidity" SG_ 64 DCT_CrpTqReq 3;
BA_ "RoutingFactor" SG_ 64 DCT_CrpTqReq 5;
BA_ "Version" SG_ 64 DCT_CrpTqReq "18.08.02";
BA_ "Description" SG_ 64 DCT_ShftTqReq "To ensure a torque increasing during gear shift within short time, ECU needs to build up a torque reserve determined by the pre-control torque. 

Open throttle valve (more air) and automatic ignition angle reduction (within limited range based on engine ";
BA_ "UserSigValidity" SG_ 64 DCT_ShftTqReq 3;
BA_ "RoutingFactor" SG_ 64 DCT_ShftTqReq 5;
BA_ "Version" SG_ 64 DCT_ShftTqReq "20.03.05";
BA_ "Description" SG_ 64 TCU_GearSlctDis "Position (P, R, N..), which was identified by the gear selector.

In case the gear selector is in a intermediate position, the last clear recognized position is used.

There is no specific phase relationship between the output and any other signal.";
BA_ "GenSigStartValue" SG_ 64 TCU_GearSlctDis 9;
BA_ "UserSigValidity" SG_ 64 TCU_GearSlctDis 3;
BA_ "RoutingFactor" SG_ 64 TCU_GearSlctDis 5;
BA_ "Version" SG_ 64 TCU_GearSlctDis "17.11.00";
BA_ "Description" SG_ 64 TCU_Typ "Information regarding the type of transmission - Step A/T or CVT or DCT / AMT / eClutch";
BA_ "UserSigValidity" SG_ 64 TCU_Typ 3;
BA_ "RoutingFactor" SG_ 64 TCU_Typ 5;
BA_ "Version" SG_ 64 TCU_Typ "18.12.02";
BA_ "Description" SG_ 64 TCU_TqRdctnVal "The TCU requests a torque reduction via this signal to the EMS. 



If MSB is 1, this signal is - value.

else, this signal is +value.

0~10bit is used for absolute value.";
BA_ "GenSigStartValue" SG_ 64 TCU_TqRdctnVal 2047;
BA_ "UserSigValidity" SG_ 64 TCU_TqRdctnVal 3;
BA_ "RoutingFactor" SG_ 64 TCU_TqRdctnVal 5;
BA_ "Version" SG_ 64 TCU_TqRdctnVal "20.03.05";
BA_ "Description" SG_ 64 TCU_GearStepTyp "This signal indicates number of gear steps of step type automatic transmission(A/T) or Dual Clutch Transmission(DCT). A vehicle can have A/T or DCT variant according to its option, for example 4-speed A/T or 5-speed A/T can be equipped in the same kind o";
BA_ "UserSigValidity" SG_ 64 TCU_GearStepTyp 3;
BA_ "RoutingFactor" SG_ 64 TCU_GearStepTyp 5;
BA_ "Version" SG_ 64 TCU_GearStepTyp "19.02.07";
BA_ "Description" SG_ 64 TCU_GearShftSta "SWI_GS indicates whether a gear change is being executed in the gearbox.



Note : Gear change means a gear shift at D-range and Garage shift(PRND).";
BA_ "UserSigValidity" SG_ 64 TCU_GearShftSta 3;
BA_ "RoutingFactor" SG_ 64 TCU_GearShftSta 5;
BA_ "Version" SG_ 64 TCU_GearShftSta "17.11.00";
BA_ "Description" SG_ 64 TCU_TqCnvrtrSta "Status converter clutch



There is no specific phase relationship between the output and any other signal.";
BA_ "UserSigValidity" SG_ 64 TCU_TqCnvrtrSta 3;
BA_ "RoutingFactor" SG_ 64 TCU_TqCnvrtrSta 5;
BA_ "Version" SG_ 64 TCU_TqCnvrtrSta "17.11.00";
BA_ "Description" SG_ 64 TCU_CurrGearSta "CUR_GR indicates the gear speed which is currently engaged in the gearbox.";
BA_ "UserSigValidity" SG_ 64 TCU_CurrGearSta 3;
BA_ "RoutingFactor" SG_ 64 TCU_CurrGearSta 5;
BA_ "Version" SG_ 64 TCU_CurrGearSta "17.11.00";
BA_ "Description" SG_ 64 TCU_TrgtGearSta "CF_Tcu_TarGr informs about the speed, which is currently engaged in the gearbox, or, in case of a gear change (SWI_GS), which speed is reached.



Note: Gear changes covering more than one speed are also possible.

In the P and N positions, the frictiona";
BA_ "UserSigValidity" SG_ 64 TCU_TrgtGearSta 3;
BA_ "RoutingFactor" SG_ 64 TCU_TrgtGearSta 5;
BA_ "Version" SG_ 64 TCU_TrgtGearSta "17.11.00";
BA_ "Description" SG_ 64 TCU_CluTrgtGearSta "TCH_CluTrgtGearSta informs about target gear of SS timing 

(For indicating Paddle shift or Manual mode on cluster)";
BA_ "UserSigValidity" SG_ 64 TCU_CluTrgtGearSta 3;
BA_ "RoutingFactor" SG_ 64 TCU_CluTrgtGearSta 5;
BA_ "Version" SG_ 64 TCU_CluTrgtGearSta "17.11.00";
BA_ "Description" SG_ 64 TCH_EngTrgtGearSta "TCH_EngTrgtGearSta informs about target gear of SS timing 

(For indicating Paddle shift or Manual mode on cluster)";
BA_ "UserSigValidity" SG_ 64 TCH_EngTrgtGearSta 3;
BA_ "RoutingFactor" SG_ 64 TCH_EngTrgtGearSta 5;
BA_ "Version" SG_ 64 TCH_EngTrgtGearSta "17.11.00";
BA_ "Description" SG_ 64 TCU_EngTqLimVal "The TCU requests a engine torque limit(ETL) from the EMS. 

There is no time limitation of the intervention.

TCU requests engine torque limit below the TCU requesting torque.

The engine torque request signal means the absolute torque limitation.

TCU s";
BA_ "GenSigStartValue" SG_ 64 TCU_EngTqLimVal 2047;
BA_ "UserSigValidity" SG_ 64 TCU_EngTqLimVal 3;
BA_ "RoutingFactor" SG_ 64 TCU_EngTqLimVal 5;
BA_ "Version" SG_ 64 TCU_EngTqLimVal "20.03.05";
BA_ "Description" SG_ 64 TCU_CluTrgtGearConfg "This signal indicates the signal source configuration of target gear for CLU";
BA_ "UserSigValidity" SG_ 64 TCU_CluTrgtGearConfg 3;
BA_ "RoutingFactor" SG_ 64 TCU_CluTrgtGearConfg 5;
BA_ "Version" SG_ 64 TCU_CluTrgtGearConfg "18.08.01";
BA_ "Description" SG_ 64 TCU_VehSpdKphVal "The vehicle speed calculated by TCU is transferred. 

If a vehicle has no vehicle speed sensor, no wheel speed sensor and no ABS(TCS/ESC) then it is impossible for an EMS to calculate veficle speed. In this case a TCU should calculate vehicle speed and s";
BA_ "UserSigValidity" SG_ 64 TCU_VehSpdKphVal 3;
BA_ "RoutingFactor" SG_ 64 TCU_VehSpdKphVal 5;
BA_ "Version" SG_ 64 TCU_VehSpdKphVal "17.11.00";
BA_REL_ "GenSigTimeoutTime" BU_SG_REL_ CGW_CCU SG_ 956 BLTN_CAM_Set_EV_BfrTime 1500;
BA_REL_ "GenSigTimeoutTime" BU_SG_REL_ CGW_CCU SG_ 956 BLTN_CAM_Set_EV_AftTime 1500;
BA_REL_ "GenSigTimeoutTime" BU_SG_REL_ CGW_CCU SG_ 956 BLTN_CAM_Set_Drv_TML_Int 1500;
BA_REL_ "GenSigTimeoutTime" BU_SG_REL_ CGW_CCU SG_ 956 BLTN_CAM_SenSet_DEV 1500;
BA_REL_ "GenSigTimeoutTime" BU_SG_REL_ CGW_CCU SG_ 956 BLTN_CAM_SenSet_PEV 1500;
BA_REL_ "GenSigTimeoutTime" BU_SG_REL_ CGW_CCU SG_ 956 BLTN_CAM_Set_FR_Ver_Pos 1500;
BA_REL_ "GenSigTimeoutTime" BU_SG_REL_ CGW_CCU SG_ 956 BLTN_CAM_Set_RR_Ver_Pos 1500;
BA_REL_ "GenSigTimeoutTime" BU_SG_REL_ CGW_CCU SG_ 956 BLTN_CAM_Set_PEV_AppNoti 1500;
BA_REL_ "GenSigTimeoutTime" BU_SG_REL_ CGW_CCU SG_ 956 BLTN_CAM_Set_WiFi_AutoOn 1500;
BA_REL_ "GenSigTimeoutTime" BU_SG_REL_ CGW_CCU SG_ 956 BLTN_CAM_StrgPropSet 1500;
BA_REL_ "GenSigTimeoutTime" BU_SG_REL_ CGW_CCU SG_ 956 BLTN_CAM_File_DEL_CPY_Op_State 1500;
BA_REL_ "GenSigTimeoutTime" BU_SG_REL_ CGW_CCU SG_ 956 BLTN_CAM_File_DEL_CPY_NumTot 1500;
BA_REL_ "GenSigTimeoutTime" BU_SG_REL_ CGW_CCU SG_ 956 BLTN_CAM_File_DEL_CPYed_Num 1500;
BA_REL_ "GenSigTimeoutTime" BU_SG_REL_ CGW_CCU SG_ 956 BLTN_CAM_Set_PMD 1500;
BA_REL_ "GenSigTimeoutTime" BU_SG_REL_ CGW_CCU SG_ 956 BLTN_CAM_Set_PMDEV 1500;
BA_REL_ "GenSigTimeoutTime" BU_SG_REL_ CGW_CCU SG_ 956 BLTN_CAM_RanSet_PMDR 1500;
BA_REL_ "GenSigTimeoutTime" BU_SG_REL_ CGW_CCU SG_ 956 BLTN_CAM_MaxRanSet_PMDR 1500;
BA_REL_ "GenSigTimeoutTime" BU_SG_REL_ CGW_CCU SG_ 956 BLTN_CAM_Set_PMDTime 1500;
BA_REL_ "GenSigTimeoutTime" BU_SG_REL_ CGW_CCU SG_ 956 BLTN_CAM_RecSet_OWD 1500;
BA_REL_ "GenSigTimeoutTime" BU_SG_REL_ CGW_CCU SG_ 956 BLTN_CAM_RecSet_DEV 1500;
BA_REL_ "GenSigTimeoutTime" BU_SG_REL_ CGW_CCU SG_ 956 BLTN_CAM_RecSet_OWP 1500;
BA_REL_ "GenSigTimeoutTime" BU_SG_REL_ CGW_CCU SG_ 956 BLTN_CAM_RecSet_PEV 1500;
BA_REL_ "GenSigTimeoutTime" BU_SG_REL_ CGW_CCU SG_ 956 BLTN_CAM_AudRec_Set 1500;
BA_REL_ "GenSigTimeoutTime" BU_SG_REL_ CGW_CCU SG_ 956 BLTN_CAM_Set_Tim_Stm 1500;
BA_REL_ "GenSigTimeoutTime" BU_SG_REL_ CGW_CCU SG_ 956 BLTN_CAM_Set_Spd_Stm 1500;
BA_REL_ "GenSigTimeoutTime" BU_SG_REL_ CGW_CCU SG_ 956 BLTN_CAM_Set_Locatn_Stm 1500;
BA_REL_ "GenSigTimeoutTime" BU_SG_REL_ CGW_CCU SG_ 956 BLTN_CAM_Set_TrnSig_Stm 1500;
BA_REL_ "GenSigTimeoutTime" BU_SG_REL_ CGW_CCU SG_ 956 BLTN_CAM_Set_AclBrk_Stm 1500;
BA_REL_ "GenSigTimeoutTime" BU_SG_REL_ CGW_CCU SG_ 956 BLTN_CAM_Set_GearPos_Stm 1500;
BA_REL_ "GenSigTimeoutTime" BU_SG_REL_ CGW_CCU SG_ 956 BLTN_CAM_Set_EVSen_Stm 1500;
BA_REL_ "GenSigTimeoutTime" BU_SG_REL_ CGW_CCU SG_ 956 BLTN_CAM_Set_StrAngl_Stm 1500;
BA_REL_ "GenSigTimeoutTime" BU_SG_REL_ CGW_CCU SG_ 956 BLTN_CAM_Set_EV_RecMaxTime 1500;
BA_REL_ "GenSigTimeoutTime" BU_SG_REL_ CGW_CCU SG_ 956 BLTN_CAM_Set_PrkTime 1500;
BA_REL_ "GenSigTimeoutTime" BU_SG_REL_ ARS_FD SG_ 274 CF_AVN_CluUSMReset 0;
BA_REL_ "GenSigTimeoutTime" BU_SG_REL_ ATS_FD SG_ 274 CF_AVN_CluUSMReset 0;
BA_REL_ "GenSigTimeoutTime" BU_SG_REL_ BLTN_CAM_FD SG_ 274 CF_AVN_CluUSMReset 0;
BA_REL_ "GenSigTimeoutTime" BU_SG_REL_ GW_PSU_3RD_FD SG_ 274 CF_AVN_CluUSMReset 0;
BA_REL_ "GenSigTimeoutTime" BU_SG_REL_ GW_PSU_AST_FD SG_ 274 CF_AVN_CluUSMReset 0;
BA_REL_ "GenSigTimeoutTime" BU_SG_REL_ GW_PSU_DRV_FD SG_ 274 CF_AVN_CluUSMReset 0;
BA_REL_ "GenSigTimeoutTime" BU_SG_REL_ GW_PSU_RL_FD SG_ 274 CF_AVN_CluUSMReset 0;
BA_REL_ "GenSigTimeoutTime" BU_SG_REL_ GW_PSU_RR_FD SG_ 274 CF_AVN_CluUSMReset 0;
BA_REL_ "GenSigTimeoutTime" BU_SG_REL_ GW_SAU_DRV_FD SG_ 274 CF_AVN_CluUSMReset 0;
BA_REL_ "GenSigTimeoutTime" BU_SG_REL_ RCM_FD SG_ 274 CF_AVN_CluUSMReset 0;
BA_REL_ "GenSigTimeoutTime" BU_SG_REL_ RWPC_FD SG_ 274 CF_AVN_CluUSMReset 0;
BA_REL_ "GenSigTimeoutTime" BU_SG_REL_ SGU_FD SG_ 274 CF_AVN_CluUSMReset 0;
BA_REL_ "GenSigTimeoutTime" BU_SG_REL_ SHVU_FRNT_FD SG_ 274 CF_AVN_CluUSMReset 0;
BA_REL_ "GenSigTimeoutTime" BU_SG_REL_ SHVU_REAR_FD SG_ 274 CF_AVN_CluUSMReset 0;
BA_REL_ "GenSigTimeoutTime" BU_SG_REL_ SHVU_RL_FD SG_ 274 CF_AVN_CluUSMReset 0;
BA_REL_ "GenSigTimeoutTime" BU_SG_REL_ SHVU_RR_FD SG_ 274 CF_AVN_CluUSMReset 0;
BA_REL_ "GenSigTimeoutTime" BU_SG_REL_ WPC2_FD SG_ 274 CF_AVN_CluUSMReset 0;
BA_REL_ "GenSigTimeoutTime" BU_SG_REL_ WPC_FD SG_ 274 CF_AVN_CluUSMReset 0;
BA_REL_ "GenSigTimeoutTime" BU_SG_REL_ GW_PSU_DRV_FD SG_ 274 CF_AVN_BodySpprtSet 0;
BA_REL_ "GenSigTimeoutTime" BU_SG_REL_ GW_SAU_DRV_FD SG_ 274 CF_AVN_BodySpprtSet 0;
BA_REL_ "GenSigTimeoutTime" BU_SG_REL_ GW_SAU_DRV_FD SG_ 274 CF_AVN_AirSptTimeNValueSet 0;
BA_REL_ "GenSigTimeoutTime" BU_SG_REL_ GW_SAU_DRV_FD SG_ 274 CF_AVN_AirSptStrNValue 0;
BA_REL_ "GenSigTimeoutTime" BU_SG_REL_ GW_PSU_DRV_FD SG_ 274 CF_AVN_SeatDrvModNValueSet 0;
BA_REL_ "GenSigTimeoutTime" BU_SG_REL_ GW_SAU_DRV_FD SG_ 274 CF_AVN_SeatDrvModNValueSet 0;
BA_REL_ "GenSigTimeoutTime" BU_SG_REL_ ATS_FD SG_ 274 C_MoodLpFadeNValue 0;
BA_REL_ "GenSigTimeoutTime" BU_SG_REL_ BLTN_CAM_FD SG_ 686 HU_VehiclePwr 1500;
BA_REL_ "GenSigTimeoutTime" BU_SG_REL_ SGU_FD SG_ 686 HU_VehiclePwr 1500;
BA_REL_ "GenSigTimeoutTime" BU_SG_REL_ BLTN_CAM_FD SG_ 686 HU_PwrState 1500;
BA_REL_ "GenSigTimeoutTime" BU_SG_REL_ CGW_CCU SG_ 957 BLTN_CAM_Prk_Oprable_Time 1500;
BA_REL_ "GenSigTimeoutTime" BU_SG_REL_ CGW_CCU SG_ 957 BLTN_CAM_Prk_Oprable_Time_Max 1500;
BA_REL_ "GenSigTimeoutTime" BU_SG_REL_ CGW_CCU SG_ 957 BLTN_CAM_AuxBat_Conn_State 1500;
BA_REL_ "GenSigTimeoutTime" BU_SG_REL_ CGW_CCU SG_ 957 BLTN_CAM_AuxBat_CapPer 1500;
BA_REL_ "GenSigTimeoutTime" BU_SG_REL_ CGW_CCU SG_ 957 BLTN_CAM_SWVerMajor 1500;
BA_REL_ "GenSigTimeoutTime" BU_SG_REL_ CGW_CCU SG_ 957 BLTN_CAM_SWVerMinor1 1500;
BA_REL_ "GenSigTimeoutTime" BU_SG_REL_ CGW_CCU SG_ 957 BLTN_CAM_SWVerMinor2 1500;
BA_REL_ "GenSigTimeoutTime" BU_SG_REL_ CGW_CCU SG_ 957 BLTN_CAM_SWVerMinor3 1500;
BA_REL_ "GenSigTimeoutTime" BU_SG_REL_ CGW_CCU SG_ 957 BLTN_CAM_SD_Card_Manufacturer 1500;
BA_REL_ "GenSigTimeoutTime" BU_SG_REL_ CGW_CCU SG_ 957 BLTN_CAM_SD_Card_Cap_Class 1500;
BA_REL_ "GenSigTimeoutTime" BU_SG_REL_ CGW_CCU SG_ 957 BLTN_CAM_PMD_Oprable_Time 1500;
BA_REL_ "GenSigTimeoutTime" BU_SG_REL_ CGW_CCU SG_ 957 BLTN_CAM_PMD_Oprable_Time_Max 1500;
BA_REL_ "GenSigTimeoutTime" BU_SG_REL_ CGW_CCU SG_ 957 BLTN_CAM_RecSta_PMD 1500;
BA_REL_ "GenSigTimeoutTime" BU_SG_REL_ CGW_CCU SG_ 957 BLTN_CAM_State 1500;
BA_REL_ "GenSigTimeoutTime" BU_SG_REL_ CGW_CCU SG_ 957 BLTN_CAM_SD_Card_State 1500;
BA_REL_ "GenSigTimeoutTime" BU_SG_REL_ CGW_CCU SG_ 957 BLTN_CAM_RecSta_OWD 1500;
BA_REL_ "GenSigTimeoutTime" BU_SG_REL_ CGW_CCU SG_ 957 BLTN_CAM_RecSta_DEV 1500;
BA_REL_ "GenSigTimeoutTime" BU_SG_REL_ CGW_CCU SG_ 957 BLTN_CAM_RecSta_MAR 1500;
BA_REL_ "GenSigTimeoutTime" BU_SG_REL_ CGW_CCU SG_ 957 BLTN_CAM_RecSta_TML 1500;
BA_REL_ "GenSigTimeoutTime" BU_SG_REL_ CGW_CCU SG_ 957 BLTN_CAM_RecSta_OWP 1500;
BA_REL_ "GenSigTimeoutTime" BU_SG_REL_ CGW_CCU SG_ 957 BLTN_CAM_RecSta_PEV 1500;
BA_REL_ "GenSigTimeoutTime" BU_SG_REL_ CGW_CCU SG_ 957 BLTN_CAM_Prk_EV_Cnt 1500;
BA_REL_ "GenSigTimeoutTime" BU_SG_REL_ CGW_CCU SG_ 957 BLTN_CAM_Prk_Oped_Time 1500;
BA_REL_ "GenSigTimeoutTime" BU_SG_REL_ BLTN_CAM_FD SG_ 685 HU_BLTN_CAM_UI_Mode 1500;
BA_REL_ "GenSigTimeoutTime" BU_SG_REL_ BLTN_CAM_FD SG_ 685 HU_BLTN_CAM_Display 1500;
BA_REL_ "GenSigTimeoutTime" BU_SG_REL_ BLTN_CAM_FD SG_ 138 C_PreCrankReq 0;
BA_REL_ "GenSigTimeoutTime" BU_SG_REL_ GW_PSU_AST_FD SG_ 138 C_TeleAstSeatOpCmdIBOX 0;
BA_REL_ "GenSigTimeoutTime" BU_SG_REL_ SHVU_FRNT_FD SG_ 138 C_TeleAstSeatOpCmdIBOX 0;
BA_REL_ "GenSigTimeoutTime" BU_SG_REL_ GW_PSU_AST_FD SG_ 138 C_TeleDrvSeatOpCmdIBOX 0;
BA_REL_ "GenSigTimeoutTime" BU_SG_REL_ GW_PSU_DRV_FD SG_ 138 C_TeleDrvSeatOpCmdIBOX 0;
BA_REL_ "GenSigTimeoutTime" BU_SG_REL_ SHVU_FRNT_FD SG_ 138 C_TeleDrvSeatOpCmdIBOX 0;
BA_REL_ "GenSigTimeoutTime" BU_SG_REL_ ATS_FD SG_ 138 C_TeleRRSeatOpCmdIBOX 0;
BA_REL_ "GenSigTimeoutTime" BU_SG_REL_ GW_PSU_RL_FD SG_ 138 C_TeleRRSeatOpCmdIBOX 0;
BA_REL_ "GenSigTimeoutTime" BU_SG_REL_ GW_PSU_RR_FD SG_ 138 C_TeleRRSeatOpCmdIBOX 0;
BA_REL_ "GenSigTimeoutTime" BU_SG_REL_ SHVU_FRNT_FD SG_ 138 C_TeleRRSeatOpCmdIBOX 0;
BA_REL_ "GenSigTimeoutTime" BU_SG_REL_ SHVU_REAR_FD SG_ 138 C_TeleRRSeatOpCmdIBOX 0;
BA_REL_ "GenSigTimeoutTime" BU_SG_REL_ SHVU_RR_FD SG_ 138 C_TeleRRSeatOpCmdIBOX 0;
BA_REL_ "GenSigTimeoutTime" BU_SG_REL_ ATS_FD SG_ 138 C_TeleRLSeatOpCmdIBOX 0;
BA_REL_ "GenSigTimeoutTime" BU_SG_REL_ GW_PSU_RL_FD SG_ 138 C_TeleRLSeatOpCmdIBOX 0;
BA_REL_ "GenSigTimeoutTime" BU_SG_REL_ GW_PSU_RR_FD SG_ 138 C_TeleRLSeatOpCmdIBOX 0;
BA_REL_ "GenSigTimeoutTime" BU_SG_REL_ SHVU_FRNT_FD SG_ 138 C_TeleRLSeatOpCmdIBOX 0;
BA_REL_ "GenSigTimeoutTime" BU_SG_REL_ SHVU_REAR_FD SG_ 138 C_TeleRLSeatOpCmdIBOX 0;
BA_REL_ "GenSigTimeoutTime" BU_SG_REL_ SHVU_RL_FD SG_ 138 C_TeleRLSeatOpCmdIBOX 0;
VAL_ 956 BLTN_CAM_FD_Crc2Val 0 "0x0x0~0xFFFF:CRCValue" 65535 "0x0x0~0xFFFF:CRCValue" ;
VAL_ 956 BLTN_CAM_Set_EV_BfrTime 0 "10~20 sec" 1 "10~20 sec" 2 "10~20 sec" 3 "10~20 sec" 4 "10~20 sec" 5 "10~20 sec" 6 "10~20 sec" 7 "10~20 sec" 8 "10~20 sec" 9 "10~20 sec" 10 "10~20 sec" 11 "Reserved" 12 "Reserved" 13 "Reserved" 14 "Reserved" 15 "Reserved" 16 "Reserved" 17 "Reserved" 18 "Reserved" 19 "Reserved" 20 "Reserved" 21 "Reserved" 22 "Reserved" 23 "Reserved" 24 "Reserved" 25 "Reserved" 26 "Reserved" 27 "Reserved" 28 "Reserved" 29 "Reserved" 30 "Reserved" 31 "Invalid" ;
VAL_ 956 BLTN_CAM_Set_EV_AftTime 0 "10~20 sec" 1 "10~20 sec" 2 "10~20 sec" 3 "10~20 sec" 4 "10~20 sec" 5 "10~20 sec" 6 "10~20 sec" 7 "10~20 sec" 8 "10~20 sec" 9 "10~20 sec" 10 "10~20 sec" 11 "Reserved" 12 "Reserved" 13 "Reserved" 14 "Reserved" 15 "Reserved" 16 "Reserved" 17 "Reserved" 18 "Reserved" 19 "Reserved" 20 "Reserved" 21 "Reserved" 22 "Reserved" 23 "Reserved" 24 "Reserved" 25 "Reserved" 26 "Reserved" 27 "Reserved" 28 "Reserved" 29 "Reserved" 30 "Reserved" 31 "Invalid" ;
VAL_ 956 BLTN_CAM_Set_Drv_TML_Int 0 "Default" 1 "1~ 10 sec" 2 "1~ 10 sec" 3 "1~ 10 sec" 4 "1~ 10 sec" 5 "1~ 10 sec" 6 "1~ 10 sec" 7 "1~ 10 sec" 8 "1~ 10 sec" 9 "1~ 10 sec" 10 "1~ 10 sec" 11 "Reserved" 12 "Reserved" 13 "Reserved" 14 "Reserved" 15 "Invalid" ;
VAL_ 956 BLTN_CAM_SenSet_DEV 0 "Default" 1 "Level 1" 2 "Level 2" 3 "Level 3" 4 "Level 4" 5 "Level 5" 6 "Reserved" 7 "Reserved" 8 "Reserved" 9 "Reserved" 10 "Reserved" 11 "Reserved" 12 "Reserved" 13 "Reserved" 14 "Reserved" 15 "Invalid" ;
VAL_ 956 BLTN_CAM_SenSet_PEV 0 "Default" 1 "Level 1" 2 "Level 2" 3 "Level 3" 4 "Level 4" 5 "Level 5" 6 "Reserved" 7 "Reserved" 8 "Reserved" 9 "Reserved" 10 "Reserved" 11 "Reserved" 12 "Reserved" 13 "Reserved" 14 "Reserved" 15 "Invalid" ;
VAL_ 956 BLTN_CAM_Set_FR_Ver_Pos 0 "Mid" 1 "Upper Level (1 ~ 10)" 2 "Upper Level (1 ~ 10)" 3 "Upper Level (1 ~ 10)" 4 "Upper Level (1 ~ 10)" 5 "Upper Level (1 ~ 10)" 6 "Upper Level (1 ~ 10)" 7 "Upper Level (1 ~ 10)" 8 "Upper Level (1 ~ 10)" 9 "Upper Level (1 ~ 10)" 10 "Upper Level (1 ~ 10)" 11 "Reserved" 12 "Reserved" 13 "Reserved" 14 "Reserved" 15 "Reserved" 16 "Reserved" 17 "Lower Level (-1 ~ -10)" 18 "Lower Level (-1 ~ -10)" 19 "Lower Level (-1 ~ -10)" 20 "Lower Level (-1 ~ -10)" 21 "Lower Level (-1 ~ -10)" 22 "Lower Level (-1 ~ -10)" 23 "Lower Level (-1 ~ -10)" 24 "Lower Level (-1 ~ -10)" 25 "Lower Level (-1 ~ -10)" 26 "Lower Level (-1 ~ -10)" 27 "Reserved" 28 "Reserved" 29 "Reserved" 30 "Reserved" 31 "Invalid" ;
VAL_ 956 BLTN_CAM_Set_RR_Ver_Pos 0 "Mid" 1 "Upper Level (1 ~ 10)" 2 "Upper Level (1 ~ 10)" 3 "Upper Level (1 ~ 10)" 4 "Upper Level (1 ~ 10)" 5 "Upper Level (1 ~ 10)" 6 "Upper Level (1 ~ 10)" 7 "Upper Level (1 ~ 10)" 8 "Upper Level (1 ~ 10)" 9 "Upper Level (1 ~ 10)" 10 "Upper Level (1 ~ 10)" 11 "Reserved" 12 "Reserved" 13 "Reserved" 14 "Reserved" 15 "Reserved" 16 "Reserved" 17 "Lower Level (-1 ~ -10)" 18 "Lower Level (-1 ~ -10)" 19 "Lower Level (-1 ~ -10)" 20 "Lower Level (-1 ~ -10)" 21 "Lower Level (-1 ~ -10)" 22 "Lower Level (-1 ~ -10)" 23 "Lower Level (-1 ~ -10)" 24 "Lower Level (-1 ~ -10)" 25 "Lower Level (-1 ~ -10)" 26 "Lower Level (-1 ~ -10)" 27 "Reserved" 28 "Reserved" 29 "Reserved" 30 "Reserved" 31 "Invalid" ;
VAL_ 956 BLTN_CAM_Set_PEV_AppNoti 0 "Default" 1 "Off" 2 "On" 3 "Invalid" ;
VAL_ 956 BLTN_CAM_Set_WiFi_AutoOn 0 "Default" 1 "Off" 2 "On" 3 "Invalid" ;
VAL_ 956 BLTN_CAM_StrgPropSet 0 "Normal" 1 "On While Recordings" 2 "On While Parked" 3 "Driving Events" 4 "Parked Events" 5 "Reserved" 6 "Reserved" 7 "Reserved" 8 "Reserved" 9 "Reserved" 10 "Reserved" 11 "Reserved" 12 "Reserved" 13 "Reserved" 14 "Reserved" 15 "Invalid" ;
VAL_ 956 BLTN_CAM_File_DEL_CPY_Op_State 0 "Default" 1 "On Deleting" 2 "On Copying" 3 "operation completed" 4 "pausing the operation" 5 "operation canceled" 6 "Reserved" 7 "Reserved" 8 "Reserved" 9 "Reserved" 10 "Delete Error, No file(s)" 11 "Copy Error, No file(s)" 12 "Copy Error, Not enough target stroage space." 13 "The space not existed(not mounted)" 14 "the commend file is wrong." 15 "Invalid" ;
VAL_ 956 BLTN_CAM_File_DEL_CPY_NumTot 0 "Default" 1 "0x001~0xFFFB:Number of files" 65531 "0x001~0xFFFB:Number of files" 65532 "not operated" 65533 "The space not existed(not mounted)" 65534 "Not enough space" 65535 "Invalid" ;
VAL_ 956 BLTN_CAM_FD_AlvCnt2Val 0 "0x0x0~0xFF:AlvCntValue" 255 "0x0x0~0xFF:AlvCntValue" ;
VAL_ 956 BLTN_CAM_File_DEL_CPYed_Num 0 "Default" 1 "0x001~0xFFFB:Number of files" 65531 "0x001~0xFFFB:Number of files" 65532 "not operated" 65533 "The space not existed(not mounted)" 65534 "Not enough space" 65535 "Invalid" ;
VAL_ 956 BLTN_CAM_Set_PMD 0 "Default" 1 "Off" 2 "On" 3 "Invalid" ;
VAL_ 956 BLTN_CAM_Set_PMDEV 0 "Default" 1 "Off" 2 "On" 3 "Invalid" ;
VAL_ 956 BLTN_CAM_RanSet_PMDR 0 "Default" 1 "Level 1" 2 "Level 2" 3 "Level 3" 4 "Level 4" 5 "Level 5" 6 "RESERVED" 7 "RESERVED" 8 "RESERVED" 9 "RESERVED" 10 "RESERVED" 11 "RESERVED" 12 "RESERVED" 13 "RESERVED" 14 "RESERVED" 15 "Invalid" ;
VAL_ 956 BLTN_CAM_MaxRanSet_PMDR 0 "Default" 1 "RESERVED" 2 "Level 1~2" 3 "Level 1~3" 4 "Level 1~4" 5 "Level 1~5" 6 "RESERVED" 7 "RESERVED" 8 "RESERVED" 9 "RESERVED" 10 "RESERVED" 11 "RESERVED" 12 "RESERVED" 13 "RESERVED" 14 "RESERVED" 15 "Invalid" ;
VAL_ 956 BLTN_CAM_Set_PMDTime 0 "Default" 1 "0x1~0xFB:1 ~ 251 hr" 251 "0x1~0xFB:1 ~ 251 hr" 252 "RESERVED" 253 "RESERVED" 254 "Not Supported" 255 "Invalid" ;
VAL_ 956 BLTN_CAM_RecSet_OWD 0 "Default" 1 "Off" 2 "On" 3 "Invalid" ;
VAL_ 956 BLTN_CAM_RecSet_DEV 0 "Default" 1 "Off" 2 "On" 3 "Invalid" ;
VAL_ 956 BLTN_CAM_RecSet_OWP 0 "Default" 1 "Off" 2 "On" 3 "Invalid" ;
VAL_ 956 BLTN_CAM_RecSet_PEV 0 "Default" 1 "Off" 2 "On" 3 "Invalid" ;
VAL_ 956 BLTN_CAM_AudRec_Set 0 "Default" 1 "Off" 2 "On" 3 "Invalid" ;
VAL_ 956 BLTN_CAM_Set_Tim_Stm 0 "Default" 1 "Off" 2 "On" 3 "Invalid" ;
VAL_ 956 BLTN_CAM_Set_Spd_Stm 0 "Default" 1 "Off" 2 "On" 3 "Invalid" ;
VAL_ 956 BLTN_CAM_Set_Locatn_Stm 0 "Default" 1 "Off" 2 "On" 3 "Invalid" ;
VAL_ 956 BLTN_CAM_Set_TrnSig_Stm 0 "Default" 1 "Off" 2 "On" 3 "Invalid" ;
VAL_ 956 BLTN_CAM_Set_AclBrk_Stm 0 "Default" 1 "Off" 2 "On" 3 "Invalid" ;
VAL_ 956 BLTN_CAM_Set_GearPos_Stm 0 "Default" 1 "Off" 2 "On" 3 "Invalid" ;
VAL_ 956 BLTN_CAM_Set_EVSen_Stm 0 "Default" 1 "Off" 2 "On" 3 "Invalid" ;
VAL_ 956 BLTN_CAM_Set_StrAngl_Stm 0 "Default" 1 "Off" 2 "On" 3 "Invalid" ;
VAL_ 956 BLTN_CAM_Set_EV_RecMaxTime 0 "Default" 1 "Off" 2 "On" 3 "Default" ;
VAL_ 956 BLTN_CAM_Set_PrkTime 0 "Default" 1 "0x01~0xFB: 1~ 251 hr" 251 "0x01~0xFB: 1~ 251 hr" 252 "RESERVED" 253 "RESERVED" 254 "Not Supported" 255 "Invalid" ;
VAL_ 274 HU_USM_Crc2Val 0 "0x0x0~0xFFFF:CRCValue" 65535 "0x0x0~0xFFFF:CRCValue" ;
VAL_ 274 CF_AVN_CluRheostatLvl 0 "Reserved" 1 "Step 1" 2 "Step 2" 3 "Step 3" 4 "Step 4" 5 "Step 5" 6 "Step 6" 7 "Step 7" 8 "Step 8" 9 "Step 9" 10 "Step 10" 11 "Step 11" 12 "Step 12" 13 "Step 13" 14 "Step 14" 15 "Step 15" 16 "Step 16" 17 "Step 17" 18 "Step 18" 19 "Step 19" 20 "Step 20(Reset Value)" 21 "Step 21(Detent)" 22 "Reserved" 23 "Reserved" 24 "Reserved" 25 "Reserved" 26 "Reserved" 27 "Reserved" 28 "Reserved" 29 "Reserved" 30 "Reserved" 31 "Invalid" ;
VAL_ 274 CF_AVN_EVReset 0 "Default" 1 "USM Reset" 2 "Reserved" 3 "Invalid" ;
VAL_ 274 CF_AVN_UnitReset 0 "Default" 1 "Unit Reset" 2 "Reserved" 3 "Invalid" ;
VAL_ 274 CF_AVN_IcyRoadWarn 0 "Default" 1 "Off" 2 "On" 3 "Invalid" ;
VAL_ 274 CF_AVN_CluServiceReminderReset 0 "Default" 1 "Service Reminder Reset" 2 "Reserved" 3 "Invalid" ;
VAL_ 274 CF_AVN_CluUSMReset 0 "Default" 1 "USM Reset" 2 "RESERVED" 3 "Invalid" ;
VAL_ 274 C_HCIMSWeightNValueSet 0 "Default" 1 "Under 49.4kg" 2 "49.5~59.4kg" 3 "59.5~69.4kg" 4 "69.5~79.4kg" 5 "79.5~89.4kg" 6 "89.5~99.4kg" 7 "99.5~109.4kg" 8 "109.5~119.4kg" 9 "More than 119.5kg" 10 "Reserved" 11 "Reserved" 12 "Reserved" 13 "Reserved" 14 "Reserved" 15 "Invalid" ;
VAL_ 274 C_HCIMSHeightNvalueSet 0 "Default" 1 "Less than 147.5cm" 2 "147.5~152.4cm" 3 "152.5~157.4cm" 4 "157.5~162.4cm" 5 "162.5~167.4cm" 6 "167.5~172.4cm" 7 "172.5~177.4cm" 8 "177.5~182.4cm" 9 "182.5~187.4cm" 10 "187.5~192.4cm" 11 "192.5~197.4cm" 12 "more than 197.5cm" 13 "Reserved" 14 "Reserved" 15 "Invalid" ;
VAL_ 274 CF_AVN_HCIMSButtonCommand 0 "Default" 1 "Health Care IMS Exit" 2 "Detail View" 3 "Move to recommend position" 4 "Current position Analysis" 5 "Move to setting page" 6 "Save view" 7 "IMS1 saved" 8 "IMS2 saved" 9 "Summary view" 10 "Smart IMS On" 11 "Reserved" 12 "Reserved" 13 "Reserved" 14 "Reserved" 15 "Invalid" ;
VAL_ 274 C_HCIMSSitHeightNValueSet 0 "Default" 1 "Tall" 2 "Middle" 3 "Short" 4 "Reserved" 5 "Reserved" 6 "Reserved" 7 "Reserved" 8 "Reserved" 9 "Reserved" 10 "Reserved" 11 "Reserved" 12 "Reserved" 13 "Reserved" 14 "Reserved" 15 "Invalid" ;
VAL_ 274 CF_AVN_BodySpprtSet 0 "Default" 1 "Off" 2 "On" 3 "Invalid" ;
VAL_ 274 HU_USM_AlvCnt2Val 0 "0x0x0~0xFF:AlvCntValue" 255 "0x0x0~0xFF:AlvCntValue" ;
VAL_ 274 CF_AVN_AirSptTimeNValueSet 0 "Default" 1 "Short" 2 "Normal" 3 "Long" 4 "Reserved" 5 "Reserved" 6 "Reserved" 7 "Invalid" ;
VAL_ 274 CF_AVN_AirSptStrNValue 0 "Default" 1 "Normal" 2 "Intense" 3 "Invalid" ;
VAL_ 274 CF_AVN_SeatDrvModNValueSet 0 "Default" 1 "Off" 2 "On" 3 "Invalid" ;
VAL_ 274 C_SmrtSldngDrNValueSet 0 "Default" 1 "Off" 2 "On" 3 "Reserved" 4 "Reserved" 5 "Reserved" 6 "Reserved" 7 "Invalid" ;
VAL_ 274 CF_AVN_TurboPressureUnit 0 "Default" 1 "Psi" 2 "kPa" 3 "bar" 4 "Reserved" 5 "Reserved" 6 "Reserved" 7 "Invalid" ;
VAL_ 274 CF_AVN_CluTorqueUnit 0 "Default" 1 "Nm" 2 "lb_ft" 3 "Invalid" ;
VAL_ 274 CF_AVN_MoodLpRedNValueSet 0 "0x0x000~0x0FF:Red Color 0~255 (User Selection)" 255 "0x0x000~0x0FF:Red Color 0~255 (User Selection)" 256 "0x100~0x1FF:Red Color 0~255 (Expert Recommendation)" 511 "0x100~0x1FF:Red Color 0~255 (Expert Recommendation)" 512 "Default" 1023 "Invalid" ;
VAL_ 274 CF_AVN_MoodLpGreenNValueSet 0 "0x0x000~0x0FF:Green Color 0~255 (User Selection)" 255 "0x0x000~0x0FF:Green Color 0~255 (User Selection)" 256 "0x100~0x1FF:Green Color 0~255 (Expert Recommendation)" 511 "0x100~0x1FF:Green Color 0~255 (Expert Recommendation)" 512 "Default" 1023 "Invalid" ;
VAL_ 274 CF_AVN_MoodLpBlueNValueSet 0 "0x0x000~0x0FF:Blue Color 0~255 (User Selection)" 255 "0x0x000~0x0FF:Blue Color 0~255 (User Selection)" 256 "0x100~0x1FF:Blue Color 0~255 (Expert Recommendation)" 511 "0x100~0x1FF:Blue Color 0~255 (Expert Recommendation)" 512 "Default" 1023 "Invalid" ;
VAL_ 274 CF_AVN_MoodLpBrightNValueSet 0 "Default" 1 "Off" 2 "Level 1" 3 "Level 2" 4 "Level 3" 5 "Level 4" 6 "Level 5" 7 "Level 6" 8 "Level 7" 9 "Level 8" 10 "Level 9" 11 "Level 10" 12 "Reserved" 13 "Reserved" 14 "Reserved" 15 "Invalid" ;
VAL_ 274 CF_AVN_HBANValueSet 0 "Default" 1 "Off" 2 "On" 3 "Invalid" ;
VAL_ 274 CF_AVN_IFSActVehSpd_Set 0 "Default" 1 "Vehicle Speed Function Off" 2 "10km_h" 3 "20km_h" 4 "30km_h" 5 "40km_h" 6 "50km_h" 7 "60km_h" 8 "70km_h" 9 "80km_h" 10 "90km_h" 11 "100km_h" 12 "Reserved" 13 "Reserved" 14 "Reserved" 15 "Invalid" ;
VAL_ 274 C_MoodLpDrivingNValue 0 "Default" 1 "OFF" 2 "ON" 3 "Invalid" ;
VAL_ 274 HU_DrivingPostureAssistUSMSet 0 "Default" 1 "Off" 2 "10min" 3 "20min" 4 "30min" 5 "40min" 6 "50min" 7 "60min" 8 "RESERVED" 9 "RESERVED" 10 "RESERVED" 11 "RESERVED" 12 "RESERVED" 13 "RESERVED" 14 "RESERVED" 15 "Invalid" ;
VAL_ 274 C_MoodLPDrivemodeNValue 0 "Default" 1 "Off" 2 "On" 3 "Invalid" ;
VAL_ 274 CF_AVN_SVMAutoOnNvalueSet 0 "Default" 1 "Off" 2 "On" 3 "Invalid" ;
VAL_ 274 CF_AVN_DAW_LVDANValueSet 0 "Default" 1 "Off" 2 "On" 3 "Invalid" ;
VAL_ 274 CF_AVN_Clu3dDepthSet 0 "Default" 1 "Off" 2 "Weak" 3 "Mid" 4 "Strong" 5 "Reserved" 6 "Reserved" 7 "Invalid" ;
VAL_ 274 C_MoodLpFadeNValue 0 "Default" 1 "Off" 2 "On" 3 "Invalid" ;
VAL_ 274 HU_DrvCushAirSprtUSMSet 0 "Default" 1 "Off" 2 "Low" 3 "Mid" 4 "High" 5 "RESERVED" 6 "RESERVED" 7 "Invalid" ;
VAL_ 274 HU_AstCushAirSprtUSMSet 0 "Default" 1 "Off" 2 "Low" 3 "Mid" 4 "High" 5 "RESERVED" 6 "RESERVED" 7 "Invalid" ;
VAL_ 274 HU_DrvStrchMassageSwSet 0 "Default" 1 "Off" 2 "On" 3 "Invalid" ;
VAL_ 274 HU_DrvStrchMassageModeUSMSet 0 "Default" 1 "Mode 1" 2 "Mode 2" 3 "Mode 3" 4 "Mode 4" 5 "Mode 5" 6 "RESERVED" 7 "Invalid" ;
VAL_ 274 HU_DrvStrchMassageStrengthUSMSet 0 "Default" 1 "Weak" 2 "Normal" 3 "Strong" 4 "RESERVED" 5 "RESERVED" 6 "RESERVED" 7 "Invalid" ;
VAL_ 274 HU_DrvStrchMassageTimeUSMSet 0 "Default" 1 "Short" 2 "Normal" 3 "Long" 4 "RESERVED" 5 "RESERVED" 6 "RESERVED" 7 "Invalid" ;
VAL_ 274 HU_AstStrchMassageSwSet 0 "Default" 1 "Off" 2 "On" 3 "Invalid" ;
VAL_ 274 HU_AstStrchMassageModeUSMSet 0 "Default" 1 "Mode 1" 2 "Mode 2" 3 "Mode 3" 4 "Mode 4" 5 "Mode 5" 6 "RESERVED" 7 "Invalid" ;
VAL_ 274 HU_AstStrchMassageStrengthUSMSet 0 "Default" 1 "Weak" 2 "Normal" 3 "Strong" 4 "RESERVED" 5 "RESERVED" 6 "RESERVED" 7 "Invalid" ;
VAL_ 274 HU_AstStrchMassageTimeUSMSet 0 "Default" 1 "Short" 2 "Normal" 3 "Long" 4 "RESERVED" 5 "RESERVED" 6 "RESERVED" 7 "Invalid" ;
VAL_ 274 CF_AVN_CluWelcomeSnd 0 "Default" 1 "Off" 2 "On" 3 "Invalid" ;
VAL_ 274 CF_AVN_CluServiceReminderSet 0 "Default" 1 "Off" 2 "On" 3 "Invalid" ;
VAL_ 274 CF_AVN_CluTransmissionDisp 0 "Default" 1 "Off" 2 "On" 3 "Invalid" ;
VAL_ 274 CF_AVN_CluWiperLight 0 "Default" 1 "Off" 2 "On" 3 "Invalid" ;
VAL_ 274 CF_AVN_CluRoadInfoGuide 0 "Default" 1 "Off" 2 "On" 3 "Invalid" ;
VAL_ 274 CF_AVN_CluUserSettingPeriod 0 "0~99month" 1 "0~99month" 2 "0~99month" 3 "0~99month" 4 "0~99month" 5 "0~99month" 6 "0~99month" 7 "0~99month" 8 "0~99month" 9 "0~99month" 10 "0~99month" 11 "0~99month" 12 "0~99month" 13 "0~99month" 14 "0~99month" 15 "0~99month" 16 "0~99month" 17 "0~99month" 18 "0~99month" 19 "0~99month" 20 "0~99month" 21 "0~99month" 22 "0~99month" 23 "0~99month" 24 "0~99month" 25 "0~99month" 26 "0~99month" 27 "0~99month" 28 "0~99month" 29 "0~99month" 30 "0~99month" 31 "0~99month" 32 "0~99month" 33 "0~99month" 34 "0~99month" 35 "0~99month" 36 "0~99month" 37 "0~99month" 38 "0~99month" 39 "0~99month" 40 "0~99month" 41 "0~99month" 42 "0~99month" 43 "0~99month" 44 "0~99month" 45 "0~99month" 46 "0~99month" 47 "0~99month" 48 "0~99month" 49 "0~99month" 50 "0~99month" 51 "0~99month" 52 "0~99month" 53 "0~99month" 54 "0~99month" 55 "0~99month" 56 "0~99month" 57 "0~99month" 58 "0~99month" 59 "0~99month" 60 "0~99month" 61 "0~99month" 62 "0~99month" 63 "0~99month" 64 "0~99month" 65 "0~99month" 66 "0~99month" 67 "0~99month" 68 "0~99month" 69 "0~99month" 70 "0~99month" 71 "0~99month" 72 "0~99month" 73 "0~99month" 74 "0~99month" 75 "0~99month" 76 "0~99month" 77 "0~99month" 78 "0~99month" 79 "0~99month" 80 "0~99month" 81 "0~99month" 82 "0~99month" 83 "0~99month" 84 "0~99month" 85 "0~99month" 86 "0~99month" 87 "0~99month" 88 "0~99month" 89 "0~99month" 90 "0~99month" 91 "0~99month" 92 "0~99month" 93 "0~99month" 94 "0~99month" 95 "0~99month" 96 "0~99month" 97 "0~99month" 98 "0~99month" 99 "0~99month" 100 "Reserved" 101 "Reserved" 102 "Reserved" 103 "Reserved" 104 "Reserved" 105 "Reserved" 106 "Reserved" 107 "Reserved" 108 "Reserved" 109 "Reserved" 110 "Reserved" 111 "Reserved" 112 "Reserved" 113 "Reserved" 114 "Reserved" 115 "Reserved" 116 "Reserved" 117 "Reserved" 118 "Reserved" 119 "Reserved" 120 "Reserved" 121 "Reserved" 122 "Reserved" 123 "Reserved" 124 "Reserved" 125 "Reserved" 126 "Reserved" 127 "Invalid" ;
VAL_ 274 CF_AVN_CluFuelEconUnit_mi 0 "Default" 1 "US gallon" 2 "UK gallon" 3 "Reserved" ;
VAL_ 274 CF_AVN_CluFuelEconUnit_km 0 "Default" 1 "km/L, km/kg, km/kWh" 2 "L/100km, kg/100km, kWh/100km" 3 "Reserved" ;
VAL_ 274 CF_AVN_CluUserSettingDistance 0 "0x0x0~0x1869F:0~9999km_mi" 99999 "0x0x0~0x1869F:0~9999km_mi" 131071 "Invalid" ;
VAL_ 686 HU_Car_Crc1Val 0 "0x0x0~0xFFFF:CRCValue" 65535 "0x0x0~0xFFFF:CRCValue" ;
VAL_ 686 HU_Car_AlvCnt1Val 0 "0x0x0~0xFF:AlvCntValue" 255 "0x0x0~0xFF:AlvCntValue" ;
VAL_ 686 HU_MKBD_ModeSwitch 0 "Key off" 1 "AVNT mode on" 2 "DATC mode on" 3 "Invalid" ;
VAL_ 686 HU_VehiclePwr 0 "Key out or Audio OFF" 1 "Not used" 2 "ACC or Audio ON" 3 "KBD Wake-up" 4 "Waiting for Good-Bye (Key out or Audio OFF)" 5 "Not used" 6 "Not used" 7 "Not used" 8 "Not used" 9 "Not used" 10 "Not used" 11 "Not used" 12 "Not used" 13 "Not used" 14 "Not used" 15 "Invalid" ;
VAL_ 686 HU_BtnShowReq 0 "default" 1 "on" 2 "off" 3 "reserved" 4 "reserved" 5 "reserved" 6 "reserved" 7 "invalid" ;
VAL_ 686 HU_ADMSettingState 0 "ADM On (Setting Vaule in HU)" 1 "ADM Off" 2 "Reserved" 3 "Reserved" 4 "Reserved" 5 "Reserved" 6 "Reserved" 7 "Invalid" ;
VAL_ 686 HU_PwrState 0 "Default" 1 "Normal On" 2 "ADM" 3 "Wait for door open" 4 "Logic Off" 5 "Remote Engine On" 6 "Reserved" 7 "Reserved" 8 "Reserved" 9 "Reserved" 10 "Reserved" 11 "Reserved" 12 "Reserved" 13 "Reserved" 14 "Reserved" 15 "Invalid" ;
VAL_ 686 HU_LCDState 0 "Default" 1 "On" 2 "Off" 3 "RESERVED" 4 "RESERVED" 5 "RESERVED" 6 "RESERVED" 7 "Invalid" ;
VAL_ 957 BLTN_CAM_FD_STAT_Crc1Val 0 "0x0x0~0xFFFF:CRCValue" 65535 "0x0x0~0xFFFF:CRCValue" ;
VAL_ 957 BLTN_CAM_Prk_Oprable_Time 0 "0x0x0~0xFB:the hours of Park Mode Operatable" 251 "0x0x0~0xFB:the hours of Park Mode Operatable" 252 "RESERVED" 253 "Auxiliary Battery is not connected. - Auxiliary Battery applicable on this vehicle model" 254 "Auxiliary Battery is not connected. ? Auxiliary Battery not applicable on this vehicle model" 255 "Invalid" ;
VAL_ 957 BLTN_CAM_Prk_Oprable_Time_Max 0 "0x0x0~0xFB:the hours of Park Mode Operatable" 251 "0x0x0~0xFB:the hours of Park Mode Operatable" 252 "RESERVED" 253 "Auxiliary Battery is not connected. - Auxiliary Battery applicable on this vehicle model" 254 "Auxiliary Battery is not connected. ? Auxiliary Battery not applicable on this vehicle model" 255 "Invalid" ;
VAL_ 957 BLTN_CAM_AuxBat_Conn_State 0 "Default" 1 "Auxiliary Battery is connected.(P-LBM, B-LBM, eAGM or R-LBM)" 2 "Auxiliary Battery is not connected. - Auxiliary Battery applicable on this vehicle model" 3 "Auxiliary Battery is not connected. ? Auxiliary Battery not applicable on this vehicle model" ;
VAL_ 957 BLTN_CAM_AuxBat_CapPer 0 "0x0x0~0x64: Aux Bat Capacity Percent(0~100%)" 100 "0x0x0~0x64: Aux Bat Capacity Percent(0~100%)" 100 "Reserved" 101 "Reserved" 102 "Reserved" 103 "Reserved" 104 "Reserved" 105 "Reserved" 106 "Reserved" 107 "Reserved" 108 "Reserved" 109 "Reserved" 110 "Reserved" 111 "Reserved" 112 "Reserved" 113 "Reserved" 114 "Reserved" 115 "Reserved" 116 "Reserved" 117 "Reserved" 118 "Reserved" 119 "Reserved" 120 "Reserved" 121 "Reserved" 122 "Reserved" 123 "Reserved" 124 "Reserved" 125 "Reserved" 126 "Reserved" 127 "Invalid" ;
VAL_ 957 BLTN_CAM_SWVerMajor 0 "ASCII Code Value (HEX)" 1 "ASCII Code Value (HEX)" 2 "ASCII Code Value (HEX)" 3 "ASCII Code Value (HEX)" 4 "ASCII Code Value (HEX)" 5 "ASCII Code Value (HEX)" 6 "ASCII Code Value (HEX)" 7 "ASCII Code Value (HEX)" 8 "ASCII Code Value (HEX)" 9 "ASCII Code Value (HEX)" 10 "ASCII Code Value (HEX)" 11 "ASCII Code Value (HEX)" 12 "ASCII Code Value (HEX)" 13 "ASCII Code Value (HEX)" 14 "ASCII Code Value (HEX)" 15 "ASCII Code Value (HEX)" ;
VAL_ 957 BLTN_CAM_SWVerMinor1 0 "Minor1 version, 0~99 dec" 1 "Minor1 version, 0~99 dec" 2 "Minor1 version, 0~99 dec" 3 "Minor1 version, 0~99 dec" 4 "Minor1 version, 0~99 dec" 5 "Minor1 version, 0~99 dec" 6 "Minor1 version, 0~99 dec" 7 "Minor1 version, 0~99 dec" 8 "Minor1 version, 0~99 dec" 9 "Minor1 version, 0~99 dec" 10 "Minor1 version, 0~99 dec" 11 "Minor1 version, 0~99 dec" 12 "Minor1 version, 0~99 dec" 13 "Minor1 version, 0~99 dec" 14 "Minor1 version, 0~99 dec" 15 "Minor1 version, 0~99 dec" 16 "Minor1 version, 0~99 dec" 17 "Minor1 version, 0~99 dec" 18 "Minor1 version, 0~99 dec" 19 "Minor1 version, 0~99 dec" 20 "Minor1 version, 0~99 dec" 21 "Minor1 version, 0~99 dec" 22 "Minor1 version, 0~99 dec" 23 "Minor1 version, 0~99 dec" 24 "Minor1 version, 0~99 dec" 25 "Minor1 version, 0~99 dec" 26 "Minor1 version, 0~99 dec" 27 "Minor1 version, 0~99 dec" 28 "Minor1 version, 0~99 dec" 29 "Minor1 version, 0~99 dec" 30 "Minor1 version, 0~99 dec" 31 "Minor1 version, 0~99 dec" 32 "Minor1 version, 0~99 dec" 33 "Minor1 version, 0~99 dec" 34 "Minor1 version, 0~99 dec" 35 "Minor1 version, 0~99 dec" 36 "Minor1 version, 0~99 dec" 37 "Minor1 version, 0~99 dec" 38 "Minor1 version, 0~99 dec" 39 "Minor1 version, 0~99 dec" 40 "Minor1 version, 0~99 dec" 41 "Minor1 version, 0~99 dec" 42 "Minor1 version, 0~99 dec" 43 "Minor1 version, 0~99 dec" 44 "Minor1 version, 0~99 dec" 45 "Minor1 version, 0~99 dec" 46 "Minor1 version, 0~99 dec" 47 "Minor1 version, 0~99 dec" 48 "Minor1 version, 0~99 dec" 49 "Minor1 version, 0~99 dec" 50 "Minor1 version, 0~99 dec" 51 "Minor1 version, 0~99 dec" 52 "Minor1 version, 0~99 dec" 53 "Minor1 version, 0~99 dec" 54 "Minor1 version, 0~99 dec" 55 "Minor1 version, 0~99 dec" 56 "Minor1 version, 0~99 dec" 57 "Minor1 version, 0~99 dec" 58 "Minor1 version, 0~99 dec" 59 "Minor1 version, 0~99 dec" 60 "Minor1 version, 0~99 dec" 61 "Minor1 version, 0~99 dec" 62 "Minor1 version, 0~99 dec" 63 "Minor1 version, 0~99 dec" 64 "Minor1 version, 0~99 dec" 65 "Minor1 version, 0~99 dec" 66 "Minor1 version, 0~99 dec" 67 "Minor1 version, 0~99 dec" 68 "Minor1 version, 0~99 dec" 69 "Minor1 version, 0~99 dec" 70 "Minor1 version, 0~99 dec" 71 "Minor1 version, 0~99 dec" 72 "Minor1 version, 0~99 dec" 73 "Minor1 version, 0~99 dec" 74 "Minor1 version, 0~99 dec" 75 "Minor1 version, 0~99 dec" 76 "Minor1 version, 0~99 dec" 77 "Minor1 version, 0~99 dec" 78 "Minor1 version, 0~99 dec" 79 "Minor1 version, 0~99 dec" 80 "Minor1 version, 0~99 dec" 81 "Minor1 version, 0~99 dec" 82 "Minor1 version, 0~99 dec" 83 "Minor1 version, 0~99 dec" 84 "Minor1 version, 0~99 dec" 85 "Minor1 version, 0~99 dec" 86 "Minor1 version, 0~99 dec" 87 "Minor1 version, 0~99 dec" 88 "Minor1 version, 0~99 dec" 89 "Minor1 version, 0~99 dec" 90 "Minor1 version, 0~99 dec" 91 "Minor1 version, 0~99 dec" 92 "Minor1 version, 0~99 dec" 93 "Minor1 version, 0~99 dec" 94 "Minor1 version, 0~99 dec" 95 "Minor1 version, 0~99 dec" 96 "Minor1 version, 0~99 dec" 97 "Minor1 version, 0~99 dec" 98 "Minor1 version, 0~99 dec" 99 "Minor1 version, 0~99 dec" 100 "Reserved" 101 "Reserved" 102 "Reserved" 103 "Reserved" 104 "Reserved" 105 "Reserved" 106 "Reserved" 107 "Reserved" 108 "Reserved" 109 "Reserved" 110 "Reserved" 111 "Reserved" 112 "Reserved" 113 "Reserved" 114 "Reserved" 115 "Reserved" 116 "Reserved" 117 "Reserved" 118 "Reserved" 119 "Reserved" 120 "Reserved" 121 "Reserved" 122 "Reserved" 123 "Reserved" 124 "Reserved" 125 "Reserved" 126 "Reserved" 127 "Invalid" ;
VAL_ 957 BLTN_CAM_SWVerMinor2 0 "Minor2 verion, 0~99 dec" 1 "Minor2 verion, 0~99 dec" 2 "Minor2 verion, 0~99 dec" 3 "Minor2 verion, 0~99 dec" 4 "Minor2 verion, 0~99 dec" 5 "Minor2 verion, 0~99 dec" 6 "Minor2 verion, 0~99 dec" 7 "Minor2 verion, 0~99 dec" 8 "Minor2 verion, 0~99 dec" 9 "Minor2 verion, 0~99 dec" 10 "Minor2 verion, 0~99 dec" 11 "Minor2 verion, 0~99 dec" 12 "Minor2 verion, 0~99 dec" 13 "Minor2 verion, 0~99 dec" 14 "Minor2 verion, 0~99 dec" 15 "Minor2 verion, 0~99 dec" 16 "Minor2 verion, 0~99 dec" 17 "Minor2 verion, 0~99 dec" 18 "Minor2 verion, 0~99 dec" 19 "Minor2 verion, 0~99 dec" 20 "Minor2 verion, 0~99 dec" 21 "Minor2 verion, 0~99 dec" 22 "Minor2 verion, 0~99 dec" 23 "Minor2 verion, 0~99 dec" 24 "Minor2 verion, 0~99 dec" 25 "Minor2 verion, 0~99 dec" 26 "Minor2 verion, 0~99 dec" 27 "Minor2 verion, 0~99 dec" 28 "Minor2 verion, 0~99 dec" 29 "Minor2 verion, 0~99 dec" 30 "Minor2 verion, 0~99 dec" 31 "Minor2 verion, 0~99 dec" 32 "Minor2 verion, 0~99 dec" 33 "Minor2 verion, 0~99 dec" 34 "Minor2 verion, 0~99 dec" 35 "Minor2 verion, 0~99 dec" 36 "Minor2 verion, 0~99 dec" 37 "Minor2 verion, 0~99 dec" 38 "Minor2 verion, 0~99 dec" 39 "Minor2 verion, 0~99 dec" 40 "Minor2 verion, 0~99 dec" 41 "Minor2 verion, 0~99 dec" 42 "Minor2 verion, 0~99 dec" 43 "Minor2 verion, 0~99 dec" 44 "Minor2 verion, 0~99 dec" 45 "Minor2 verion, 0~99 dec" 46 "Minor2 verion, 0~99 dec" 47 "Minor2 verion, 0~99 dec" 48 "Minor2 verion, 0~99 dec" 49 "Minor2 verion, 0~99 dec" 50 "Minor2 verion, 0~99 dec" 51 "Minor2 verion, 0~99 dec" 52 "Minor2 verion, 0~99 dec" 53 "Minor2 verion, 0~99 dec" 54 "Minor2 verion, 0~99 dec" 55 "Minor2 verion, 0~99 dec" 56 "Minor2 verion, 0~99 dec" 57 "Minor2 verion, 0~99 dec" 58 "Minor2 verion, 0~99 dec" 59 "Minor2 verion, 0~99 dec" 60 "Minor2 verion, 0~99 dec" 61 "Minor2 verion, 0~99 dec" 62 "Minor2 verion, 0~99 dec" 63 "Minor2 verion, 0~99 dec" 64 "Minor2 verion, 0~99 dec" 65 "Minor2 verion, 0~99 dec" 66 "Minor2 verion, 0~99 dec" 67 "Minor2 verion, 0~99 dec" 68 "Minor2 verion, 0~99 dec" 69 "Minor2 verion, 0~99 dec" 70 "Minor2 verion, 0~99 dec" 71 "Minor2 verion, 0~99 dec" 72 "Minor2 verion, 0~99 dec" 73 "Minor2 verion, 0~99 dec" 74 "Minor2 verion, 0~99 dec" 75 "Minor2 verion, 0~99 dec" 76 "Minor2 verion, 0~99 dec" 77 "Minor2 verion, 0~99 dec" 78 "Minor2 verion, 0~99 dec" 79 "Minor2 verion, 0~99 dec" 80 "Minor2 verion, 0~99 dec" 81 "Minor2 verion, 0~99 dec" 82 "Minor2 verion, 0~99 dec" 83 "Minor2 verion, 0~99 dec" 84 "Minor2 verion, 0~99 dec" 85 "Minor2 verion, 0~99 dec" 86 "Minor2 verion, 0~99 dec" 87 "Minor2 verion, 0~99 dec" 88 "Minor2 verion, 0~99 dec" 89 "Minor2 verion, 0~99 dec" 90 "Minor2 verion, 0~99 dec" 91 "Minor2 verion, 0~99 dec" 92 "Minor2 verion, 0~99 dec" 93 "Minor2 verion, 0~99 dec" 94 "Minor2 verion, 0~99 dec" 95 "Minor2 verion, 0~99 dec" 96 "Minor2 verion, 0~99 dec" 97 "Minor2 verion, 0~99 dec" 98 "Minor2 verion, 0~99 dec" 99 "Minor2 verion, 0~99 dec" 100 "Reserved" 101 "Reserved" 102 "Reserved" 103 "Reserved" 104 "Reserved" 105 "Reserved" 106 "Reserved" 107 "Reserved" 108 "Reserved" 109 "Reserved" 110 "Reserved" 111 "Reserved" 112 "Reserved" 113 "Reserved" 114 "Reserved" 115 "Reserved" 116 "Reserved" 117 "Reserved" 118 "Reserved" 119 "Reserved" 120 "Reserved" 121 "Reserved" 122 "Reserved" 123 "Reserved" 124 "Reserved" 125 "Reserved" 126 "Reserved" 127 "Invalid" ;
VAL_ 957 BLTN_CAM_SWVerMinor3 0 "Minor3 version, 0~99 dec" 1 "Minor3 version, 0~99 dec" 2 "Minor3 version, 0~99 dec" 3 "Minor3 version, 0~99 dec" 4 "Minor3 version, 0~99 dec" 5 "Minor3 version, 0~99 dec" 6 "Minor3 version, 0~99 dec" 7 "Minor3 version, 0~99 dec" 8 "Minor3 version, 0~99 dec" 9 "Minor3 version, 0~99 dec" 10 "Minor3 version, 0~99 dec" 11 "Minor3 version, 0~99 dec" 12 "Minor3 version, 0~99 dec" 13 "Minor3 version, 0~99 dec" 14 "Minor3 version, 0~99 dec" 15 "Minor3 version, 0~99 dec" 16 "Minor3 version, 0~99 dec" 17 "Minor3 version, 0~99 dec" 18 "Minor3 version, 0~99 dec" 19 "Minor3 version, 0~99 dec" 20 "Minor3 version, 0~99 dec" 21 "Minor3 version, 0~99 dec" 22 "Minor3 version, 0~99 dec" 23 "Minor3 version, 0~99 dec" 24 "Minor3 version, 0~99 dec" 25 "Minor3 version, 0~99 dec" 26 "Minor3 version, 0~99 dec" 27 "Minor3 version, 0~99 dec" 28 "Minor3 version, 0~99 dec" 29 "Minor3 version, 0~99 dec" 30 "Minor3 version, 0~99 dec" 31 "Minor3 version, 0~99 dec" 32 "Minor3 version, 0~99 dec" 33 "Minor3 version, 0~99 dec" 34 "Minor3 version, 0~99 dec" 35 "Minor3 version, 0~99 dec" 36 "Minor3 version, 0~99 dec" 37 "Minor3 version, 0~99 dec" 38 "Minor3 version, 0~99 dec" 39 "Minor3 version, 0~99 dec" 40 "Minor3 version, 0~99 dec" 41 "Minor3 version, 0~99 dec" 42 "Minor3 version, 0~99 dec" 43 "Minor3 version, 0~99 dec" 44 "Minor3 version, 0~99 dec" 45 "Minor3 version, 0~99 dec" 46 "Minor3 version, 0~99 dec" 47 "Minor3 version, 0~99 dec" 48 "Minor3 version, 0~99 dec" 49 "Minor3 version, 0~99 dec" 50 "Minor3 version, 0~99 dec" 51 "Minor3 version, 0~99 dec" 52 "Minor3 version, 0~99 dec" 53 "Minor3 version, 0~99 dec" 54 "Minor3 version, 0~99 dec" 55 "Minor3 version, 0~99 dec" 56 "Minor3 version, 0~99 dec" 57 "Minor3 version, 0~99 dec" 58 "Minor3 version, 0~99 dec" 59 "Minor3 version, 0~99 dec" 60 "Minor3 version, 0~99 dec" 61 "Minor3 version, 0~99 dec" 62 "Minor3 version, 0~99 dec" 63 "Minor3 version, 0~99 dec" 64 "Minor3 version, 0~99 dec" 65 "Minor3 version, 0~99 dec" 66 "Minor3 version, 0~99 dec" 67 "Minor3 version, 0~99 dec" 68 "Minor3 version, 0~99 dec" 69 "Minor3 version, 0~99 dec" 70 "Minor3 version, 0~99 dec" 71 "Minor3 version, 0~99 dec" 72 "Minor3 version, 0~99 dec" 73 "Minor3 version, 0~99 dec" 74 "Minor3 version, 0~99 dec" 75 "Minor3 version, 0~99 dec" 76 "Minor3 version, 0~99 dec" 77 "Minor3 version, 0~99 dec" 78 "Minor3 version, 0~99 dec" 79 "Minor3 version, 0~99 dec" 80 "Minor3 version, 0~99 dec" 81 "Minor3 version, 0~99 dec" 82 "Minor3 version, 0~99 dec" 83 "Minor3 version, 0~99 dec" 84 "Minor3 version, 0~99 dec" 85 "Minor3 version, 0~99 dec" 86 "Minor3 version, 0~99 dec" 87 "Minor3 version, 0~99 dec" 88 "Minor3 version, 0~99 dec" 89 "Minor3 version, 0~99 dec" 90 "Minor3 version, 0~99 dec" 91 "Minor3 version, 0~99 dec" 92 "Minor3 version, 0~99 dec" 93 "Minor3 version, 0~99 dec" 94 "Minor3 version, 0~99 dec" 95 "Minor3 version, 0~99 dec" 96 "Minor3 version, 0~99 dec" 97 "Minor3 version, 0~99 dec" 98 "Minor3 version, 0~99 dec" 99 "Minor3 version, 0~99 dec" 100 "Reserved" 101 "Reserved" 102 "Reserved" 103 "Reserved" 104 "Reserved" 105 "Reserved" 106 "Reserved" 107 "Reserved" 108 "Reserved" 109 "Reserved" 110 "Reserved" 111 "Reserved" 112 "Reserved" 113 "Reserved" 114 "Reserved" 115 "Reserved" 116 "Reserved" 117 "Reserved" 118 "Reserved" 119 "Reserved" 120 "Reserved" 121 "Reserved" 122 "Reserved" 123 "Reserved" 124 "Reserved" 125 "Reserved" 126 "Reserved" 127 "Invalid" ;
VAL_ 957 BLTN_CAM_FD_STAT_AlvCnt1Val 0 "0x0x0~0xFF:AlvCntValue" 255 "0x0x0~0xFF:AlvCntValue" ;
VAL_ 957 BLTN_CAM_SD_Card_Manufacturer 0 "SD Card not found" 1 "Micron-Genuine part" 2 "RESERVED" 3 "RESERVED" 4 "RESERVED" 5 "RESERVED" 6 "Unknown" 7 "Invalid" ;
VAL_ 957 BLTN_CAM_SD_Card_Cap_Class 0 "SD Card not found" 1 "64Gbyte Class" 2 "128Gbyte Class" 3 "256Gbyte Class" 4 "512Gbyte Class" 5 "1Tbyte Class" 6 "2Tbyte Class" 7 "Invalid" ;
VAL_ 957 BLTN_CAM_PMD_Oprable_Time 0 "0x0x0~0xFB:the hours of Parked Motion Detection Mode Operatable" 251 "0x0x0~0xFB:the hours of Parked Motion Detection Mode Operatable" 252 "RESERVED" 253 "Auxiliary Battery is not connected. - Auxiliary Battery applicable on this vehicle model" 254 "Auxiliary Battery Is not connected. ? Auxiliary Battery not applicable on this vehicle model" 255 "Invalid" ;
VAL_ 957 BLTN_CAM_PMD_Oprable_Time_Max 0 "0x0x0~0xFB:the hours of Parked Motion Detection Mode Operatable Max" 251 "0x0x0~0xFB:the hours of Parked Motion Detection Mode Operatable Max" 252 "RESERVED" 253 "Auxiliary Battery is not connected. - Auxiliary Battery applicable on this vehicle model" 254 "Auxiliary Battery is not connected. ? Auxiliary Battery not applicable on this vehicle model" 255 "Invalid" ;
VAL_ 957 BLTN_CAM_RecSta_PMD 0 "Off" 1 "Recording" 2 "RESERVED" 3 "Invalid" ;
VAL_ 957 BLTN_CAM_State 0 "BLTN_CAM Valid" 1 "BLTN_CAM Front Camera Invalid" 2 "BLTN_CAM Rear Camera Invalid" 3 "BLTN_CAM Front/Rear Camera Inavlid" 4 "BLTN_CAM Record Invalid" 5 "Reserved" 6 "Reserved" 7 "Reserved" 8 "Reserved" 9 "Reserved" 10 "Reserved" 11 "Reserved" 12 "Reserved" 13 "Reserved" 14 "Reserved" 15 "Invalid" ;
VAL_ 957 BLTN_CAM_SD_Card_State 0 "Good, SD card is OK.(Green State)" 1 "SD card replacement recommend.(Yallow State)" 2 "SD card replacement required.(Red State)" 3 "SD card unrecognizable or No SD card found." 4 "SD card total capacity spec less than 64GByte (Built-in Cam Support 64GByte or higher)" 5 "SD card file system is not for Built-in Cam(Built-in CAM only support exFAT filesystem)" 6 "SD card not enough free space, need more free space for built-in Cam(less than 32GByte, must be 32GB" 7 "SD card recognized but Health State is not available (Gray State)" 8 "SD card Unmounted" 9 "RESERVED" 10 "RESERVED" 11 "RESERVED" 12 "RESERVED" 13 "RESERVED" 14 "RESERVED" 15 "Invalid(Red State)" ;
VAL_ 957 BLTN_CAM_RecSta_OWD 0 "Off" 1 "Recording" 2 "Reserved" 3 "invalid" ;
VAL_ 957 BLTN_CAM_RecSta_DEV 0 "Off" 1 "Recording" 2 "Reserved" 3 "invalid" ;
VAL_ 957 BLTN_CAM_RecSta_MAR 0 "Off" 1 "Recording" 2 "Reserved" 3 "invalid" ;
VAL_ 957 BLTN_CAM_RecSta_TML 0 "Off" 1 "Recording" 2 "Reserved" 3 "invalid" ;
VAL_ 957 BLTN_CAM_RecSta_OWP 0 "Off" 1 "Recording" 2 "Reserved" 3 "invalid" ;
VAL_ 957 BLTN_CAM_RecSta_PEV 0 "Off" 1 "Recording" 2 "Reserved" 3 "invalid" ;
VAL_ 957 BLTN_CAM_Prk_EV_Cnt 0 "0x0x0~0xC8:the number of the Park Event Record(0~200)" 200 "0x0x0~0xC8:the number of the Park Event Record(0~200)" 201 "Reserved" 202 "Reserved" 203 "Reserved" 204 "Reserved" 205 "Reserved" 206 "Reserved" 207 "Reserved" 208 "Reserved" 209 "Reserved" 210 "Reserved" 211 "Reserved" 212 "Reserved" 213 "Reserved" 214 "Reserved" 215 "Reserved" 216 "Reserved" 217 "Reserved" 218 "Reserved" 219 "Reserved" 220 "Reserved" 221 "Reserved" 222 "Reserved" 223 "Reserved" 224 "Reserved" 225 "Reserved" 226 "Reserved" 227 "Reserved" 228 "Reserved" 229 "Reserved" 230 "Reserved" 231 "Reserved" 232 "Reserved" 233 "Reserved" 234 "Reserved" 235 "Reserved" 236 "Reserved" 237 "Reserved" 238 "Reserved" 239 "Reserved" 240 "Reserved" 241 "Reserved" 242 "Reserved" 243 "Reserved" 244 "Reserved" 245 "Reserved" 246 "Reserved" 247 "Reserved" 248 "Reserved" 249 "Reserved" 250 "Reserved" 251 "Reserved" 252 "Over than 200 count" 253 "Park Mode was not Excuted" 254 "Park Mode was not Supported" 255 "invalid" ;
VAL_ 957 BLTN_CAM_Prk_Oped_Time 0 "Park Mode was not Excuted" 1 "0x1~0xFB:the hours of Park Mode Operated" 251 "0x1~0xFB:the hours of Park Mode Operated" 252 "RESERVED" 253 "RESERVED" 254 "RESERVED" 255 "invalid" ;
VAL_ 69 HTCU_CtrlablSta 0 "Not ready" 1 "TCU Controllable" 2 "Not Used" 3 "Error Indicator" ;
VAL_ 69 HTCU_PrgrmSta 0 "PR_NML" 1 "PR_MED" 2 "PR_SPTY" 3 "PR_LD1" 4 "PR_LD2" 5 "PR_LD3" 6 "PR_DLD" 7 "PR_LD1_H" 8 "PR_LD2_H" 9 "PR_LD3_H" 10 "PR_PRT" 11 "PR_WRM_UP" 12 "PR_BLUE" 13 "PR_ECO_ATC" 14 "PR_LD_ATC" 15 "PR_LD_ATC_H" 16 "PR_HWY" 17 "PR_SOL_L" 18 "PR_SOL_M" 19 "PR_SOL_H" 20 "PR_REGEN" 21 "PR_TF_LO" 22 "PR_TCS" 23 "PR_LD_TCS" 24 "PR_DS" 25 "PR_EV_BLUE" 26 "PR_EV_NML" 27 "PR_EV_SOC_H" 28 "PR_EV_SOC_L" 29 "PR_EV_HWY" 30 "PR_SOS" 31 "PR_ECO_ATC_EV" 32 "PR_LD_ATC_EV" 33 "PR_LD_ATC_HI_EV" 34 "PR_LD2_ATC" 35 "PR_LD3_ATC" 36 "PR_LD2_ATC_H" 37 "PR_LD3_ATC_H" 38 "PR_EC_PRT" ;
VAL_ 69 HTCU_FsCltchLmphmActvSta 0 "Inactive" 1 "Active" 2 "Not used" 3 "Error Indicator" ;
VAL_ 69 HTCU_RapidKDReq 0 "Inactive" 1 "Active" 2 "Not used" 3 "Error Indicator" ;
VAL_ 69 HTCU_CurrGearSta 0 "If N or P are detected(No frictional conncetion)" 1 "1st speed" 2 "2nd speed" 3 "3rd speed" 4 "4th speed" 5 "5th speed" 6 "6th speed" 7 "Reverse" 8 "--" 15 "--" ;
VAL_ 69 HTCU_GearShftUpDisGSI 0 "Gear Shiftup Display Off" 1 "Gear Shiftup Display On" 2 "Not used" 3 "Error Indicator" ;
VAL_ 69 HTCU_GearShftDnDisGSI 0 "Gear Shiftdown Display Off" 1 "Gear Shiftdown Display On" 2 "Not used" 3 "Error Indicator" ;
VAL_ 69 HTCU_TrgtGearStaGSI 0 "--" 1 "1st speed" 2 "2nd speed" 3 "3rd speed" 4 "4th speed" 5 "5th speed" 6 "6th speed" 7 "--" 8 "--" 9 "--" ;
VAL_ 69 HTCU_SolBSta 0 "OFF" 1 "ON" 2 "Not used" 3 "Error Indicator" ;
VAL_ 69 HTCU_TrgtGearSta 0 "If N or P are detected(No frictional conncetion)" 1 "1st speed" 2 "2nd speed" 3 "3rd speed" 4 "4th speed" 5 "5th speed" 6 "6th speed" 7 "Reverse" 15 "--" ;
VAL_ 69 HTCU_RdySta 0 "Not ready" 1 "Ready" 2 "Not used" 3 "Error Indicator" ;
VAL_ 69 HTCU_GearChgSta 0 "Inactive" 1 "Active" 2 "Not used" 3 "Error Indicator" ;
VAL_ 69 HTCU_FltSta 0 "No fault" 1 "TCU Diagnostic failure" 2 "Not used" 3 "TCU Diagnostic failure & Limphome activated" 4 "OPU/EOP Diagnostic failure" 5 "TCU & OPU/EOP Diagnostic failure" 6 "Not used" 7 "TCU/OPU Diagnostic failure & Limphome activated" ;
VAL_ 69 HTCU_GearSlctrDis 0 "P" 1 "L" 2 "2" 3 "3" 4 "DS Mode" 5 "D" 6 "N" 7 "R" 8 "Sports mode / Manual Shift" 9 "Not display at Cluster" 10 "Sub-Rom Communication" 11 "Sub-Rom Communication Error" 12 "Paddle shift (D-Position)" 13 "Not used" 14 "Intermediate Position" 15 "Fault" ;
VAL_ 69 HTCU_PddlShftUpDn 0 "Not Request" 1 "Paddle Plus" 2 "Paddle Minus" 3 "RESERVED" ;
VAL_ 69 HTCU_FanCtrlReq 0 "Not Request" 1 "Request" 2 "Not Used" 3 "Error Indicator" ;
VAL_ 69 HTCU_TrgtShftClsCCanSta 0 "NO SHIFT" 1 "PON UP" 2 "POF UP" 3 "PON DN@HIGH SPEED(Not Used)" 4 "PON DN@LOW SPEED" 5 "POF DN" 6 "NSTP TO 5/4/3/2" 7 "NSTP TO 1" 8 "LOW_VSP SFT12" 9 "N-D 12" 10 "N-D 3456" 11 "N-D5(NOT USED)" 12 "N-R" 13 "N-N" 14 "PON DN WOT SHIFT (NOT USED)" 15 "PON DN SEMI SHIFT" 16 "D-N/R-N" 17 "RESERVED" 18 "RESERVED" 19 "RESERVED" 20 "FAILSAFE 2-3-4 SHIFT" 21 "RESERVED" 22 "RESERVED" 23 "RESERVED" 24 "RESERVED" 25 "RESERVED" 26 "RESERVED" 27 "RESERVED" 28 "RESERVED" 29 "RESERVED" 30 "RESERVED" 31 "RESERVED" ;
VAL_ 685 HU_BLTN_CAM_Crc2Val 0 "0x0x0~0xFFFF:CRCValue" 65535 "0x0x0~0xFFFF:CRCValue" ;
VAL_ 685 HU_BLTN_CAM_AlvCnt2Val 0 "0x0x0~0xFF:AlvCntValue" 255 "0x0x0~0xFF:AlvCntValue" ;
VAL_ 685 HU_BLTN_CAM_UI_Mode 0 "HU UI mode" 1 "Built-In Cam Mode(GUI or HU File Access)" 2 "Built-In Cam Setting Mode" 3 "RESERVED" 4 "RESERVED" 5 "RESERVED" 6 "RESERVED" 7 "RESERVED" 8 "RESERVED" 9 "RESERVED" 10 "RESERVED" 11 "RESERVED" 12 "RESERVED" 13 "RESERVED" 14 "RESERVED" 15 "Invalid" ;
VAL_ 685 HU_BLTN_CAM_Display 0 "AVN Mode" 1 "DVRS Mode" 2 "Popup Mode" 3 "RESERVED" 4 "RESERVED" 5 "Built-in Cam update mode" 6 "RESERVED" 7 "Invalid" ;
VAL_ 138 HU_GW_Crc1Val 0 "0x0x0~0xFFFF:CRCValue" 65535 "0x0x0~0xFFFF:CRCValue" ;
VAL_ 138 HU_TgSoc_QcChg_Set 0 "0x0x0~0xC8:PHY = HEX * 0.5" 200 "0x0x0~0xC8:PHY = HEX * 0.5" 201 "Reserved" 202 "Reserved" 203 "Reserved" 204 "Reserved" 205 "Reserved" 206 "Reserved" 207 "Reserved" 208 "Reserved" 209 "Reserved" 210 "Reserved" 211 "Reserved" 212 "Reserved" 213 "Reserved" 214 "Reserved" 215 "Reserved" 216 "Reserved" 217 "Reserved" 218 "Reserved" 219 "Reserved" 220 "Reserved" 221 "Reserved" 222 "Reserved" 223 "Reserved" 224 "Reserved" 225 "Reserved" 226 "Reserved" 227 "Reserved" 228 "Reserved" 229 "Reserved" 230 "Reserved" 231 "Reserved" 232 "Reserved" 233 "Reserved" 234 "Reserved" 235 "Reserved" 236 "Reserved" 237 "Reserved" 238 "Reserved" 239 "Reserved" 240 "Reserved" 241 "Reserved" 242 "Reserved" 243 "Reserved" 244 "Reserved" 245 "Reserved" 246 "Reserved" 247 "Reserved" 248 "Reserved" 249 "Reserved" 250 "Reserved" 251 "Reserved" 252 "Reserved" 253 "Reserved" 254 "Reserved" 255 "Invalid" ;
VAL_ 138 HU_UserApproval 0 "Initial Value" 1 "Approve" 2 "Reject" 3 "Start Trigger" 4 "Unrecognized Reject" 5 "RESERVED" 6 "RESERVED" 7 "RESERVED" 8 "RESERVED" 9 "RESERVED" 10 "RESERVED" 11 "RESERVED" 12 "RESERVED" 13 "RESERVED" 14 "Implement Check" 15 "Invalid" ;
VAL_ 138 HU_OtaInfomationReq 0 "Initial" 1 "Vehicle S/W Version" 2 "What's New (Text Only)" 3 "Download progress" 4 "Update progress" 5 "Reserved" 6 "Reserved" 7 "Reserved" 8 "Reserved" 9 "Reserved" 10 "Reserved" 11 "Reserved" 12 "Reserved" 13 "Reserved" 14 "Reserved" 15 "Invalid" ;
VAL_ 138 HU_ICU_RearDefSet 0 "Defog Off" 1 "Defog On" 2 "reserved" 3 "Invalid" ;
VAL_ 138 HU_CDMOpenCmd 0 "Default" 1 "CDM Open" 2 "CDM Close" 3 "Invalid" ;
VAL_ 138 C_PreCrankReq 0 "Default" 1 "Req On" 2 "Not Support" 3 "Invalid" ;
VAL_ 138 HU_GW_AlvCnt1Val 0 "0x0x0~0xFF:AlvCntValue" 255 "0x0x0~0xFF:AlvCntValue" ;
VAL_ 138 C_TeleAstSeatOpCmdIBOX 0 "Init" 1 "Unused" 2 "Seat Heat&Vent OFF" 3 "Seat_Vent_Low" 4 "Seat_Vent_Mid" 5 "Seat_Vent_High" 6 "Seat_Heat_Low" 7 "Seat_Heat_Mid" 8 "Seat_Heat_High" 9 "Unused" 10 "Unused" 11 "Unused" 12 "Unused" 13 "Unused" 14 "Unused" 15 "Invalid" ;
VAL_ 138 C_TeleDrvSeatOpCmdIBOX 0 "Init" 1 "Unused" 2 "Seat Heat&Vent OFF" 3 "Seat_Vent_Low" 4 "Seat_Vent_Mid" 5 "Seat_Vent_High" 6 "Seat_Heat_Low" 7 "Seat_Heat_Mid" 8 "Seat_Heat_High" 9 "Unused" 10 "Unused" 11 "Unused" 12 "Unused" 13 "Unused" 14 "Unused" 15 "Invalid" ;
VAL_ 138 C_TeleRRSeatOpCmdIBOX 0 "Init" 1 "Unused" 2 "Seat Heat&Vent OFF" 3 "Seat_Vent_Low" 4 "Seat_Vent_Mid" 5 "Seat_Vent_High" 6 "Seat_Heat_Low" 7 "Seat_Heat_Mid" 8 "Seat_Heat_High" 9 "Unused" 10 "Unused" 11 "Unused" 12 "Unused" 13 "Unused" 14 "Unused" 15 "Invalid" ;
VAL_ 138 C_TeleRLSeatOpCmdIBOX 0 "Init" 1 "Unused" 2 "Seat Heat&Vent OFF" 3 "Seat_Vent_Low" 4 "Seat_Vent_Mid" 5 "Seat_Vent_High" 6 "Seat_Heat_Low" 7 "Seat_Heat_Mid" 8 "Seat_Heat_High" 9 "Unused" 10 "Unused" 11 "Unused" 12 "Unused" 13 "Unused" 14 "Unused" 15 "Invalid" ;
VAL_ 138 HU_StrgWhlHeatingSet_VR 0 "Default" 1 "Step1 On" 2 "Step2 On" 3 "Off" 4 "Reserved" 5 "Reserved" 6 "Reserved" 7 "Invalid" ;
VAL_ 138 AVN_VGS_SET 0 "Default" 1 "Off" 2 "On" 3 "Invalid" ;
VAL_ 138 MODE_VCU_SET2 0 "Normal" 1 "Sport" 2 "Eco" 3 "Sport+" 4 "Smart" 5 "Snow" 6 "RESERVED" 7 "Invalid" ;
VAL_ 138 AVN_DriftMode_SET 0 "Default" 1 "Off" 2 "On" 3 "RESERVED" 4 "RESERVED" 5 "RESERVED" 6 "RESERVED" 7 "Invalid" ;
VAL_ 138 AVN_NduranceRace_SET 0 "Default" 1 "Off" 2 "On" 3 "RESERVED" 4 "RESERVED" 5 "RESERVED" 6 "RESERVED" 7 "Invalid" ;
VAL_ 138 AVN_MaxRange_SET 0 "Default" 1 "Off" 2 "On" 3 "RESERVED" 4 "RESERVED" 5 "RESERVED" 6 "RESERVED" 7 "Invalid" ;
VAL_ 138 HU_MKBD_TouchSensSet 0 "Default" 1 "Low" 2 "Mid" 3 "High" 4 "RESERVED" 5 "RESERVED" 6 "RESERVED" 7 "Invalid" ;
VAL_ 138 AVN_NTDBalance_SET 0 "Default" 1 "0%" 2 "10%" 3 "20%" 4 "30%" 5 "40%" 6 "50%" 7 "60%" 8 "70%" 9 "80%" 10 "90%" 11 "100%" 12 "RESERVED" 13 "RESERVED" 14 "RESERVED" 15 "Invalid" ;
VAL_ 138 LaunchControl_Activate_EV 0 "Default" 1 "Launch Control Off" 2 "Launch Control On" 3 "Invalid" ;
VAL_ 138 LaunchControl_GripLevel_Reset 0 "Default" 1 "Normal state" 2 "Reset" 3 "Invalid" ;
VAL_ 138 LaunchControl_GripLevel_Set 0 "Default" 1 "Grip level 1" 2 "Grip level 2" 3 "Grip level 3" 4 "Grip level 4" 5 "Grip level 5" 6 "Grip level 6" 7 "Invalid" ;
VAL_ 138 MODE_Drift_TCS_SET 0 "Default" 1 "Slip leve 01" 2 "Slip leve 02" 3 "Slip leve 03" 4 "Slip leve 04" 5 "Slip leve 05" 6 "Slip leve 06" 7 "Slip leve 07" 8 "Slip leve 08" 9 "Slip leve 09" 10 "Slip leve 10" 11 "RESERVED" 12 "RESERVED" 13 "RESERVED" 14 "RESERVED" 15 "Invalid" ;
VAL_ 138 MODE_Drift_VDC_SET 0 "Default" 1 "Beginner" 2 "Intermediate" 3 "Expert" 4 "RESERVED" 5 "RESERVED" 6 "RESERVED" 7 "Invalid" ;
VAL_ 138 HU_Popupdown_Req 0 "Default" 1 "Popup_request" 2 "Popdown_request" 3 "Invalid" ;
VAL_ 138 MODE_Drift_MDPS_SET 0 "Default" 1 "N-Mode" 2 "Drift Mode" 3 "Invalid" ;
VAL_ 138 MODE_Drift_ECS_SET 0 "Default" 1 "N-Mode" 2 "Drift Mode" 3 "Invalid" ;
VAL_ 138 MODE_Drift_ELSD_SET 0 "Default" 1 "Drift 1.5 way" 2 "Drift 2.0 way" 3 "Invalid" ;
VAL_ 138 HU_NCond_DragSet 0 "Default" 1 "N conditioning Drag Off" 2 "N conditioning Drag On" 3 "Invalid" ;
VAL_ 138 HU_NCond_TrackSet 0 "Default" 1 "N Conditioning Track Off" 2 "N Conditioning Track On" 3 "Invalid" ;
VAL_ 138 AVN_Npedal_SET 0 "Default" 1 "Off" 2 "On" 3 "RESERVED" 4 "RESERVED" 5 "RESERVED" 6 "RESERVED" 7 "Invalid" ;
VAL_ 138 AVN_NTD_SET 0 "Default" 1 "Off" 2 "On" 3 "RESERVED" 4 "RESERVED" 5 "RESERVED" 6 "RESERVED" 7 "Invalid" ;
VAL_ 138 HU_PopupAgreement_Push 0 "Normal(Off)" 1 "Popup_Yes" 2 "RESERVED" 3 "Invalid" ;
VAL_ 138 SWRC_Sensitivity_SET 0 "Medium(default)" 1 "Low" 2 "High" 3 "Invalid" ;
VAL_ 138 HU_ChgInCurrModSet 0 "Default" 1 "Maximum" 2 "Decreasing" 3 "Minimum" 4 "Reserved" 5 "Reserved" 6 "Reserved" 7 "Invalid" ;
VAL_ 138 HU_EV_WinterMode 0 "Winter mode Off" 1 "Winter mode On" 2 "Reserved" 3 "Invalid" ;
VAL_ 138 HU_TgSoc_ScChg_Set 0 "0x0x0~0xC8:PHY = HEX * 0.5" 200 "0x0x0~0xC8:PHY = HEX * 0.5" 201 "Reserved" 202 "Reserved" 203 "Reserved" 204 "Reserved" 205 "Reserved" 206 "Reserved" 207 "Reserved" 208 "Reserved" 209 "Reserved" 210 "Reserved" 211 "Reserved" 212 "Reserved" 213 "Reserved" 214 "Reserved" 215 "Reserved" 216 "Reserved" 217 "Reserved" 218 "Reserved" 219 "Reserved" 220 "Reserved" 221 "Reserved" 222 "Reserved" 223 "Reserved" 224 "Reserved" 225 "Reserved" 226 "Reserved" 227 "Reserved" 228 "Reserved" 229 "Reserved" 230 "Reserved" 231 "Reserved" 232 "Reserved" 233 "Reserved" 234 "Reserved" 235 "Reserved" 236 "Reserved" 237 "Reserved" 238 "Reserved" 239 "Reserved" 240 "Reserved" 241 "Reserved" 242 "Reserved" 243 "Reserved" 244 "Reserved" 245 "Reserved" 246 "Reserved" 247 "Reserved" 248 "Reserved" 249 "Reserved" 250 "Reserved" 251 "Reserved" 252 "Reserved" 253 "Reserved" 254 "Reserved" 255 "Invalid" ;
VAL_ 64 TCU_DcmlVehSpdKphVal 0 "Error Indicator" ;
VAL_ 64 TCU_GearLmpBlnkngReq 0 "No blink" 1 "Request lamp blinking" 2 "Not used" 3 "Error Indicator" ;
VAL_ 64 TCU_FuelCutInhbtReq 0 "No request" 1 "Fuel cut inhibition request from TCU" 2 "Not used" 3 "Error Indicator" ;
VAL_ 64 TCU_IdleUpReq 0 "No IDLE UP request" 1 "IDLE UP request" 2 "Not used" 3 "Error Indicator" ;
VAL_ 64 TCU_EngRpmDis 65535 "Error Indicator" ;
VAL_ 64 TCU_EngSpdIncReq 0 "No request" 1 "Engine speed increase is requested" 2 "Not used" 3 "Error Indicator" ;
VAL_ 64 TCU_ObdSta 0 "Default" 2 "Failure information of TCU" 3 "Failure information of TCU" 4 "MIL on request" 5 "MIL on request" 6 "Failure information of TCU & MIL on request" 7 "Failure information of TCU & MIL on request" ;
VAL_ 64 TCU_SprtyIndxSta 0 "Invalid" 1 "Step 1" 2 "Step 2" 3 "Step 3" 4 "Step 4" 5 "Step 5" 6 "Step 6" 7 "Step 7" 8 "Step 8" 9 "Step 9" 10 "Step 10" 11 "Step 11" 12 "Step 12" 13 "Step 13" 14 "Step 14" 15 "Step 15" 16 "Step 16" 17 "Step 17" 18 "Step 18" 19 "Step 19" 20 "Step 20" 21 "Step 21" 22 "Step 22" 23 "Step 23" 24 "Step 24" 25 "Step 25" 26 "Invalid" 27 "Invalid" 28 "Invalid" 29 "Invalid" 30 "Invalid" 31 "Invalid" ;
VAL_ 64 TCU_DrvngModDis 0 "Inactive" 1 "Normal" 2 "Eco" 3 "Eco+" 4 "Sport" 5 "Sport+" 6 "Snow" 7 "Reserved" ;
VAL_ 64 TCU_DrvngModReq 0 "Inactive" 1 "Normal" 2 "Eco" 3 "Eco+" 4 "Sport" 5 "Sport+" 6 "Snow" 7 "Reserved" ;
VAL_ 64 TCU_SmrtShftSta 0 "Smart Shift not Applied" 1 "Smart Shift Applied" 2 "Not used" 3 "Error Indicator" ;
VAL_ 64 TCU_FrtStcShftSta 0 "First static shift function is not activated." 1 "First static shift function is activated" 2 "Not used" 3 "Error Indicator" ;
VAL_ 64 TCU_IsgInhbtReq 0 "TCU inhibits the ISG function" 1 "ISG is available" 2 "Not used" 3 "Error Indicator" ;
VAL_ 64 TCU_CdaInhbtReq 0 "CDA transition is available" 1 "TCU prohibits CDA transition" 2 "Not used" 3 "Error Indicator" ;
VAL_ 64 TCU_BrkOnReq 0 "No request" 1 "Brake On Request" 2 "Not used" 3 "Error Indicator" ;
VAL_ 64 TCU_TqGrdntLimVal 255 "No torque gradient limitation" ;
VAL_ 64 TCU_NetrlCtrlSta 0 "No NC" 1 "NC Entry" 2 "NC Applied" 3 "NC Exit" ;
VAL_ 64 TCU_ShftPtrnSta 0 "Normal (ECO)" 1 "Uphill 1 (Optional)" 2 "Uphill 2 (Optional)" 3 "Reserved" 4 "Downhill 1 (Optional)" 5 "Cruise (Optional)" 6 "Cruise_Uphill 1 (Optional)" 7 "Cruise_Uphill 2 (Optional)" 8 "Active ECO (Optional)" 9 "Sport Drive (Optional)" 15 "None of the above" ;
VAL_ 64 TCU_VgisInhbtReq 0 "There’s no request from TCU" 1 "TCU inhibits ECU from changing VGIS status" 2 "Not used" 3 "Error Indicator" ;
VAL_ 64 TCU_EngTqIncReqVal 0 "No request" 2047 "Max. Increase" 2048 "reduction to 0 torque" ;
VAL_ 64 TCU_EPBReq 0 "No Request (default)" 1 "EPB Request" ;
VAL_ 64 IMT_EOLstate 0 "display gear info using 'TCU_GearSlctDis'" 1 "display gear info by alphabet 'E'" ;
VAL_ 64 IMT_DisCmd 0 "Not Display" 1 "Display (Not blinking)" 2 "Display (blinking)" 3 "Reserved" ;
VAL_ 64 DCT_RegenInhbt 0 "No Inhibit" 1 "Regen. Inhibit" 2 "Not Used" 3 "Error Indicator" ;
VAL_ 64 DCT_EngIdleReq 0 "No Request" 1 "Idle Request" 2 "Not Used" 3 "Error Indicator" ;
VAL_ 64 DCT_CltchState 0 "Drivetrain (Both Clutch) Open" 1 "Odd Clutch Slipping" 2 "Even Clutch Slipping" 3 "Clutch Locked" ;
VAL_ 64 DCT_FuelCutReq 0 "No request" 1 "Fuel Cut Request" 2 "Not Used" 3 "Error Indicator" ;
VAL_ 64 DCT_TqIncReq 0 "No Request" 1 "Torque increase Request" 2 "Not Used" 3 "Error Indicator" ;
VAL_ 64 DCT_ShftTqReq 0 "No request" 2047 "Max. Increase" 2048 "reduction to 0 torque" ;
VAL_ 64 TCU_GearSlctDis 0 "P" 1 "L" 2 "2" 3 "3" 4 "DS Mode" 5 "D" 6 "N" 7 "R" 8 "sports mode / manual shift / paddle shift" 9 "Not Display at Cluster" 10 "Sub-Rom Communication" 11 "Sub-Rom Communication Error" 12 "Paddle shift (D-position)" 13 "Reserved" 14 "Intermediate Position" 15 "fault" ;
VAL_ 64 TCU_Typ 0 "Reserved" 1 "Step A" 2 "CVT" 3 "DCT" 4 "AMT" 5 "eClutch (2pedal)" 6 "eClutch (3pedal)" ;
VAL_ 64 TCU_TqRdctnVal 0 "Max. reduction" 2047 "No reduction" 2048 "reduction to 0 torque" ;
VAL_ 64 TCU_GearStepTyp 3 "3 - Speed AT or DCT" 4 "4 - Speed AT or DCT" 5 "5 - Speed AT or DCT" 6 "6 - Speed AT or DCT" 7 "7- Speed AT or DCT" 8 "8 - Speed AT or DCT" ;
VAL_ 64 TCU_GearShftSta 0 "no gear change" 1 "gear change is active" 2 "Not used" 3 "Error Indicator" ;
VAL_ 64 TCU_TqCnvrtrSta 0 "No lock up control" 1 "Slip lock up" 2 "Fully lock up" 3 "Off slip lock up" ;
VAL_ 64 TCU_CurrGearSta 0 "if N or P are detected (no frictional connection)" 1 "1st speed" 2 "2nd speed" 3 "3rd speed" 4 "4th speed" 5 "5th speed" 6 "6th speed" 7 "7th speed" 8 "8th speed" 14 "Reverse speed" ;
VAL_ 64 TCU_TrgtGearSta 0 "if N or P are detected (no frictional connection)" 1 "1st speed" 2 "2nd speed" 3 "3rd speed" 4 "4th speed" 5 "5th speed" 6 "6th speed" 7 "7th speed" 8 "8th speed" 14 "Reverse speed" ;
VAL_ 64 TCU_CluTrgtGearSta 0 "if N or P are detected (no frictional connection)" 1 "1st speed" 2 "2nd speed" 3 "3rd speed" 4 "4th speed" 5 "5th speed" 6 "6th speed" 7 "7th speed" 8 "8th speed" 14 "Reverse speed" ;
VAL_ 64 TCH_EngTrgtGearSta 0 "if N or P are detected (no frictional connection)" 1 "1st speed" 2 "2nd speed" 3 "3rd speed" 4 "4th speed" 5 "5th speed" 6 "6th speed" 7 "7th speed" 8 "8th speed" 14 "Reverse speed" ;
VAL_ 64 TCU_EngTqLimVal 0 "Max. reduction" 2047 "No reduction" 2048 "reduction to 0 torque" ;
VAL_ 64 TCU_CluTrgtGearConfg 0 "TCU_TrgtGearSta" 1 "TCU_CluTrgtGearSta" 2 "Not Used" 3 "Error Indicator" ;
VAL_ 64 TCU_VehSpdKphVal 255 "Error Indicator" ;
